VERSION ""

NS_ :

BS_:

BU_: GWM SCMB_PSM HVAC_RCCM GENERIC_GWMWakeup SOBDMD_AHCM_FOH TRM _delete SODL RTM PDM SCMH SCMG RSM SODR DDM RGTM DSM SCME TSTR

BO_ 947 BodyInfo_3_MS1: 8 GWM
 SG_ DrStatDrvErrCnt_B_Stat : 19|1@0+ (1,0) [0|1] "SED" Vector__XXX
 SG_ TurnLghtRightOn_B_Stat : 35|1@0+ (1,0) [0|1] "SED" Vector__XXX
 SG_ TurnLghtLeftOn_B_Stat : 54|1@0+ (1,0) [0|1] "SED" Vector__XXX
 SG_ Backlit_LED_Status : 23|4@0+ (1,0) [0|15] "SED"  HVAC_RCCM,DDM,PDM
 SG_ FogLghtRearOn_B_Stat : 1|1@0+ (1,0) [0|1] "SED"  TRM
 SG_ ValetMode_D_Mem : 16|1@0+ (1,0) [0|1] "SED"  RGTM
 SG_ IgnKeyType_D_Actl : 39|4@0+ (1,0) [0|15] "SED"  RSM,SODL,SODR
 SG_ TurnLghtRight_D_Rq : 63|2@0+ (1,0) [0|3] "SED"  RSM,DDM,PDM,TRM
 SG_ Parklamp_Status : 3|2@0+ (1,0) [0|3] "SED"  HVAC_RCCM,TRM,PDM,DDM,SODL,SODR
 SG_ Litval : 47|8@0+ (1,0) [0|253] "SED"  HVAC_RCCM,DDM,PDM,SODL,SODR
 SG_ Key_In_Ignition_Stat : 11|1@0+ (1,0) [0|1] "SED"  RSM,SCMG,SCMH,DSM,RTM
 SG_ Ignition_Status : 7|4@0+ (1,0) [0|15] "SED"  SCMB_PSM,SCME,HVAC_RCCM,RSM,DDM,DSM,PDM,RGTM,RTM,SCMG,SCMH,TRM,SOBDMD_AHCM_FOH,SODL,SODR
 SG_ Dimming_Lvl : 31|8@0+ (1,0) [0|253] "SED"  HVAC_RCCM,DDM,PDM
 SG_ Day_Night_Status : 15|2@0+ (1,0) [0|3] "SED"  HVAC_RCCM,DDM,PDM
 SG_ Remote_Start_Status : 13|2@0+ (1,0) [0|3] "SED"  HVAC_RCCM,RSM
 SG_ DrStatTgate_B_Actl : 0|1@0+ (1,0) [0|1] "SED"  RSM,TRM,HVAC_RCCM
 SG_ DrStatRr_B_Actl : 49|1@0+ (1,0) [0|1] "SED"  HVAC_RCCM,RGTM,DDM,PDM,RSM
 SG_ DrStatRl_B_Actl : 48|1@0+ (1,0) [0|1] "SED"  HVAC_RCCM,RGTM,DDM,PDM,RSM
 SG_ DrStatPsngr_B_Actl : 60|1@0+ (1,0) [0|1] "SED"  RGTM,DDM,PDM,RSM,HVAC_RCCM
 SG_ DrStatInnrTgate_B_Actl : 58|1@0+ (1,0) [0|1] "SED"  TRM,RSM,HVAC_RCCM
 SG_ DrStatHood_B_Actl : 59|1@0+ (1,0) [0|1] "SED"  RSM
 SG_ DrStatDrv_B_Actl : 61|1@0+ (1,0) [0|1] "SED"  RGTM,HVAC_RCCM,DDM,PDM,RSM,DSM
 SG_ PrkBrkActv_B_Actl : 55|1@0+ (1,0) [0|1] "SED"  SODL,SODR
 SG_ LifeCycMde_D_Actl : 53|4@0+ (1,0) [0|15] "SED"  HVAC_RCCM,RGTM,TRM,RTM,DDM,PDM,SOBDMD_AHCM_FOH
 SG_ Delay_Accy : 57|1@0+ (1,0) [0|1] "SED"  DDM,PDM
 SG_ FogLghtFrontOn_B_Stat : 56|1@0+ (1,0) [0|1] "SED" Vector__XXX
 SG_ TurnLghtLeft_D_Rq : 9|2@0+ (1,0) [0|3] "SED"  RSM,DDM,PDM,TRM
 SG_ CrashEvnt_D_Stat : 34|2@0+ (1,0) [0|3] "SED"  HVAC_RCCM
 SG_ FuelPmpInhbt_B_Stat : 32|1@0+ (1,0) [0|1] "SED"  HVAC_RCCM
 SG_ BodySrvcRqd_B_Rq : 10|1@0+ (1,0) [0|1] "SED" Vector__XXX

BO_ 293 ClmtCtrlSeatSet_Stat_v2: 8 SCME
 SG_ ClmtCtrlSeat_SetStat_Psgr : 15|8@0+ (1,0) [0|254] "SED"  GWM,HVAC_RCCM
 SG_ ClmtCtrlSeat_SetStat_Dvr : 7|8@0+ (1,0) [0|254] "SED"  GWM,HVAC_RCCM

BO_ 292 ClmtCtrlSeatSet_Cmd: 8 HVAC_RCCM
 SG_ ClmtCtrlSeat_SetCmd_Psgr : 15|8@0+ (1,0) [0|254] "SED"  GWM,SCME
 SG_ ClmtCtrlSeat_SetCmd_Dvr : 7|8@0+ (1,0) [0|254] "SED"  GWM,SCME

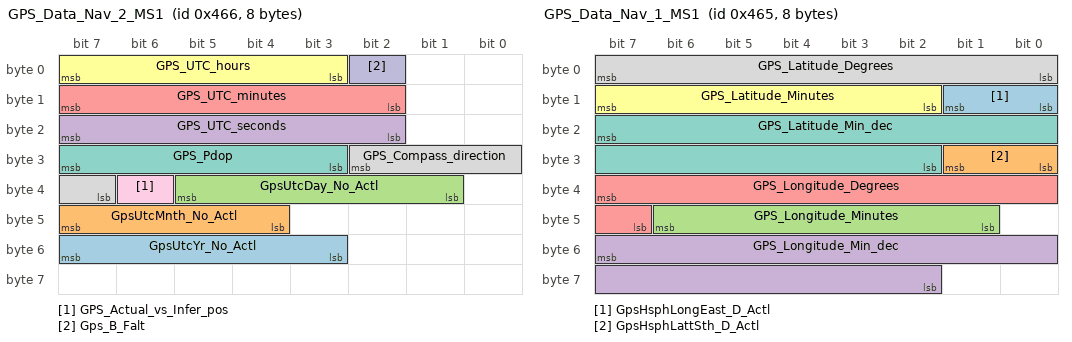
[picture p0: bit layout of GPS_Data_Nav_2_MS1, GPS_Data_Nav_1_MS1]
BO_ 1126 GPS_Data_Nav_2_MS1: 8 GWM
 SG_ GpsUtcYr_No_Actl : 55|5@0+ (1,2010) [2010|2040] "Year" Vector__XXX
 SG_ GpsUtcMnth_No_Actl : 47|4@0+ (1,1) [1|15] "Month" Vector__XXX
 SG_ GpsUtcDay_No_Actl : 37|5@0+ (1,1) [1|32] "Day" Vector__XXX
 SG_ GPS_UTC_seconds : 23|6@0+ (1,0) [0|59] "seconds" Vector__XXX
 SG_ GPS_UTC_minutes : 15|6@0+ (1,0) [0|59] "Minutes" Vector__XXX
 SG_ GPS_UTC_hours : 7|5@0+ (1,0) [0|23] "Hours" Vector__XXX
 SG_ GPS_Pdop : 31|5@0+ (0.2,0) [0|5.8] "unitless" Vector__XXX
 SG_ GPS_Compass_direction : 26|4@0+ (1,0) [0|15] "SED" Vector__XXX
 SG_ GPS_Actual_vs_Infer_pos : 38|1@0+ (1,0) [0|1] "SED" Vector__XXX
 SG_ Gps_B_Falt : 2|1@0+ (1,0) [0|1] "SED" Vector__XXX

BO_ 1125 GPS_Data_Nav_1_MS1: 8 GWM
 SG_ GpsHsphLongEast_D_Actl : 9|2@0+ (1,0) [0|3] "SED" Vector__XXX
 SG_ GpsHsphLattSth_D_Actl : 25|2@0+ (1,0) [0|3] "SED" Vector__XXX
 SG_ GPS_Longitude_Minutes : 46|6@0+ (1,0) [0|61] "Minutes" Vector__XXX
 SG_ GPS_Longitude_Min_dec : 55|14@0+ (0.0001,0) [0|1.6381] "Minutes" Vector__XXX
 SG_ GPS_Longitude_Degrees : 39|9@0+ (1,-179) [-179|330] "Degrees" Vector__XXX
 SG_ GPS_Latitude_Minutes : 15|6@0+ (1,0) [0|61] "Minutes" Vector__XXX
 SG_ GPS_Latitude_Min_dec : 23|14@0+ (0.0001,0) [0|1.6381] "Minutes" Vector__XXX
 SG_ GPS_Latitude_Degrees : 7|8@0+ (1,-89) [-89|164] "Degrees" Vector__XXX

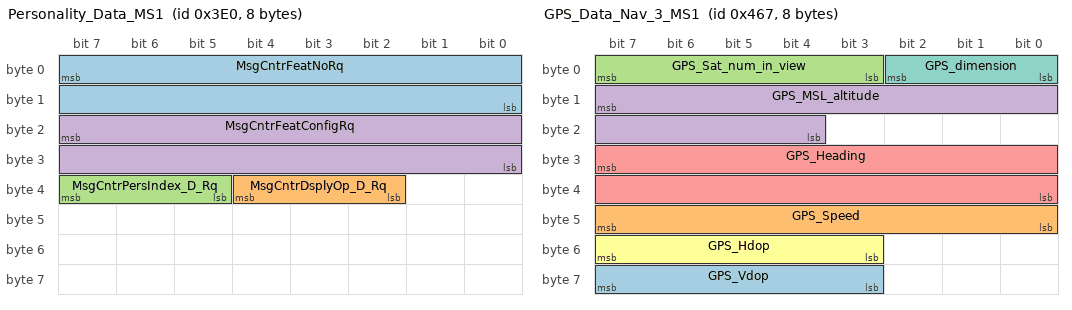
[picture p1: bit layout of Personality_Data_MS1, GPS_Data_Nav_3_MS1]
BO_ 992 Personality_Data_MS1: 8 GWM
 SG_ MsgCntrFeatNoRq : 7|16@0+ (1,0) [0|65535] "Number"  HVAC_RCCM,PDM,DDM,DSM
 SG_ MsgCntrDsplyOp_D_Rq : 36|3@0+ (1,0) [0|7] "SED"  HVAC_RCCM,PDM,DDM,DSM
 SG_ MsgCntrPersIndex_D_Rq : 39|3@0+ (1,0) [0|7] "SED"  HVAC_RCCM,PDM,DDM,DSM
 SG_ MsgCntrFeatConfigRq : 23|16@0+ (1,0) [0|65535] "unitless"  HVAC_RCCM,PDM,DDM,DSM

BO_ 1127 GPS_Data_Nav_3_MS1: 8 GWM
 SG_ GPS_Vdop : 63|5@0+ (0.2,0) [0|5.8] "unitless" Vector__XXX
 SG_ GPS_Speed : 47|8@0+ (1,0) [0|253] "MPH" Vector__XXX
 SG_ GPS_Sat_num_in_view : 7|5@0+ (1,0) [0|29] "unitless" Vector__XXX
 SG_ GPS_MSL_altitude : 15|12@0+ (10,-20460) [-20460|20470] "feet" Vector__XXX
 SG_ GPS_Heading : 31|16@0+ (0.01,0) [0|655.33] "Degrees" Vector__XXX
 SG_ GPS_Hdop : 55|5@0+ (0.2,0) [0|5.8] "unitless" Vector__XXX
 SG_ GPS_dimension : 2|3@0+ (1,0) [0|7] "SED" Vector__XXX

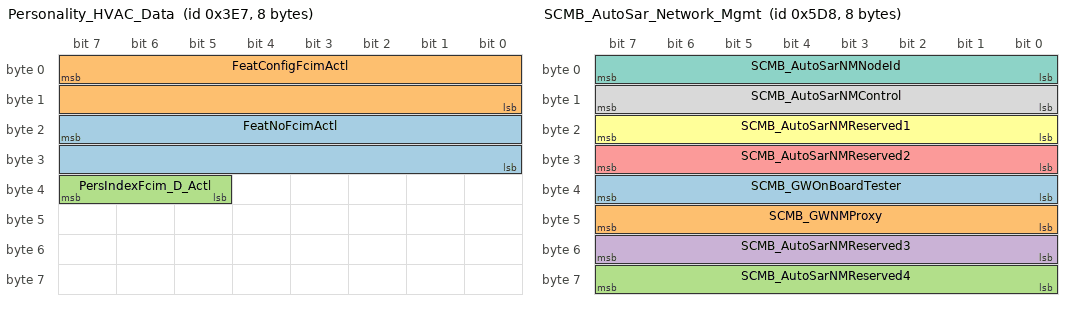
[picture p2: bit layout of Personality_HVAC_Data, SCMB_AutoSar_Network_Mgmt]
BO_ 999 Personality_HVAC_Data: 8 HVAC_RCCM
 SG_ FeatNoFcimActl : 23|16@0+ (1,0) [0|65535] "Number"  GWM
 SG_ FeatConfigFcimActl : 7|16@0+ (1,0) [0|65535] "Undefined"  GWM
 SG_ PersIndexFcim_D_Actl : 39|3@0+ (1,0) [0|7] "SED"  GWM

BO_ 1998 TesterPhysicalResSODR: 8 SODR
 SG_ TesterPhysicalResSODR : 7|64@0+ (1,0) [0|1.84467E+019] "unitless"  TSTR

BO_ 1990 TesterPhysicalReqSODR: 8 TSTR
 SG_ TesterPhysicalReqSODR : 7|64@0+ (1,0) [0|1.84467E+019] "unitless"  SODR

BO_ 1996 TesterPhysicalResSODL: 8 SODL
 SG_ TesterPhysicalResSODL : 7|64@0+ (1,0) [0|1.84467E+019] "unitless"  TSTR

BO_ 1988 TesterPhysicalReqSODL: 8 TSTR
 SG_ TesterPhysicalReqSODL : 7|64@0+ (1,0) [0|1.84467E+019] "unitless"  SODL

BO_ 2027 TesterPhysicalResAHCM: 8 SOBDMD_AHCM_FOH
 SG_ TesterPhysicalResAHCM : 7|64@0+ (1,0) [0|1.84467E+019] "unitless"  TSTR

BO_ 1496 SCMB_AutoSar_Network_Mgmt: 8 SCMB_PSM
 SG_ SCMB_GWOnBoardTester : 39|8@0+ (1,0) [0|255] "unitless"  GWM
 SG_ SCMB_GWNMProxy : 47|8@0+ (1,0) [0|255] "unitless"  GWM
 SG_ SCMB_AutoSarNMReserved4 : 63|8@0+ (1,0) [0|255] "unitless"  GWM
 SG_ SCMB_AutoSarNMReserved3 : 55|8@0+ (1,0) [0|255] "unitless"  GWM
 SG_ SCMB_AutoSarNMReserved2 : 31|8@0+ (1,0) [0|255] "unitless"  GWM
 SG_ SCMB_AutoSarNMReserved1 : 23|8@0+ (1,0) [0|255] "unitless"  GWM
 SG_ SCMB_AutoSarNMNodeId : 7|8@0+ (1,0) [0|255] "unitless"  GWM
 SG_ SCMB_AutoSarNMControl : 15|8@0+ (1,0) [0|255] "unitless"  GWM

BO_ 847 PwrFoldSeats: 8 GENERIC_GWMWakeup
 SG_ FldngSeatPwOffOk_B_Stat : 7|1@0+ (1,0) [0|0] "SED"  GWM

BO_ 2019 TesterPhysicalReqAHCM: 8 TSTR
 SG_ TesterPhysicalReqAHCM : 7|64@0+ (1,0) [0|1.84467E+019] "unitless"  SOBDMD_AHCM_FOH

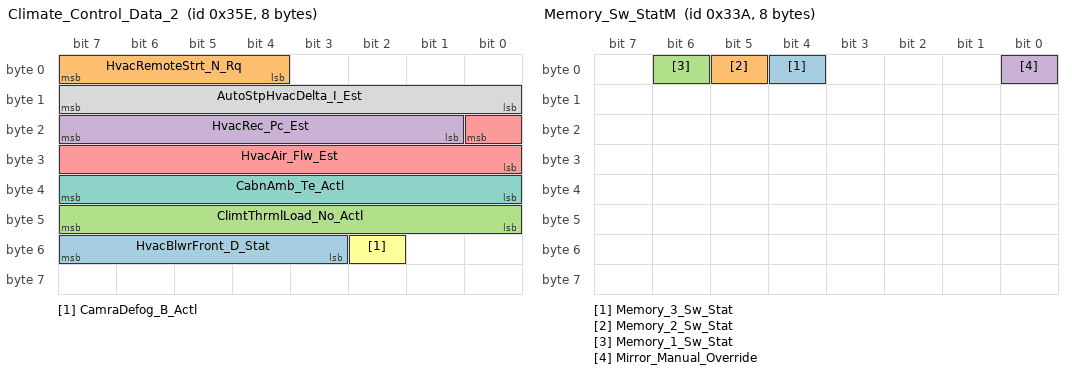
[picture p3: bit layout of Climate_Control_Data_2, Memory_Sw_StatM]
BO_ 862 Climate_Control_Data_2: 8 HVAC_RCCM
 SG_ HvacBlwrFront_D_Stat : 55|5@0+ (1,0) [0|31] "SED"  SCME,RGTM,GWM
 SG_ HvacRemoteStrt_N_Rq : 7|4@0+ (100,450) [450|1950] "RPM"  GWM
 SG_ ClimtThrmlLoad_No_Actl : 47|8@0+ (1,0) [0|254] "unitless"  GWM
 SG_ HvacRec_Pc_Est : 23|7@0+ (1,0) [0|127] "Percent"  GWM
 SG_ HvacAir_Flw_Est : 16|9@0+ (0.5,0) [0|255.5] "liter/second"  GWM
 SG_ CamraDefog_B_Actl : 50|1@0+ (1,0) [0|1] "SED"  GWM
 SG_ CabnAmb_Te_Actl : 39|8@0+ (0.5,-57) [-57|70] "degreesC"  SCME,RGTM,SOBDMD_AHCM_FOH,GWM
 SG_ AutoStpHvacDelta_I_Est : 15|8@0+ (1,-192) [-192|62] "ampere"  GWM

BO_ 828 Pass_Window_Stat: 8 PDM
 SG_ RearPassWindowPos : 4|3@0+ (1,0) [0|7] "SED"  RGTM,HVAC_RCCM,GWM
 SG_ PassWindowPosition : 7|3@0+ (1,0) [0|7] "SED"  RGTM,HVAC_RCCM,GWM

BO_ 1909 TesterPhysicalReqRGTM: 8 TSTR
 SG_ TesterPhysicalReqRGTM : 7|64@0+ (1,0) [0|1.84467E+019] "unitless"  RGTM

BO_ 1917 TesterPhysicalResRGTM: 8 RGTM
 SG_ TesterPhysicalResRGTM : 7|64@0+ (1,0) [0|1.84467E+019] "unitless"  TSTR

BO_ 1860 TesterPhysicalReqDSM: 8 TSTR
 SG_ TesterPhysicalReqDSM : 7|64@0+ (1,0) [0|1.84467E+019] "unitless"  DSM

BO_ 1868 TesterPhysicalResDSM: 8 DSM
 SG_ TesterPhysicalResDSM : 7|64@0+ (1,0) [0|1.84467E+019] "unitless"  TSTR

BO_ 1918 TesterPhysicalResSCME: 8 SCME
 SG_ TesterPhysicalResSCME : 7|64@0+ (1,0) [0|1.84467E+019] "unitless"  TSTR

BO_ 1910 TesterPhysicalReqSCME: 8 TSTR
 SG_ TesterPhysicalReqSCME : 7|64@0+ (1,0) [0|1.84467E+019] "unitless"  SCME

BO_ 1814 TesterPhysicalReqGWM_M1: 8 TSTR
 SG_ TesterPhysicalReqGWM_M1 : 7|64@0+ (1,0) [0|1.84467E+019] "unitless"  GWM

BO_ 1822 TesterPhysicalResGWM_MS1: 8 GWM
 SG_ TesterPhysicalResGWM_M1 : 7|64@0+ (1,0) [0|1.84467E+019] "unitless"  TSTR

BO_ 826 Memory_Sw_StatM: 8 DDM
 SG_ Memory_3_Sw_Stat : 4|1@0+ (1,0) [0|1] "SED"  GWM,DSM
 SG_ Memory_2_Sw_Stat : 5|1@0+ (1,0) [0|1] "SED"  GWM,DSM
 SG_ Memory_1_Sw_Stat : 6|1@0+ (1,0) [0|1] "SED"  GWM,DSM
 SG_ Mirror_Manual_Override : 0|1@0+ (1,0) [0|1] "SED"  GWM,DSM

BO_ 1289 AHCM_Network_MgmtM: 8 SOBDMD_AHCM_FOH
 SG_ AHCM_Network_Mgmt : 7|8@0+ (1,0) [0|254] "unitless" Vector__XXX

BO_ 853 Clmt_Button_Stat1: 8 HVAC_RCCM
 SG_ Front_AUTO_Blwr_Lvl : 60|2@0+ (1,0) [0|3] "SED"  GWM
 SG_ FrontMnu_Buttn_Stat : 49|1@0+ (1,0) [0|1] "SED"  GWM
 SG_ RHS_Cond_Seat_Status : 63|3@0+ (1,0) [0|7] "SED"  GWM
 SG_ LHS_Cond_Seat_Status : 10|3@0+ (1,0) [0|7] "SED"  GWM
 SG_ Htd_Strg_Whl_Status : 27|2@0+ (1,0) [0|3] "SED"  GWM
 SG_ Htd_Strg_Whl_Btn_Stt : 29|2@0+ (1,0) [0|3] "SED"  GWM
 SG_ Defrost_Btn_Stt : 3|2@0+ (1,0) [0|3] "SED"  GWM
 SG_ CC_Fr_Btn_User_Adj : 15|5@0+ (1,0) [0|31] "SED"  GWM
 SG_ RHS_Htd_Seat_Btn_Stt : 53|2@0+ (1,0) [0|3] "SED"  GWM
 SG_ RHS_Cld_Seat_Btn_Stt : 55|2@0+ (1,0) [0|3] "SED"  GWM
 SG_ Outside_Btn_Stt : 47|2@0+ (1,0) [0|3] "SED"  GWM
 SG_ LHS_Htd_Seat_Btn_Stt : 39|2@0+ (1,0) [0|3] "SED"  GWM
 SG_ LHS_Cld_Seat_Btn_Stt : 25|2@0+ (1,0) [0|3] "SED"  GWM
 SG_ Htd_Frt_Wsh_Btn_Stt : 31|2@0+ (1,0) [0|3] "SED"  GWM
 SG_ Auto_Recirc_Btn_Stt : 5|2@0+ (1,0) [0|3] "SED"  GWM
 SG_ Windscreen_Btn_Stt : 51|2@0+ (1,0) [0|3] "SED"  GWM
 SG_ Panel_Btn_Stt : 45|2@0+ (1,0) [0|3] "SED"  GWM
 SG_ Front_Power_Btn_Stt : 17|2@0+ (1,0) [0|3] "SED"  GWM
 SG_ Front_AUTO_Btn_Stt : 21|2@0+ (1,0) [0|3] "SED"  GWM
 SG_ Floor_Btn_Stt : 23|2@0+ (1,0) [0|3] "SED"  GWM
 SG_ Dual_Button_Stt : 1|2@0+ (1,0) [0|3] "SED"  GWM
 SG_ AC_Btn_Stt : 7|2@0+ (1,0) [0|3] "SED"  GWM
 SG_ Recirc_Btn_Stt : 41|2@0+ (1,0) [0|3] "SED"  RGTM,GWM
 SG_ Rear_Defrost_Btn_Stt : 43|2@0+ (1,0) [0|3] "SED"  GWM
 SG_ My_Temp_Btn_Stt : 33|2@0+ (1,0) [0|3] "SED"  GWM
 SG_ Max_Defrost_Btn_Stt : 35|2@0+ (1,0) [0|3] "SED"  GWM
 SG_ Max_AC_Btn_Stt : 37|2@0+ (1,0) [0|3] "SED"  GWM
 SG_ Front_AUTO_Label : 19|2@0+ (1,0) [0|3] "SED"  GWM

BO_ 1034 GGCC_Config_Mgmt_ID_1_MS1: 8 GWM
 SG_ VehicleGGCCData : 7|64@0+ (1,0) [0|1.84467E+019] "mixed"  HVAC_RCCM,TRM,PDM,SOBDMD_AHCM_FOH,RTM,DDM,RGTM,SODL,SODR

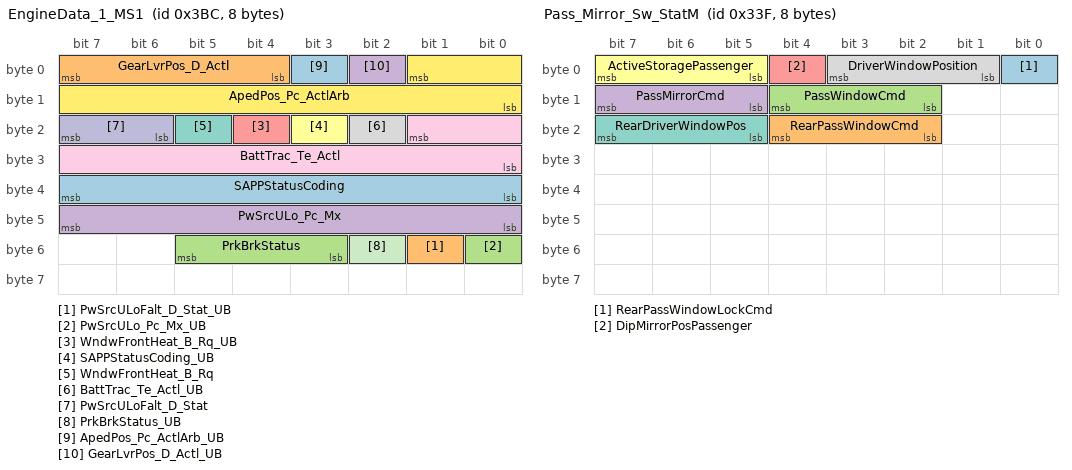
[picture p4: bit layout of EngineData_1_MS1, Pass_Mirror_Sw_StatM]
BO_ 956 EngineData_1_MS1: 8 GWM
 SG_ SAPPStatusCoding : 39|8@0+ (1,0) [0|255] "unitless" Vector__XXX
 SG_ PwSrcULoFalt_D_Stat_UB : 49|1@0+ (1,0) [0|1] "SED"  HVAC_RCCM
 SG_ PwSrcULo_Pc_Mx_UB : 48|1@0+ (1,0) [0|1] "SED"  HVAC_RCCM
 SG_ PwSrcULo_Pc_Mx : 47|8@0+ (0.4,0) [0|101.6] "%"  HVAC_RCCM
 SG_ WndwFrontHeat_B_Rq_UB : 20|1@0+ (1,0) [0|1] "SED"  HVAC_RCCM
 SG_ SAPPStatusCoding_UB : 19|1@0+ (1,0) [0|1] "SED" Vector__XXX
 SG_ WndwFrontHeat_B_Rq : 21|1@0+ (1,0) [0|1] "SED"  HVAC_RCCM
 SG_ BattTrac_Te_Actl_UB : 18|1@0+ (1,0) [0|1] "SED"  HVAC_RCCM
 SG_ BattTrac_Te_Actl : 17|10@0+ (0.5,-50) [-50|460.5] "degC"  HVAC_RCCM
 SG_ PwSrcULoFalt_D_Stat : 23|2@0+ (1,0) [0|3] "SED"  HVAC_RCCM
 SG_ PrkBrkStatus_UB : 50|1@0+ (1,0) [0|1] "SED"  HVAC_RCCM
 SG_ ApedPos_Pc_ActlArb : 1|10@0+ (0.1,0) [0|102.3] "%"  HVAC_RCCM
 SG_ ApedPos_Pc_ActlArb_UB : 3|1@0+ (1,0) [0|1] "SED"  HVAC_RCCM
 SG_ GearLvrPos_D_Actl : 7|4@0+ (1,0) [0|15] "SED"  HVAC_RCCM,RGTM,DSM,SCMG,SCMH,DDM,PDM,SODR,SODL
 SG_ PrkBrkStatus : 53|3@0+ (1,0) [0|7] "SED"  HVAC_RCCM
 SG_ GearLvrPos_D_Actl_UB : 2|1@0+ (1,0) [0|1] "SED"  HVAC_RCCM,RGTM,DSM,SCMG,SCMH,DDM,PDM,SODL,SODR

BO_ 831 Pass_Mirror_Sw_StatM: 8 DDM
 SG_ RearPassWindowLockCmd : 0|1@0+ (1,0) [0|1] "SED"  GWM,PDM
 SG_ RearPassWindowCmd : 20|3@0+ (1,0) [0|7] "SED"  GWM,PDM
 SG_ PassWindowCmd : 12|3@0+ (1,0) [0|7] "SED"  GWM,PDM
 SG_ PassMirrorCmd : 15|3@0+ (1,0) [0|7] "SED"  GWM,PDM
 SG_ DipMirrorPosPassenger : 4|1@0+ (1,0) [0|1] "SED"  GWM,PDM
 SG_ ActiveStoragePassenger : 7|3@0+ (1,0) [0|7] "SED"  GWM,PDM
 SG_ RearDriverWindowPos : 23|3@0+ (1,0) [0|7] "SED"  RGTM,HVAC_RCCM,GWM
 SG_ DriverWindowPosition : 3|3@0+ (1,0) [0|7] "SED"  RGTM,HVAC_RCCM,GWM

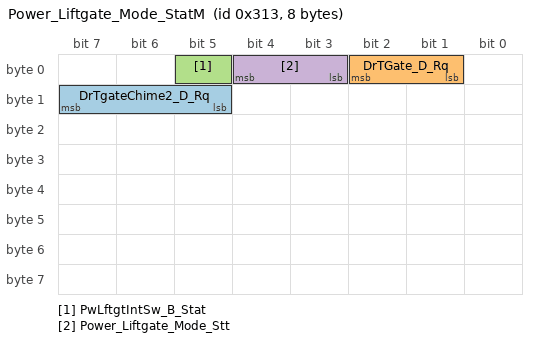
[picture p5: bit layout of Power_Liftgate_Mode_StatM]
BO_ 787 Power_Liftgate_Mode_StatM: 8 RGTM
 SG_ DrTgateChime2_D_Rq : 15|3@0+ (1,0) [0|7] "SED"  GWM
 SG_ DrTGate_D_Rq : 2|2@0+ (1,0) [0|3] "SED"  HVAC_RCCM,GWM
 SG_ PwLftgtIntSw_B_Stat : 5|1@0+ (1,0) [0|1] "SED"  GWM
 SG_ Power_Liftgate_Mode_Stt : 4|2@0+ (1,0) [0|3] "SED"  GWM

BO_ 1291 DSM_Network_MgmtM: 8 DSM
 SG_ DSM_Network_Mgmt : 7|8@0+ (1,0) [0|254] "unitless"  PDM,DDM

CM_ SG_ 947 Dimming_Lvl "Refer to Vehicle Interior Illum Dimming Ctrl Sys Eng Spec, Table 2

";
CM_ SG_ 947 PrkBrkActv_B_Actl "Signal not transmitted on vehicles with electric park brake. ";
CM_ BO_ 1126 "HS3 APIM Sync Gen3 Tx 0x463.  FrameGateway to 0x466 on HS1, HS2, HS3 and MS1.";
CM_ BO_ 1125 "HS3 APIM Sync Gen3 Tx 0x462.  FrameGateway to 0x465 on HS1, HS2, HS3 and MS1.";
CM_ BO_ 1127 "HS3 APIM Sync Gen3 Tx 0x464.  FrameGateway to 0x467 on HS1, HS2, HS3 and MS1.";
CM_ BO_ 828 "Set GenSigSendType = NoSigSendType (Cyclic) for the following signals, D.Card 3/31/08
Driver_Lock_Sw_Stat
";
CM_ SG_ 1034 VehicleGGCCData "RCMGenSigTimeout=6000";
CM_ SG_ 956 ApedPos_Pc_ActlArb "ABSGenSigTimeoutTime=1000";
BA_DEF_ BO_  "FrameGatewayNetwork" STRING ;
BA_DEF_ BO_  "FrameGatewayMS1" HEX 0 1407;
BA_DEF_ BO_  "NetworkInitialization" ENUM  "No","Yes";
BA_DEF_ BO_  "FrameGatewayId" HEX 0 1407;
BA_DEF_ BO_  "EventRateOfChange" INT 10 10000;
BA_DEF_ BO_  "GenMsgStartDelayTime" INT 0 10000;
BA_DEF_ BO_  "GenMsgNrOfRepetition" INT 0 100;
BA_DEF_ BO_  "GenMsgDelayTime" INT 0 1000;
BA_DEF_ BO_  "GenMsgCycleTime" INT 0 100000;
BA_DEF_ BO_  "GenMsgSendType" ENUM  "FixedPeriodic","Event","EnabledPeriodic","NotUsed","NotUsed","EventPeriodic","NotUsed","NotUsed","NoMsgSendType";
BA_DEF_ SG_  "U_P702_MY2021_Tx" ENUM  "No","Yes";
BA_DEF_ SG_  "U_CX727_MY2021_Tx" ENUM  "No","Yes";
BA_DEF_ SG_  "U_VN127_MY20_Tx" ENUM  "No","Yes";
BA_DEF_ SG_  "U_H567_MY20_Tx" ENUM  "No","Yes";
BA_DEF_ SG_  "U_CX430_MY2021_Tx" ENUM  "No","Yes";
BA_DEF_ SG_  "U_U611_U625_MY20_Phev_Tx" ENUM  "No","Yes";
BA_DEF_ SG_  "U_B562_MY18_Diesel_Tx" ENUM  "No","Yes";
BA_DEF_ SG_  "U_CX482_CX483_MY20_Tx" ENUM  "No","Yes";
BA_DEF_ SG_  "U_U611_U625_MY20_Hev_Tx" ENUM  "No","Yes";
BA_DEF_ SG_  "U_U611_U625_MY20_Gas_Tx" ENUM  "No","Yes";
BA_DEF_ SG_  "U_B500_MY18_Diesel_Tx" ENUM  "No","Yes";
BA_DEF_ SG_  "U_B500_MY18_Gas_Tx" ENUM  "No","Yes";
BA_DEF_ SG_  "U_C490_MY18_Tx" ENUM  "No","Yes";
BA_DEF_ SG_  "U_B562_MY18_Gas_Tx" ENUM  "No","Yes";
BA_DEF_ SG_  "U_C519_MY18_5_Gas_Tx" ENUM  "No","Yes";
BA_DEF_ SG_  "U_C519_MY18_5_Diesel_Tx" ENUM  "No","Yes";
BA_DEF_ SG_  "U_B515_MCA_MY17_Gas_Tx" ENUM  "No","Yes";
BA_DEF_ SG_  "U_B515_MCA_MY17_Diesel_Tx" ENUM  "No","Yes";
BA_DEF_ SG_  "U_B479_MY17_Diesel_Tx" ENUM  "No","Yes";
BA_DEF_ SG_  "U_B479_MY17_Gas_Tx" ENUM  "No","Yes";
BA_DEF_ SG_  "U_P702_MY2021_Rx" ENUM  "No","Yes";
BA_DEF_ SG_  "U_CX727_MY2021_Rx" ENUM  "No","Yes";
BA_DEF_ SG_  "U_VN127_MY20_Rx" ENUM  "No","Yes";
BA_DEF_ SG_  "U_H567_MY20_Rx" ENUM  "No","Yes";
BA_DEF_ SG_  "U_CX430_MY2021_Rx" ENUM  "No","Yes";
BA_DEF_ SG_  "U_U611_U625_MY20_Phev_Rx" ENUM  "No","Yes";
BA_DEF_ SG_  "U_B562_MY18_Diesel_Rx" ENUM  "No","Yes";
BA_DEF_ SG_  "U_CX482_CX483_MY20_Rx" ENUM  "No","Yes";
BA_DEF_ SG_  "U_U611_U625_MY20_Hev_Rx" ENUM  "No","Yes";
BA_DEF_ SG_  "U_U611_U625_MY20_Gas_Rx" ENUM  "No","Yes";
BA_DEF_ SG_  "U_B500_MY18_Diesel_Rx" ENUM  "No","Yes";
BA_DEF_ SG_  "U_B500_MY18_Gas_Rx" ENUM  "No","Yes";
BA_DEF_ SG_  "U_C490_MY18_Rx" ENUM  "No","Yes";
BA_DEF_ SG_  "U_B562_MY18_Gas_Rx" ENUM  "No","Yes";
BA_DEF_ SG_  "U_LC1_B515_MY17_Gas_Rx" ENUM  "No","Yes";
BA_DEF_ SG_  "U_LC1_B515_MY17_Diesel_Rx" ENUM  "No","Yes";
BA_DEF_ SG_  "U_C519_MY18_5_Gas_Rx" ENUM  "No","Yes";
BA_DEF_ SG_  "U_C519_MY18_5_Diesel_Rx" ENUM  "No","Yes";
BA_DEF_ SG_  "U_B515_MCA_MY17_Gas_Rx" ENUM  "No","Yes";
BA_DEF_ SG_  "U_B515_MCA_MY17_Diesel_Rx" ENUM  "No","Yes";
BA_DEF_ SG_  "U_B479_MY17_Diesel_Rx" ENUM  "No","Yes";
BA_DEF_ SG_  "U_B479_MY17_Gas_Rx" ENUM  "No","Yes";
BA_DEF_ SG_  "U_B562LC_MY15_Gas_Rx" ENUM  "No","Yes";
BA_DEF_ SG_  "U_B562LC_MY15_Diesel_Rx" ENUM  "No","Yes";
BA_DEF_ SG_  "GenSigStartValue" HEX 0 268435455;
BA_DEF_ SG_  "MetaData" ENUM  "No","Yes";
BA_DEF_ SG_  "ContentDependant" ENUM  "No","Yes";
BA_DEF_ SG_  "GenSigStartValueInteger" INT 0 1000000000;
BA_DEF_ SG_  "UsedOnPgmDBC" ENUM  "No","Yes";
BA_DEF_ SG_  "CrossOver_InfoCAN" ENUM  "No","Yes";
BA_DEF_ SG_  "WakeupSignal" ENUM  "No","Yes";
BA_DEF_ SG_  "GenSigInactiveValue" INT 0 100000;
BA_DEF_ SG_  "GenSigSendType" ENUM  "Cyclic","OnWrite","vector_leerstring","OnChange","vector_leerstring","IfActive","vector_leerstring","NoSigSendType";
BA_DEF_ BO_  "AuthFreshnessCounterSyncAttempt" INT 0 2;
BA_DEF_ BO_  "GenMsgRoutingTimeoutTime" INT 0 5000;
BA_DEF_ BO_  "MessageGateway" ENUM  "No","Yes";
BA_DEF_ BO_  "NmAsrMessage" ENUM  "No","Yes";
BA_DEF_ BO_  "DiagState" ENUM  "No","Yes";
BA_DEF_ BO_  "DiagRequest" ENUM  "No","Yes";
BA_DEF_ BO_  "DiagResponse" ENUM  "No","Yes";
BA_DEF_ BO_  "NmMessage" ENUM  "No","Yes";
BA_DEF_ BO_  "GenMsgILSupport" ENUM  "No","Yes";
BA_DEF_DEF_  "FrameGatewayNetwork" "NONE";
BA_DEF_DEF_  "FrameGatewayMS1" 0;
BA_DEF_DEF_  "NetworkInitialization" "Yes";
BA_DEF_DEF_  "FrameGatewayId" 0;
BA_DEF_DEF_  "EventRateOfChange" 10000;
BA_DEF_DEF_  "GenMsgStartDelayTime" 0;
BA_DEF_DEF_  "GenMsgNrOfRepetition" 1;
BA_DEF_DEF_  "GenMsgDelayTime" 20;
BA_DEF_DEF_  "GenMsgCycleTime" 0;
BA_DEF_DEF_  "GenMsgSendType" "NoMsgSendType";
BA_DEF_DEF_  "U_P702_MY2021_Tx" "No";
BA_DEF_DEF_  "U_CX727_MY2021_Tx" "No";
BA_DEF_DEF_  "U_VN127_MY20_Tx" "No";
BA_DEF_DEF_  "U_H567_MY20_Tx" "No";
BA_DEF_DEF_  "U_CX430_MY2021_Tx" "No";
BA_DEF_DEF_  "U_U611_U625_MY20_Phev_Tx" "No";
BA_DEF_DEF_  "U_B562_MY18_Diesel_Tx" "No";
BA_DEF_DEF_  "U_CX482_CX483_MY20_Tx" "No";
BA_DEF_DEF_  "U_U611_U625_MY20_Hev_Tx" "No";
BA_DEF_DEF_  "U_U611_U625_MY20_Gas_Tx" "No";
BA_DEF_DEF_  "U_B500_MY18_Diesel_Tx" "No";
BA_DEF_DEF_  "U_B500_MY18_Gas_Tx" "No";
BA_DEF_DEF_  "U_C490_MY18_Tx" "No";
BA_DEF_DEF_  "U_B562_MY18_Gas_Tx" "No";
BA_DEF_DEF_  "U_C519_MY18_5_Gas_Tx" "No";
BA_DEF_DEF_  "U_C519_MY18_5_Diesel_Tx" "No";
BA_DEF_DEF_  "U_B515_MCA_MY17_Gas_Tx" "No";
BA_DEF_DEF_  "U_B515_MCA_MY17_Diesel_Tx" "No";
BA_DEF_DEF_  "U_B479_MY17_Diesel_Tx" "No";
BA_DEF_DEF_  "U_B479_MY17_Gas_Tx" "No";
BA_DEF_DEF_  "U_P702_MY2021_Rx" "No";
BA_DEF_DEF_  "U_CX727_MY2021_Rx" "No";
BA_DEF_DEF_  "U_VN127_MY20_Rx" "No";
BA_DEF_DEF_  "U_H567_MY20_Rx" "No";
BA_DEF_DEF_  "U_CX430_MY2021_Rx" "No";
BA_DEF_DEF_  "U_U611_U625_MY20_Phev_Rx" "No";
BA_DEF_DEF_  "U_B562_MY18_Diesel_Rx" "No";
BA_DEF_DEF_  "U_CX482_CX483_MY20_Rx" "No";
BA_DEF_DEF_  "U_U611_U625_MY20_Hev_Rx" "No";
BA_DEF_DEF_  "U_U611_U625_MY20_Gas_Rx" "No";
BA_DEF_DEF_  "U_B500_MY18_Diesel_Rx" "No";
BA_DEF_DEF_  "U_B500_MY18_Gas_Rx" "No";
BA_DEF_DEF_  "U_C490_MY18_Rx" "No";
BA_DEF_DEF_  "U_B562_MY18_Gas_Rx" "No";
BA_DEF_DEF_  "U_LC1_B515_MY17_Gas_Rx" "No";
BA_DEF_DEF_  "U_LC1_B515_MY17_Diesel_Rx" "No";
BA_DEF_DEF_  "U_C519_MY18_5_Gas_Rx" "No";
BA_DEF_DEF_  "U_C519_MY18_5_Diesel_Rx" "No";
BA_DEF_DEF_  "U_B515_MCA_MY17_Gas_Rx" "No";
BA_DEF_DEF_  "U_B515_MCA_MY17_Diesel_Rx" "No";
BA_DEF_DEF_  "U_B479_MY17_Diesel_Rx" "No";
BA_DEF_DEF_  "U_B479_MY17_Gas_Rx" "No";
BA_DEF_DEF_  "U_B562LC_MY15_Gas_Rx" "No";
BA_DEF_DEF_  "U_B562LC_MY15_Diesel_Rx" "No";
BA_DEF_DEF_  "GenSigStartValue" 0;
BA_DEF_DEF_  "MetaData" "No";
BA_DEF_DEF_  "ContentDependant" "No";
BA_DEF_DEF_  "GenSigStartValueInteger" 0;
BA_DEF_DEF_  "UsedOnPgmDBC" "Yes";
BA_DEF_DEF_  "CrossOver_InfoCAN" "No";
BA_DEF_DEF_  "WakeupSignal" "No";
BA_DEF_DEF_  "GenSigInactiveValue" 0;
BA_DEF_DEF_  "GenSigSendType" "NoSigSendType";
BA_DEF_DEF_  "AuthFreshnessCounterSyncAttempt" 2;
BA_DEF_DEF_  "GenMsgRoutingTimeoutTime" 0;
BA_DEF_DEF_  "MessageGateway" "No";
BA_DEF_DEF_  "NmAsrMessage" "No";
BA_DEF_DEF_  "DiagState" "No";
BA_DEF_DEF_  "DiagRequest" "No";
BA_DEF_DEF_  "DiagResponse" "No";
BA_DEF_DEF_  "NmMessage" "No";
BA_DEF_DEF_  "GenMsgILSupport" "Yes";
BA_ "GenMsgSendType" BO_ 947 5;
BA_ "GenMsgCycleTime" BO_ 947 1000;
BA_ "FrameGatewayNetwork" BO_ 947 "HS1_CAN";
BA_ "FrameGatewayId" BO_ 947 947;
BA_ "GenMsgCycleTime" BO_ 293 1000;
BA_ "GenMsgSendType" BO_ 293 5;
BA_ "GenMsgCycleTime" BO_ 292 1000;
BA_ "GenMsgSendType" BO_ 292 5;
BA_ "FrameGatewayNetwork" BO_ 1126 "HS3_CAN";
BA_ "FrameGatewayId" BO_ 1126 1123;
BA_ "FrameGatewayNetwork" BO_ 1125 "HS3_CAN";
BA_ "FrameGatewayId" BO_ 1125 1122;
BA_ "GenMsgSendType" BO_ 992 5;
BA_ "GenMsgCycleTime" BO_ 992 1000;
BA_ "FrameGatewayNetwork" BO_ 992 "HS3_CAN";
BA_ "FrameGatewayId" BO_ 992 992;
BA_ "FrameGatewayNetwork" BO_ 1127 "HS3_CAN";
BA_ "FrameGatewayId" BO_ 1127 1124;
BA_ "GenMsgCycleTime" BO_ 999 1000;
BA_ "GenMsgSendType" BO_ 999 5;
BA_ "NetworkInitialization" BO_ 1998 0;
BA_ "GenMsgDelayTime" BO_ 1998 0;
BA_ "GenMsgSendType" BO_ 1998 1;
BA_ "DiagResponse" BO_ 1998 1;
BA_ "GenMsgILSupport" BO_ 1998 0;
BA_ "NetworkInitialization" BO_ 1990 0;
BA_ "GenMsgDelayTime" BO_ 1990 0;
BA_ "GenMsgSendType" BO_ 1990 1;
BA_ "DiagRequest" BO_ 1990 1;
BA_ "GenMsgILSupport" BO_ 1990 0;
BA_ "NetworkInitialization" BO_ 1996 0;
BA_ "GenMsgDelayTime" BO_ 1996 0;
BA_ "GenMsgSendType" BO_ 1996 1;
BA_ "DiagResponse" BO_ 1996 1;
BA_ "GenMsgILSupport" BO_ 1996 0;
BA_ "NetworkInitialization" BO_ 1988 0;
BA_ "GenMsgDelayTime" BO_ 1988 0;
BA_ "GenMsgSendType" BO_ 1988 1;
BA_ "DiagRequest" BO_ 1988 1;
BA_ "GenMsgILSupport" BO_ 1988 0;
BA_ "NetworkInitialization" BO_ 2027 0;
BA_ "GenMsgDelayTime" BO_ 2027 0;
BA_ "GenMsgSendType" BO_ 2027 1;
BA_ "DiagResponse" BO_ 2027 1;
BA_ "GenMsgILSupport" BO_ 2027 0;
BA_ "NetworkInitialization" BO_ 1496 0;
BA_ "GenMsgCycleTime" BO_ 1496 1000;
BA_ "GenMsgSendType" BO_ 1496 0;
BA_ "NmAsrMessage" BO_ 1496 1;
BA_ "GenMsgILSupport" BO_ 1496 0;
BA_ "NetworkInitialization" BO_ 2019 0;
BA_ "GenMsgDelayTime" BO_ 2019 0;
BA_ "GenMsgSendType" BO_ 2019 1;
BA_ "DiagRequest" BO_ 2019 1;
BA_ "GenMsgILSupport" BO_ 2019 0;
BA_ "GenMsgCycleTime" BO_ 862 1000;
BA_ "GenMsgSendType" BO_ 862 5;
BA_ "GenMsgCycleTime" BO_ 828 1000;
BA_ "GenMsgSendType" BO_ 828 5;
BA_ "NetworkInitialization" BO_ 1909 0;
BA_ "GenMsgDelayTime" BO_ 1909 0;
BA_ "GenMsgSendType" BO_ 1909 1;
BA_ "DiagRequest" BO_ 1909 1;
BA_ "GenMsgILSupport" BO_ 1909 0;
BA_ "NetworkInitialization" BO_ 1917 0;
BA_ "GenMsgDelayTime" BO_ 1917 0;
BA_ "GenMsgSendType" BO_ 1917 1;
BA_ "DiagResponse" BO_ 1917 1;
BA_ "GenMsgILSupport" BO_ 1917 0;
BA_ "NetworkInitialization" BO_ 1860 0;
BA_ "GenMsgDelayTime" BO_ 1860 0;
BA_ "GenMsgSendType" BO_ 1860 1;
BA_ "DiagRequest" BO_ 1860 1;
BA_ "GenMsgILSupport" BO_ 1860 0;
BA_ "NetworkInitialization" BO_ 1868 0;
BA_ "GenMsgDelayTime" BO_ 1868 0;
BA_ "GenMsgSendType" BO_ 1868 1;
BA_ "DiagResponse" BO_ 1868 1;
BA_ "GenMsgILSupport" BO_ 1868 0;
BA_ "NetworkInitialization" BO_ 1918 0;
BA_ "GenMsgDelayTime" BO_ 1918 0;
BA_ "GenMsgSendType" BO_ 1918 1;
BA_ "DiagResponse" BO_ 1918 1;
BA_ "GenMsgILSupport" BO_ 1918 0;
BA_ "NetworkInitialization" BO_ 1910 0;
BA_ "GenMsgDelayTime" BO_ 1910 0;
BA_ "GenMsgSendType" BO_ 1910 1;
BA_ "DiagRequest" BO_ 1910 1;
BA_ "GenMsgILSupport" BO_ 1910 0;
BA_ "NetworkInitialization" BO_ 1814 0;
BA_ "GenMsgDelayTime" BO_ 1814 0;
BA_ "GenMsgSendType" BO_ 1814 1;
BA_ "DiagRequest" BO_ 1814 1;
BA_ "GenMsgILSupport" BO_ 1814 0;
BA_ "NetworkInitialization" BO_ 1822 0;
BA_ "GenMsgDelayTime" BO_ 1822 0;
BA_ "GenMsgSendType" BO_ 1822 1;
BA_ "DiagResponse" BO_ 1822 1;
BA_ "GenMsgILSupport" BO_ 1822 0;
BA_ "GenMsgStartDelayTime" BO_ 826 100;
BA_ "GenMsgCycleTime" BO_ 826 100;
BA_ "GenMsgSendType" BO_ 826 5;
BA_ "GenMsgSendType" BO_ 1289 1;
BA_ "NmMessage" BO_ 1289 1;
BA_ "GenMsgILSupport" BO_ 1289 0;
BA_ "GenMsgCycleTime" BO_ 853 1000;
BA_ "GenMsgSendType" BO_ 853 5;
BA_ "GenMsgSendType" BO_ 1034 5;
BA_ "GenMsgCycleTime" BO_ 1034 1000;
BA_ "FrameGatewayNetwork" BO_ 1034 "HS1_CAN";
BA_ "FrameGatewayId" BO_ 1034 1034;
BA_ "GenMsgCycleTime" BO_ 956 50;
BA_ "GenMsgSendType" BO_ 956 5;
BA_ "GenMsgStartDelayTime" BO_ 831 200;
BA_ "GenMsgCycleTime" BO_ 831 1000;
BA_ "GenMsgSendType" BO_ 831 5;
BA_ "GenMsgCycleTime" BO_ 787 1000;
BA_ "GenMsgSendType" BO_ 787 5;
BA_ "GenMsgSendType" BO_ 1291 1;
BA_ "NmMessage" BO_ 1291 1;
BA_ "GenMsgILSupport" BO_ 1291 0;
BA_ "CrossOver_InfoCAN" SG_ 947 TurnLghtRightOn_B_Stat 1;
BA_ "CrossOver_InfoCAN" SG_ 947 TurnLghtLeftOn_B_Stat 1;
BA_ "GenSigSendType" SG_ 947 Backlit_LED_Status 3;
BA_ "U_H567_MY20_Rx" SG_ 947 Backlit_LED_Status 1;
BA_ "U_B562_MY18_Diesel_Rx" SG_ 947 Backlit_LED_Status 1;
BA_ "U_B500_MY18_Diesel_Rx" SG_ 947 Backlit_LED_Status 1;
BA_ "U_B500_MY18_Gas_Rx" SG_ 947 Backlit_LED_Status 1;
BA_ "U_B562_MY18_Gas_Rx" SG_ 947 Backlit_LED_Status 1;
BA_ "U_CX727_MY2021_Rx" SG_ 947 Backlit_LED_Status 1;
BA_ "U_P702_MY2021_Rx" SG_ 947 Backlit_LED_Status 1;
BA_ "U_CX430_MY2021_Rx" SG_ 947 Backlit_LED_Status 1;
BA_ "U_U611_U625_MY20_Phev_Rx" SG_ 947 Backlit_LED_Status 1;
BA_ "U_CX482_CX483_MY20_Rx" SG_ 947 Backlit_LED_Status 1;
BA_ "U_U611_U625_MY20_Hev_Rx" SG_ 947 Backlit_LED_Status 1;
BA_ "U_U611_U625_MY20_Gas_Rx" SG_ 947 Backlit_LED_Status 1;
BA_ "U_C490_MY18_Rx" SG_ 947 Backlit_LED_Status 1;
BA_ "U_C519_MY18_5_Gas_Rx" SG_ 947 Backlit_LED_Status 1;
BA_ "U_C519_MY18_5_Diesel_Rx" SG_ 947 Backlit_LED_Status 1;
BA_ "U_B515_MCA_MY17_Gas_Rx" SG_ 947 Backlit_LED_Status 1;
BA_ "U_B515_MCA_MY17_Diesel_Rx" SG_ 947 Backlit_LED_Status 1;
BA_ "U_B479_MY17_Diesel_Rx" SG_ 947 Backlit_LED_Status 1;
BA_ "U_B479_MY17_Gas_Rx" SG_ 947 Backlit_LED_Status 1;
BA_ "CrossOver_InfoCAN" SG_ 947 Backlit_LED_Status 1;
BA_ "WakeupSignal" SG_ 947 Backlit_LED_Status 1;
BA_ "U_P702_MY2021_Rx" SG_ 947 FogLghtRearOn_B_Stat 1;
BA_ "U_CX430_MY2021_Rx" SG_ 947 FogLghtRearOn_B_Stat 1;
BA_ "U_CX482_CX483_MY20_Rx" SG_ 947 FogLghtRearOn_B_Stat 1;
BA_ "U_C519_MY18_5_Gas_Rx" SG_ 947 FogLghtRearOn_B_Stat 1;
BA_ "U_C519_MY18_5_Diesel_Rx" SG_ 947 FogLghtRearOn_B_Stat 1;
BA_ "U_B515_MCA_MY17_Gas_Rx" SG_ 947 FogLghtRearOn_B_Stat 1;
BA_ "U_B515_MCA_MY17_Diesel_Rx" SG_ 947 FogLghtRearOn_B_Stat 1;
BA_ "U_B479_MY17_Diesel_Rx" SG_ 947 FogLghtRearOn_B_Stat 1;
BA_ "U_B479_MY17_Gas_Rx" SG_ 947 FogLghtRearOn_B_Stat 1;
BA_ "CrossOver_InfoCAN" SG_ 947 FogLghtRearOn_B_Stat 1;
BA_ "U_CX727_MY2021_Rx" SG_ 947 ValetMode_D_Mem 1;
BA_ "U_U611_U625_MY20_Phev_Rx" SG_ 947 ValetMode_D_Mem 1;
BA_ "U_CX482_CX483_MY20_Rx" SG_ 947 ValetMode_D_Mem 1;
BA_ "U_U611_U625_MY20_Hev_Rx" SG_ 947 ValetMode_D_Mem 1;
BA_ "U_U611_U625_MY20_Gas_Rx" SG_ 947 ValetMode_D_Mem 1;
BA_ "U_C519_MY18_5_Gas_Rx" SG_ 947 ValetMode_D_Mem 1;
BA_ "U_C519_MY18_5_Diesel_Rx" SG_ 947 ValetMode_D_Mem 1;
BA_ "U_CX727_MY2021_Rx" SG_ 947 IgnKeyType_D_Actl 1;
BA_ "U_CX430_MY2021_Rx" SG_ 947 IgnKeyType_D_Actl 1;
BA_ "U_U611_U625_MY20_Phev_Rx" SG_ 947 IgnKeyType_D_Actl 1;
BA_ "U_CX482_CX483_MY20_Rx" SG_ 947 IgnKeyType_D_Actl 1;
BA_ "U_U611_U625_MY20_Hev_Rx" SG_ 947 IgnKeyType_D_Actl 1;
BA_ "U_U611_U625_MY20_Gas_Rx" SG_ 947 IgnKeyType_D_Actl 1;
BA_ "U_C519_MY18_5_Gas_Rx" SG_ 947 IgnKeyType_D_Actl 1;
BA_ "U_C519_MY18_5_Diesel_Rx" SG_ 947 IgnKeyType_D_Actl 1;
BA_ "U_B515_MCA_MY17_Gas_Rx" SG_ 947 IgnKeyType_D_Actl 1;
BA_ "U_B515_MCA_MY17_Diesel_Rx" SG_ 947 IgnKeyType_D_Actl 1;
BA_ "U_B479_MY17_Diesel_Rx" SG_ 947 IgnKeyType_D_Actl 1;
BA_ "U_B479_MY17_Gas_Rx" SG_ 947 IgnKeyType_D_Actl 1;
BA_ "U_B562LC_MY15_Gas_Rx" SG_ 947 IgnKeyType_D_Actl 1;
BA_ "GenSigStartValue" SG_ 947 IgnKeyType_D_Actl 14;
BA_ "GenSigStartValueInteger" SG_ 947 IgnKeyType_D_Actl 14;
BA_ "CrossOver_InfoCAN" SG_ 947 IgnKeyType_D_Actl 1;
BA_ "U_CX727_MY2021_Rx" SG_ 947 TurnLghtRight_D_Rq 1;
BA_ "U_U611_U625_MY20_Hev_Rx" SG_ 947 TurnLghtRight_D_Rq 1;
BA_ "U_C490_MY18_Rx" SG_ 947 TurnLghtRight_D_Rq 1;
BA_ "U_P702_MY2021_Rx" SG_ 947 TurnLghtRight_D_Rq 1;
BA_ "U_CX430_MY2021_Rx" SG_ 947 TurnLghtRight_D_Rq 1;
BA_ "U_U611_U625_MY20_Phev_Rx" SG_ 947 TurnLghtRight_D_Rq 1;
BA_ "U_CX482_CX483_MY20_Rx" SG_ 947 TurnLghtRight_D_Rq 1;
BA_ "U_U611_U625_MY20_Gas_Rx" SG_ 947 TurnLghtRight_D_Rq 1;
BA_ "U_C519_MY18_5_Gas_Rx" SG_ 947 TurnLghtRight_D_Rq 1;
BA_ "U_C519_MY18_5_Diesel_Rx" SG_ 947 TurnLghtRight_D_Rq 1;
BA_ "U_B515_MCA_MY17_Gas_Rx" SG_ 947 TurnLghtRight_D_Rq 1;
BA_ "U_B515_MCA_MY17_Diesel_Rx" SG_ 947 TurnLghtRight_D_Rq 1;
BA_ "U_B479_MY17_Diesel_Rx" SG_ 947 TurnLghtRight_D_Rq 1;
BA_ "U_B479_MY17_Gas_Rx" SG_ 947 TurnLghtRight_D_Rq 1;
BA_ "CrossOver_InfoCAN" SG_ 947 TurnLghtRight_D_Rq 1;
BA_ "WakeupSignal" SG_ 947 TurnLghtRight_D_Rq 1;
BA_ "U_H567_MY20_Rx" SG_ 947 Parklamp_Status 1;
BA_ "U_B562_MY18_Diesel_Rx" SG_ 947 Parklamp_Status 1;
BA_ "U_B500_MY18_Diesel_Rx" SG_ 947 Parklamp_Status 1;
BA_ "U_B500_MY18_Gas_Rx" SG_ 947 Parklamp_Status 1;
BA_ "U_B562_MY18_Gas_Rx" SG_ 947 Parklamp_Status 1;
BA_ "U_P702_MY2021_Rx" SG_ 947 Parklamp_Status 1;
BA_ "U_C490_MY18_Rx" SG_ 947 Parklamp_Status 1;
BA_ "U_CX727_MY2021_Rx" SG_ 947 Parklamp_Status 1;
BA_ "U_CX430_MY2021_Rx" SG_ 947 Parklamp_Status 1;
BA_ "U_U611_U625_MY20_Phev_Rx" SG_ 947 Parklamp_Status 1;
BA_ "U_CX482_CX483_MY20_Rx" SG_ 947 Parklamp_Status 1;
BA_ "U_U611_U625_MY20_Hev_Rx" SG_ 947 Parklamp_Status 1;
BA_ "U_U611_U625_MY20_Gas_Rx" SG_ 947 Parklamp_Status 1;
BA_ "U_C519_MY18_5_Gas_Rx" SG_ 947 Parklamp_Status 1;
BA_ "U_C519_MY18_5_Diesel_Rx" SG_ 947 Parklamp_Status 1;
BA_ "U_B515_MCA_MY17_Gas_Rx" SG_ 947 Parklamp_Status 1;
BA_ "U_B515_MCA_MY17_Diesel_Rx" SG_ 947 Parklamp_Status 1;
BA_ "U_B479_MY17_Diesel_Rx" SG_ 947 Parklamp_Status 1;
BA_ "U_B479_MY17_Gas_Rx" SG_ 947 Parklamp_Status 1;
BA_ "U_B562LC_MY15_Gas_Rx" SG_ 947 Parklamp_Status 1;
BA_ "GenSigSendType" SG_ 947 Parklamp_Status 3;
BA_ "GenSigStartValue" SG_ 947 Parklamp_Status 1;
BA_ "GenSigStartValueInteger" SG_ 947 Parklamp_Status 1;
BA_ "CrossOver_InfoCAN" SG_ 947 Parklamp_Status 1;
BA_ "WakeupSignal" SG_ 947 Parklamp_Status 1;
BA_ "U_H567_MY20_Rx" SG_ 947 Litval 1;
BA_ "U_B562_MY18_Diesel_Rx" SG_ 947 Litval 1;
BA_ "U_B500_MY18_Diesel_Rx" SG_ 947 Litval 1;
BA_ "U_B500_MY18_Gas_Rx" SG_ 947 Litval 1;
BA_ "U_B562_MY18_Gas_Rx" SG_ 947 Litval 1;
BA_ "U_P702_MY2021_Rx" SG_ 947 Litval 1;
BA_ "U_C490_MY18_Rx" SG_ 947 Litval 1;
BA_ "U_CX727_MY2021_Rx" SG_ 947 Litval 1;
BA_ "U_CX430_MY2021_Rx" SG_ 947 Litval 1;
BA_ "U_U611_U625_MY20_Phev_Rx" SG_ 947 Litval 1;
BA_ "U_CX482_CX483_MY20_Rx" SG_ 947 Litval 1;
BA_ "U_U611_U625_MY20_Hev_Rx" SG_ 947 Litval 1;
BA_ "U_U611_U625_MY20_Gas_Rx" SG_ 947 Litval 1;
BA_ "U_C519_MY18_5_Gas_Rx" SG_ 947 Litval 1;
BA_ "U_C519_MY18_5_Diesel_Rx" SG_ 947 Litval 1;
BA_ "U_B515_MCA_MY17_Gas_Rx" SG_ 947 Litval 1;
BA_ "U_B515_MCA_MY17_Diesel_Rx" SG_ 947 Litval 1;
BA_ "U_B479_MY17_Diesel_Rx" SG_ 947 Litval 1;
BA_ "U_B479_MY17_Gas_Rx" SG_ 947 Litval 1;
BA_ "U_B562LC_MY15_Gas_Rx" SG_ 947 Litval 1;
BA_ "GenSigSendType" SG_ 947 Litval 3;
BA_ "CrossOver_InfoCAN" SG_ 947 Litval 1;
BA_ "WakeupSignal" SG_ 947 Litval 1;
BA_ "U_C490_MY18_Rx" SG_ 947 Key_In_Ignition_Stat 1;
BA_ "U_P702_MY2021_Rx" SG_ 947 Key_In_Ignition_Stat 1;
BA_ "U_CX727_MY2021_Rx" SG_ 947 Key_In_Ignition_Stat 1;
BA_ "U_VN127_MY20_Rx" SG_ 947 Key_In_Ignition_Stat 1;
BA_ "U_H567_MY20_Rx" SG_ 947 Key_In_Ignition_Stat 1;
BA_ "U_CX430_MY2021_Rx" SG_ 947 Key_In_Ignition_Stat 1;
BA_ "U_U611_U625_MY20_Phev_Rx" SG_ 947 Key_In_Ignition_Stat 1;
BA_ "U_CX482_CX483_MY20_Rx" SG_ 947 Key_In_Ignition_Stat 1;
BA_ "U_U611_U625_MY20_Hev_Rx" SG_ 947 Key_In_Ignition_Stat 1;
BA_ "U_U611_U625_MY20_Gas_Rx" SG_ 947 Key_In_Ignition_Stat 1;
BA_ "U_C519_MY18_5_Gas_Rx" SG_ 947 Key_In_Ignition_Stat 1;
BA_ "U_C519_MY18_5_Diesel_Rx" SG_ 947 Key_In_Ignition_Stat 1;
BA_ "U_B515_MCA_MY17_Gas_Rx" SG_ 947 Key_In_Ignition_Stat 1;
BA_ "U_B515_MCA_MY17_Diesel_Rx" SG_ 947 Key_In_Ignition_Stat 1;
BA_ "U_B479_MY17_Diesel_Rx" SG_ 947 Key_In_Ignition_Stat 1;
BA_ "U_B479_MY17_Gas_Rx" SG_ 947 Key_In_Ignition_Stat 1;
BA_ "CrossOver_InfoCAN" SG_ 947 Key_In_Ignition_Stat 1;
BA_ "WakeupSignal" SG_ 947 Key_In_Ignition_Stat 1;
BA_ "U_B562_MY18_Diesel_Rx" SG_ 947 Ignition_Status 1;
BA_ "U_B500_MY18_Diesel_Rx" SG_ 947 Ignition_Status 1;
BA_ "U_B500_MY18_Gas_Rx" SG_ 947 Ignition_Status 1;
BA_ "U_B562_MY18_Gas_Rx" SG_ 947 Ignition_Status 1;
BA_ "U_C490_MY18_Rx" SG_ 947 Ignition_Status 1;
BA_ "U_B562LC_MY15_Diesel_Rx" SG_ 947 Ignition_Status 1;
BA_ "U_VN127_MY20_Rx" SG_ 947 Ignition_Status 1;
BA_ "U_H567_MY20_Rx" SG_ 947 Ignition_Status 1;
BA_ "U_P702_MY2021_Rx" SG_ 947 Ignition_Status 1;
BA_ "U_CX727_MY2021_Rx" SG_ 947 Ignition_Status 1;
BA_ "U_CX430_MY2021_Rx" SG_ 947 Ignition_Status 1;
BA_ "U_U611_U625_MY20_Phev_Rx" SG_ 947 Ignition_Status 1;
BA_ "U_CX482_CX483_MY20_Rx" SG_ 947 Ignition_Status 1;
BA_ "U_U611_U625_MY20_Hev_Rx" SG_ 947 Ignition_Status 1;
BA_ "U_U611_U625_MY20_Gas_Rx" SG_ 947 Ignition_Status 1;
BA_ "U_C519_MY18_5_Gas_Rx" SG_ 947 Ignition_Status 1;
BA_ "U_C519_MY18_5_Diesel_Rx" SG_ 947 Ignition_Status 1;
BA_ "U_B515_MCA_MY17_Gas_Rx" SG_ 947 Ignition_Status 1;
BA_ "U_B515_MCA_MY17_Diesel_Rx" SG_ 947 Ignition_Status 1;
BA_ "U_B479_MY17_Diesel_Rx" SG_ 947 Ignition_Status 1;
BA_ "U_B479_MY17_Gas_Rx" SG_ 947 Ignition_Status 1;
BA_ "U_B562LC_MY15_Gas_Rx" SG_ 947 Ignition_Status 1;
BA_ "GenSigSendType" SG_ 947 Ignition_Status 3;
BA_ "CrossOver_InfoCAN" SG_ 947 Ignition_Status 1;
BA_ "WakeupSignal" SG_ 947 Ignition_Status 1;
BA_ "U_H567_MY20_Rx" SG_ 947 Dimming_Lvl 1;
BA_ "U_B562_MY18_Diesel_Rx" SG_ 947 Dimming_Lvl 1;
BA_ "U_B500_MY18_Diesel_Rx" SG_ 947 Dimming_Lvl 1;
BA_ "U_B500_MY18_Gas_Rx" SG_ 947 Dimming_Lvl 1;
BA_ "U_B562_MY18_Gas_Rx" SG_ 947 Dimming_Lvl 1;
BA_ "U_CX727_MY2021_Rx" SG_ 947 Dimming_Lvl 1;
BA_ "U_P702_MY2021_Rx" SG_ 947 Dimming_Lvl 1;
BA_ "U_CX430_MY2021_Rx" SG_ 947 Dimming_Lvl 1;
BA_ "U_U611_U625_MY20_Phev_Rx" SG_ 947 Dimming_Lvl 1;
BA_ "U_CX482_CX483_MY20_Rx" SG_ 947 Dimming_Lvl 1;
BA_ "U_U611_U625_MY20_Hev_Rx" SG_ 947 Dimming_Lvl 1;
BA_ "U_U611_U625_MY20_Gas_Rx" SG_ 947 Dimming_Lvl 1;
BA_ "U_C490_MY18_Rx" SG_ 947 Dimming_Lvl 1;
BA_ "U_C519_MY18_5_Gas_Rx" SG_ 947 Dimming_Lvl 1;
BA_ "U_C519_MY18_5_Diesel_Rx" SG_ 947 Dimming_Lvl 1;
BA_ "U_B515_MCA_MY17_Gas_Rx" SG_ 947 Dimming_Lvl 1;
BA_ "U_B515_MCA_MY17_Diesel_Rx" SG_ 947 Dimming_Lvl 1;
BA_ "U_B479_MY17_Diesel_Rx" SG_ 947 Dimming_Lvl 1;
BA_ "U_B479_MY17_Gas_Rx" SG_ 947 Dimming_Lvl 1;
BA_ "GenSigSendType" SG_ 947 Dimming_Lvl 3;
BA_ "GenSigStartValue" SG_ 947 Dimming_Lvl 12;
BA_ "GenSigStartValueInteger" SG_ 947 Dimming_Lvl 12;
BA_ "CrossOver_InfoCAN" SG_ 947 Dimming_Lvl 1;
BA_ "WakeupSignal" SG_ 947 Dimming_Lvl 1;
BA_ "U_H567_MY20_Rx" SG_ 947 Day_Night_Status 1;
BA_ "U_B562_MY18_Diesel_Rx" SG_ 947 Day_Night_Status 1;
BA_ "U_B500_MY18_Diesel_Rx" SG_ 947 Day_Night_Status 1;
BA_ "U_B500_MY18_Gas_Rx" SG_ 947 Day_Night_Status 1;
BA_ "U_B562_MY18_Gas_Rx" SG_ 947 Day_Night_Status 1;
BA_ "U_CX727_MY2021_Rx" SG_ 947 Day_Night_Status 1;
BA_ "U_P702_MY2021_Rx" SG_ 947 Day_Night_Status 1;
BA_ "U_CX430_MY2021_Rx" SG_ 947 Day_Night_Status 1;
BA_ "U_U611_U625_MY20_Phev_Rx" SG_ 947 Day_Night_Status 1;
BA_ "U_CX482_CX483_MY20_Rx" SG_ 947 Day_Night_Status 1;
BA_ "U_U611_U625_MY20_Hev_Rx" SG_ 947 Day_Night_Status 1;
BA_ "U_U611_U625_MY20_Gas_Rx" SG_ 947 Day_Night_Status 1;
BA_ "U_C490_MY18_Rx" SG_ 947 Day_Night_Status 1;
BA_ "U_C519_MY18_5_Gas_Rx" SG_ 947 Day_Night_Status 1;
BA_ "U_C519_MY18_5_Diesel_Rx" SG_ 947 Day_Night_Status 1;
BA_ "U_B515_MCA_MY17_Gas_Rx" SG_ 947 Day_Night_Status 1;
BA_ "U_B515_MCA_MY17_Diesel_Rx" SG_ 947 Day_Night_Status 1;
BA_ "U_B479_MY17_Diesel_Rx" SG_ 947 Day_Night_Status 1;
BA_ "U_B479_MY17_Gas_Rx" SG_ 947 Day_Night_Status 1;
BA_ "GenSigSendType" SG_ 947 Day_Night_Status 3;
BA_ "CrossOver_InfoCAN" SG_ 947 Day_Night_Status 1;
BA_ "WakeupSignal" SG_ 947 Day_Night_Status 1;
BA_ "U_P702_MY2021_Rx" SG_ 947 Remote_Start_Status 1;
BA_ "U_H567_MY20_Rx" SG_ 947 Remote_Start_Status 1;
BA_ "U_U611_U625_MY20_Phev_Rx" SG_ 947 Remote_Start_Status 1;
BA_ "U_U611_U625_MY20_Hev_Rx" SG_ 947 Remote_Start_Status 1;
BA_ "U_U611_U625_MY20_Gas_Rx" SG_ 947 Remote_Start_Status 1;
BA_ "U_B500_MY18_Diesel_Rx" SG_ 947 Remote_Start_Status 1;
BA_ "U_B500_MY18_Gas_Rx" SG_ 947 Remote_Start_Status 1;
BA_ "U_B479_MY17_Diesel_Rx" SG_ 947 Remote_Start_Status 1;
BA_ "U_B479_MY17_Gas_Rx" SG_ 947 Remote_Start_Status 1;
BA_ "U_CX727_MY2021_Rx" SG_ 947 Remote_Start_Status 1;
BA_ "U_CX430_MY2021_Rx" SG_ 947 Remote_Start_Status 1;
BA_ "U_CX482_CX483_MY20_Rx" SG_ 947 Remote_Start_Status 1;
BA_ "U_C519_MY18_5_Gas_Rx" SG_ 947 Remote_Start_Status 1;
BA_ "U_C519_MY18_5_Diesel_Rx" SG_ 947 Remote_Start_Status 1;
BA_ "U_B515_MCA_MY17_Gas_Rx" SG_ 947 Remote_Start_Status 1;
BA_ "U_B515_MCA_MY17_Diesel_Rx" SG_ 947 Remote_Start_Status 1;
BA_ "GenSigSendType" SG_ 947 Remote_Start_Status 3;
BA_ "CrossOver_InfoCAN" SG_ 947 Remote_Start_Status 1;
BA_ "WakeupSignal" SG_ 947 Remote_Start_Status 1;
BA_ "U_U611_U625_MY20_Phev_Rx" SG_ 947 DrStatTgate_B_Actl 1;
BA_ "U_U611_U625_MY20_Hev_Rx" SG_ 947 DrStatTgate_B_Actl 1;
BA_ "U_U611_U625_MY20_Gas_Rx" SG_ 947 DrStatTgate_B_Actl 1;
BA_ "U_CX727_MY2021_Rx" SG_ 947 DrStatTgate_B_Actl 1;
BA_ "U_CX430_MY2021_Rx" SG_ 947 DrStatTgate_B_Actl 1;
BA_ "U_CX482_CX483_MY20_Rx" SG_ 947 DrStatTgate_B_Actl 1;
BA_ "U_C519_MY18_5_Gas_Rx" SG_ 947 DrStatTgate_B_Actl 1;
BA_ "U_C519_MY18_5_Diesel_Rx" SG_ 947 DrStatTgate_B_Actl 1;
BA_ "U_B515_MCA_MY17_Gas_Rx" SG_ 947 DrStatTgate_B_Actl 1;
BA_ "U_B515_MCA_MY17_Diesel_Rx" SG_ 947 DrStatTgate_B_Actl 1;
BA_ "GenSigSendType" SG_ 947 DrStatTgate_B_Actl 3;
BA_ "CrossOver_InfoCAN" SG_ 947 DrStatTgate_B_Actl 1;
BA_ "WakeupSignal" SG_ 947 DrStatTgate_B_Actl 1;
BA_ "U_C490_MY18_Rx" SG_ 947 DrStatRr_B_Actl 1;
BA_ "U_P702_MY2021_Rx" SG_ 947 DrStatRr_B_Actl 1;
BA_ "U_U611_U625_MY20_Phev_Rx" SG_ 947 DrStatRr_B_Actl 1;
BA_ "U_U611_U625_MY20_Hev_Rx" SG_ 947 DrStatRr_B_Actl 1;
BA_ "U_U611_U625_MY20_Gas_Rx" SG_ 947 DrStatRr_B_Actl 1;
BA_ "U_B479_MY17_Diesel_Rx" SG_ 947 DrStatRr_B_Actl 1;
BA_ "U_B479_MY17_Gas_Rx" SG_ 947 DrStatRr_B_Actl 1;
BA_ "U_CX727_MY2021_Rx" SG_ 947 DrStatRr_B_Actl 1;
BA_ "U_CX430_MY2021_Rx" SG_ 947 DrStatRr_B_Actl 1;
BA_ "U_CX482_CX483_MY20_Rx" SG_ 947 DrStatRr_B_Actl 1;
BA_ "U_C519_MY18_5_Gas_Rx" SG_ 947 DrStatRr_B_Actl 1;
BA_ "U_C519_MY18_5_Diesel_Rx" SG_ 947 DrStatRr_B_Actl 1;
BA_ "U_B515_MCA_MY17_Gas_Rx" SG_ 947 DrStatRr_B_Actl 1;
BA_ "U_B515_MCA_MY17_Diesel_Rx" SG_ 947 DrStatRr_B_Actl 1;
BA_ "GenSigSendType" SG_ 947 DrStatRr_B_Actl 3;
BA_ "CrossOver_InfoCAN" SG_ 947 DrStatRr_B_Actl 1;
BA_ "WakeupSignal" SG_ 947 DrStatRr_B_Actl 1;
BA_ "U_C490_MY18_Rx" SG_ 947 DrStatRl_B_Actl 1;
BA_ "U_P702_MY2021_Rx" SG_ 947 DrStatRl_B_Actl 1;
BA_ "U_U611_U625_MY20_Phev_Rx" SG_ 947 DrStatRl_B_Actl 1;
BA_ "U_U611_U625_MY20_Hev_Rx" SG_ 947 DrStatRl_B_Actl 1;
BA_ "U_U611_U625_MY20_Gas_Rx" SG_ 947 DrStatRl_B_Actl 1;
BA_ "U_B479_MY17_Diesel_Rx" SG_ 947 DrStatRl_B_Actl 1;
BA_ "U_B479_MY17_Gas_Rx" SG_ 947 DrStatRl_B_Actl 1;
BA_ "U_CX727_MY2021_Rx" SG_ 947 DrStatRl_B_Actl 1;
BA_ "U_CX430_MY2021_Rx" SG_ 947 DrStatRl_B_Actl 1;
BA_ "U_CX482_CX483_MY20_Rx" SG_ 947 DrStatRl_B_Actl 1;
BA_ "U_C519_MY18_5_Gas_Rx" SG_ 947 DrStatRl_B_Actl 1;
BA_ "U_C519_MY18_5_Diesel_Rx" SG_ 947 DrStatRl_B_Actl 1;
BA_ "U_B515_MCA_MY17_Gas_Rx" SG_ 947 DrStatRl_B_Actl 1;
BA_ "U_B515_MCA_MY17_Diesel_Rx" SG_ 947 DrStatRl_B_Actl 1;
BA_ "GenSigSendType" SG_ 947 DrStatRl_B_Actl 3;
BA_ "CrossOver_InfoCAN" SG_ 947 DrStatRl_B_Actl 1;
BA_ "WakeupSignal" SG_ 947 DrStatRl_B_Actl 1;
BA_ "U_P702_MY2021_Rx" SG_ 947 DrStatPsngr_B_Actl 1;
BA_ "U_CX727_MY2021_Rx" SG_ 947 DrStatPsngr_B_Actl 1;
BA_ "U_CX430_MY2021_Rx" SG_ 947 DrStatPsngr_B_Actl 1;
BA_ "U_U611_U625_MY20_Phev_Rx" SG_ 947 DrStatPsngr_B_Actl 1;
BA_ "U_CX482_CX483_MY20_Rx" SG_ 947 DrStatPsngr_B_Actl 1;
BA_ "U_U611_U625_MY20_Hev_Rx" SG_ 947 DrStatPsngr_B_Actl 1;
BA_ "U_U611_U625_MY20_Gas_Rx" SG_ 947 DrStatPsngr_B_Actl 1;
BA_ "U_B500_MY18_Diesel_Rx" SG_ 947 DrStatPsngr_B_Actl 1;
BA_ "U_B500_MY18_Gas_Rx" SG_ 947 DrStatPsngr_B_Actl 1;
BA_ "U_C490_MY18_Rx" SG_ 947 DrStatPsngr_B_Actl 1;
BA_ "U_C519_MY18_5_Gas_Rx" SG_ 947 DrStatPsngr_B_Actl 1;
BA_ "U_C519_MY18_5_Diesel_Rx" SG_ 947 DrStatPsngr_B_Actl 1;
BA_ "U_B515_MCA_MY17_Gas_Rx" SG_ 947 DrStatPsngr_B_Actl 1;
BA_ "U_B515_MCA_MY17_Diesel_Rx" SG_ 947 DrStatPsngr_B_Actl 1;
BA_ "U_B479_MY17_Diesel_Rx" SG_ 947 DrStatPsngr_B_Actl 1;
BA_ "U_B479_MY17_Gas_Rx" SG_ 947 DrStatPsngr_B_Actl 1;
BA_ "GenSigSendType" SG_ 947 DrStatPsngr_B_Actl 3;
BA_ "CrossOver_InfoCAN" SG_ 947 DrStatPsngr_B_Actl 1;
BA_ "WakeupSignal" SG_ 947 DrStatPsngr_B_Actl 1;
BA_ "U_U611_U625_MY20_Phev_Rx" SG_ 947 DrStatInnrTgate_B_Actl 1;
BA_ "U_U611_U625_MY20_Hev_Rx" SG_ 947 DrStatInnrTgate_B_Actl 1;
BA_ "U_U611_U625_MY20_Gas_Rx" SG_ 947 DrStatInnrTgate_B_Actl 1;
BA_ "U_CX727_MY2021_Rx" SG_ 947 DrStatInnrTgate_B_Actl 1;
BA_ "U_CX430_MY2021_Rx" SG_ 947 DrStatInnrTgate_B_Actl 1;
BA_ "U_CX482_CX483_MY20_Rx" SG_ 947 DrStatInnrTgate_B_Actl 1;
BA_ "U_C519_MY18_5_Gas_Rx" SG_ 947 DrStatInnrTgate_B_Actl 1;
BA_ "U_C519_MY18_5_Diesel_Rx" SG_ 947 DrStatInnrTgate_B_Actl 1;
BA_ "U_B515_MCA_MY17_Gas_Rx" SG_ 947 DrStatInnrTgate_B_Actl 1;
BA_ "U_B515_MCA_MY17_Diesel_Rx" SG_ 947 DrStatInnrTgate_B_Actl 1;
BA_ "GenSigSendType" SG_ 947 DrStatInnrTgate_B_Actl 3;
BA_ "CrossOver_InfoCAN" SG_ 947 DrStatInnrTgate_B_Actl 1;
BA_ "WakeupSignal" SG_ 947 DrStatInnrTgate_B_Actl 1;
BA_ "U_CX727_MY2021_Rx" SG_ 947 DrStatHood_B_Actl 1;
BA_ "U_CX430_MY2021_Rx" SG_ 947 DrStatHood_B_Actl 1;
BA_ "U_CX482_CX483_MY20_Rx" SG_ 947 DrStatHood_B_Actl 1;
BA_ "U_C519_MY18_5_Gas_Rx" SG_ 947 DrStatHood_B_Actl 1;
BA_ "U_C519_MY18_5_Diesel_Rx" SG_ 947 DrStatHood_B_Actl 1;
BA_ "U_B515_MCA_MY17_Gas_Rx" SG_ 947 DrStatHood_B_Actl 1;
BA_ "U_B515_MCA_MY17_Diesel_Rx" SG_ 947 DrStatHood_B_Actl 1;
BA_ "CrossOver_InfoCAN" SG_ 947 DrStatHood_B_Actl 1;
BA_ "WakeupSignal" SG_ 947 DrStatHood_B_Actl 1;
BA_ "U_B479_MY17_Diesel_Rx" SG_ 947 DrStatDrv_B_Actl 1;
BA_ "U_B479_MY17_Gas_Rx" SG_ 947 DrStatDrv_B_Actl 1;
BA_ "U_C519_MY18_5_Gas_Rx" SG_ 947 DrStatDrv_B_Actl 1;
BA_ "U_C519_MY18_5_Diesel_Rx" SG_ 947 DrStatDrv_B_Actl 1;
BA_ "U_B515_MCA_MY17_Gas_Rx" SG_ 947 DrStatDrv_B_Actl 1;
BA_ "U_B515_MCA_MY17_Diesel_Rx" SG_ 947 DrStatDrv_B_Actl 1;
BA_ "U_P702_MY2021_Rx" SG_ 947 DrStatDrv_B_Actl 1;
BA_ "U_CX727_MY2021_Rx" SG_ 947 DrStatDrv_B_Actl 1;
BA_ "U_CX430_MY2021_Rx" SG_ 947 DrStatDrv_B_Actl 1;
BA_ "U_U611_U625_MY20_Phev_Rx" SG_ 947 DrStatDrv_B_Actl 1;
BA_ "U_CX482_CX483_MY20_Rx" SG_ 947 DrStatDrv_B_Actl 1;
BA_ "U_U611_U625_MY20_Hev_Rx" SG_ 947 DrStatDrv_B_Actl 1;
BA_ "U_U611_U625_MY20_Gas_Rx" SG_ 947 DrStatDrv_B_Actl 1;
BA_ "U_C490_MY18_Rx" SG_ 947 DrStatDrv_B_Actl 1;
BA_ "GenSigSendType" SG_ 947 DrStatDrv_B_Actl 3;
BA_ "CrossOver_InfoCAN" SG_ 947 DrStatDrv_B_Actl 1;
BA_ "WakeupSignal" SG_ 947 DrStatDrv_B_Actl 1;
BA_ "U_CX727_MY2021_Rx" SG_ 947 PrkBrkActv_B_Actl 1;
BA_ "U_CX430_MY2021_Rx" SG_ 947 PrkBrkActv_B_Actl 1;
BA_ "U_U611_U625_MY20_Phev_Rx" SG_ 947 PrkBrkActv_B_Actl 1;
BA_ "U_CX482_CX483_MY20_Rx" SG_ 947 PrkBrkActv_B_Actl 1;
BA_ "U_U611_U625_MY20_Hev_Rx" SG_ 947 PrkBrkActv_B_Actl 1;
BA_ "U_U611_U625_MY20_Gas_Rx" SG_ 947 PrkBrkActv_B_Actl 1;
BA_ "ContentDependant" SG_ 947 PrkBrkActv_B_Actl 1;
BA_ "CrossOver_InfoCAN" SG_ 947 PrkBrkActv_B_Actl 1;
BA_ "WakeupSignal" SG_ 947 PrkBrkActv_B_Actl 1;
BA_ "U_B562_MY18_Diesel_Rx" SG_ 947 LifeCycMde_D_Actl 1;
BA_ "U_B500_MY18_Diesel_Rx" SG_ 947 LifeCycMde_D_Actl 1;
BA_ "U_B500_MY18_Gas_Rx" SG_ 947 LifeCycMde_D_Actl 1;
BA_ "U_B562_MY18_Gas_Rx" SG_ 947 LifeCycMde_D_Actl 1;
BA_ "U_VN127_MY20_Rx" SG_ 947 LifeCycMde_D_Actl 1;
BA_ "U_H567_MY20_Rx" SG_ 947 LifeCycMde_D_Actl 1;
BA_ "U_CX727_MY2021_Rx" SG_ 947 LifeCycMde_D_Actl 1;
BA_ "U_P702_MY2021_Rx" SG_ 947 LifeCycMde_D_Actl 1;
BA_ "U_CX430_MY2021_Rx" SG_ 947 LifeCycMde_D_Actl 1;
BA_ "U_U611_U625_MY20_Phev_Rx" SG_ 947 LifeCycMde_D_Actl 1;
BA_ "U_U611_U625_MY20_Hev_Rx" SG_ 947 LifeCycMde_D_Actl 1;
BA_ "U_U611_U625_MY20_Gas_Rx" SG_ 947 LifeCycMde_D_Actl 1;
BA_ "U_C490_MY18_Rx" SG_ 947 LifeCycMde_D_Actl 1;
BA_ "U_B515_MCA_MY17_Gas_Rx" SG_ 947 LifeCycMde_D_Actl 1;
BA_ "U_B515_MCA_MY17_Diesel_Rx" SG_ 947 LifeCycMde_D_Actl 1;
BA_ "U_B479_MY17_Diesel_Rx" SG_ 947 LifeCycMde_D_Actl 1;
BA_ "U_B479_MY17_Gas_Rx" SG_ 947 LifeCycMde_D_Actl 1;
BA_ "U_CX482_CX483_MY20_Rx" SG_ 947 LifeCycMde_D_Actl 1;
BA_ "U_C519_MY18_5_Gas_Rx" SG_ 947 LifeCycMde_D_Actl 1;
BA_ "U_C519_MY18_5_Diesel_Rx" SG_ 947 LifeCycMde_D_Actl 1;
BA_ "GenSigSendType" SG_ 947 LifeCycMde_D_Actl 3;
BA_ "CrossOver_InfoCAN" SG_ 947 LifeCycMde_D_Actl 1;
BA_ "U_CX727_MY2021_Rx" SG_ 947 Delay_Accy 1;
BA_ "U_P702_MY2021_Rx" SG_ 947 Delay_Accy 1;
BA_ "U_CX430_MY2021_Rx" SG_ 947 Delay_Accy 1;
BA_ "U_U611_U625_MY20_Phev_Rx" SG_ 947 Delay_Accy 1;
BA_ "U_CX482_CX483_MY20_Rx" SG_ 947 Delay_Accy 1;
BA_ "U_U611_U625_MY20_Hev_Rx" SG_ 947 Delay_Accy 1;
BA_ "U_U611_U625_MY20_Gas_Rx" SG_ 947 Delay_Accy 1;
BA_ "U_C490_MY18_Rx" SG_ 947 Delay_Accy 1;
BA_ "U_C519_MY18_5_Gas_Rx" SG_ 947 Delay_Accy 1;
BA_ "U_C519_MY18_5_Diesel_Rx" SG_ 947 Delay_Accy 1;
BA_ "U_B515_MCA_MY17_Gas_Rx" SG_ 947 Delay_Accy 1;
BA_ "U_B515_MCA_MY17_Diesel_Rx" SG_ 947 Delay_Accy 1;
BA_ "U_B479_MY17_Diesel_Rx" SG_ 947 Delay_Accy 1;
BA_ "U_B479_MY17_Gas_Rx" SG_ 947 Delay_Accy 1;
BA_ "CrossOver_InfoCAN" SG_ 947 Delay_Accy 1;
BA_ "WakeupSignal" SG_ 947 Delay_Accy 1;
BA_ "CrossOver_InfoCAN" SG_ 947 FogLghtFrontOn_B_Stat 1;
BA_ "U_CX727_MY2021_Rx" SG_ 947 TurnLghtLeft_D_Rq 1;
BA_ "U_U611_U625_MY20_Hev_Rx" SG_ 947 TurnLghtLeft_D_Rq 1;
BA_ "U_C490_MY18_Rx" SG_ 947 TurnLghtLeft_D_Rq 1;
BA_ "U_P702_MY2021_Rx" SG_ 947 TurnLghtLeft_D_Rq 1;
BA_ "U_CX430_MY2021_Rx" SG_ 947 TurnLghtLeft_D_Rq 1;
BA_ "U_U611_U625_MY20_Phev_Rx" SG_ 947 TurnLghtLeft_D_Rq 1;
BA_ "U_CX482_CX483_MY20_Rx" SG_ 947 TurnLghtLeft_D_Rq 1;
BA_ "U_U611_U625_MY20_Gas_Rx" SG_ 947 TurnLghtLeft_D_Rq 1;
BA_ "U_C519_MY18_5_Gas_Rx" SG_ 947 TurnLghtLeft_D_Rq 1;
BA_ "U_C519_MY18_5_Diesel_Rx" SG_ 947 TurnLghtLeft_D_Rq 1;
BA_ "U_B515_MCA_MY17_Gas_Rx" SG_ 947 TurnLghtLeft_D_Rq 1;
BA_ "U_B515_MCA_MY17_Diesel_Rx" SG_ 947 TurnLghtLeft_D_Rq 1;
BA_ "U_B479_MY17_Diesel_Rx" SG_ 947 TurnLghtLeft_D_Rq 1;
BA_ "U_B479_MY17_Gas_Rx" SG_ 947 TurnLghtLeft_D_Rq 1;
BA_ "CrossOver_InfoCAN" SG_ 947 TurnLghtLeft_D_Rq 1;
BA_ "WakeupSignal" SG_ 947 TurnLghtLeft_D_Rq 1;
BA_ "GenSigSendType" SG_ 947 CrashEvnt_D_Stat 3;
BA_ "U_P702_MY2021_Rx" SG_ 947 CrashEvnt_D_Stat 1;
BA_ "U_CX727_MY2021_Rx" SG_ 947 CrashEvnt_D_Stat 1;
BA_ "U_CX430_MY2021_Rx" SG_ 947 CrashEvnt_D_Stat 1;
BA_ "U_U611_U625_MY20_Phev_Rx" SG_ 947 CrashEvnt_D_Stat 1;
BA_ "U_B562_MY18_Diesel_Rx" SG_ 947 CrashEvnt_D_Stat 1;
BA_ "U_CX482_CX483_MY20_Rx" SG_ 947 CrashEvnt_D_Stat 1;
BA_ "U_U611_U625_MY20_Hev_Rx" SG_ 947 CrashEvnt_D_Stat 1;
BA_ "U_U611_U625_MY20_Gas_Rx" SG_ 947 CrashEvnt_D_Stat 1;
BA_ "U_B500_MY18_Diesel_Rx" SG_ 947 CrashEvnt_D_Stat 1;
BA_ "U_B500_MY18_Gas_Rx" SG_ 947 CrashEvnt_D_Stat 1;
BA_ "U_C490_MY18_Rx" SG_ 947 CrashEvnt_D_Stat 1;
BA_ "U_B562_MY18_Gas_Rx" SG_ 947 CrashEvnt_D_Stat 1;
BA_ "U_C519_MY18_5_Gas_Rx" SG_ 947 CrashEvnt_D_Stat 1;
BA_ "U_C519_MY18_5_Diesel_Rx" SG_ 947 CrashEvnt_D_Stat 1;
BA_ "U_B515_MCA_MY17_Gas_Rx" SG_ 947 CrashEvnt_D_Stat 1;
BA_ "U_B515_MCA_MY17_Diesel_Rx" SG_ 947 CrashEvnt_D_Stat 1;
BA_ "U_B479_MY17_Diesel_Rx" SG_ 947 CrashEvnt_D_Stat 1;
BA_ "U_B479_MY17_Gas_Rx" SG_ 947 CrashEvnt_D_Stat 1;
BA_ "GenSigStartValue" SG_ 947 CrashEvnt_D_Stat 3;
BA_ "GenSigStartValueInteger" SG_ 947 CrashEvnt_D_Stat 3;
BA_ "CrossOver_InfoCAN" SG_ 947 CrashEvnt_D_Stat 1;
BA_ "WakeupSignal" SG_ 947 CrashEvnt_D_Stat 1;
BA_ "GenSigSendType" SG_ 947 FuelPmpInhbt_B_Stat 3;
BA_ "U_P702_MY2021_Rx" SG_ 947 FuelPmpInhbt_B_Stat 1;
BA_ "U_CX727_MY2021_Rx" SG_ 947 FuelPmpInhbt_B_Stat 1;
BA_ "U_CX430_MY2021_Rx" SG_ 947 FuelPmpInhbt_B_Stat 1;
BA_ "U_U611_U625_MY20_Phev_Rx" SG_ 947 FuelPmpInhbt_B_Stat 1;
BA_ "U_CX482_CX483_MY20_Rx" SG_ 947 FuelPmpInhbt_B_Stat 1;
BA_ "U_U611_U625_MY20_Hev_Rx" SG_ 947 FuelPmpInhbt_B_Stat 1;
BA_ "U_U611_U625_MY20_Gas_Rx" SG_ 947 FuelPmpInhbt_B_Stat 1;
BA_ "U_B500_MY18_Diesel_Rx" SG_ 947 FuelPmpInhbt_B_Stat 1;
BA_ "U_B500_MY18_Gas_Rx" SG_ 947 FuelPmpInhbt_B_Stat 1;
BA_ "U_C519_MY18_5_Gas_Rx" SG_ 947 FuelPmpInhbt_B_Stat 1;
BA_ "U_C519_MY18_5_Diesel_Rx" SG_ 947 FuelPmpInhbt_B_Stat 1;
BA_ "U_B515_MCA_MY17_Gas_Rx" SG_ 947 FuelPmpInhbt_B_Stat 1;
BA_ "U_B515_MCA_MY17_Diesel_Rx" SG_ 947 FuelPmpInhbt_B_Stat 1;
BA_ "U_B479_MY17_Diesel_Rx" SG_ 947 FuelPmpInhbt_B_Stat 1;
BA_ "U_B479_MY17_Gas_Rx" SG_ 947 FuelPmpInhbt_B_Stat 1;
BA_ "CrossOver_InfoCAN" SG_ 947 FuelPmpInhbt_B_Stat 1;
BA_ "CrossOver_InfoCAN" SG_ 947 BodySrvcRqd_B_Rq 1;
BA_ "U_P702_MY2021_Tx" SG_ 293 ClmtCtrlSeat_SetStat_Psgr 1;
BA_ "U_U611_U625_MY20_Phev_Tx" SG_ 293 ClmtCtrlSeat_SetStat_Psgr 1;
BA_ "U_CX482_CX483_MY20_Tx" SG_ 293 ClmtCtrlSeat_SetStat_Psgr 1;
BA_ "U_U611_U625_MY20_Hev_Tx" SG_ 293 ClmtCtrlSeat_SetStat_Psgr 1;
BA_ "U_U611_U625_MY20_Gas_Tx" SG_ 293 ClmtCtrlSeat_SetStat_Psgr 1;
BA_ "U_P702_MY2021_Rx" SG_ 293 ClmtCtrlSeat_SetStat_Psgr 1;
BA_ "U_CX727_MY2021_Rx" SG_ 293 ClmtCtrlSeat_SetStat_Psgr 1;
BA_ "U_U611_U625_MY20_Phev_Rx" SG_ 293 ClmtCtrlSeat_SetStat_Psgr 1;
BA_ "U_CX482_CX483_MY20_Rx" SG_ 293 ClmtCtrlSeat_SetStat_Psgr 1;
BA_ "U_U611_U625_MY20_Hev_Rx" SG_ 293 ClmtCtrlSeat_SetStat_Psgr 1;
BA_ "U_U611_U625_MY20_Gas_Rx" SG_ 293 ClmtCtrlSeat_SetStat_Psgr 1;
BA_ "U_B515_MCA_MY17_Gas_Rx" SG_ 293 ClmtCtrlSeat_SetStat_Psgr 1;
BA_ "U_B515_MCA_MY17_Diesel_Rx" SG_ 293 ClmtCtrlSeat_SetStat_Psgr 1;
BA_ "GenSigSendType" SG_ 293 ClmtCtrlSeat_SetStat_Psgr 3;
BA_ "U_P702_MY2021_Tx" SG_ 293 ClmtCtrlSeat_SetStat_Dvr 1;
BA_ "U_U611_U625_MY20_Phev_Tx" SG_ 293 ClmtCtrlSeat_SetStat_Dvr 1;
BA_ "U_CX482_CX483_MY20_Tx" SG_ 293 ClmtCtrlSeat_SetStat_Dvr 1;
BA_ "U_U611_U625_MY20_Hev_Tx" SG_ 293 ClmtCtrlSeat_SetStat_Dvr 1;
BA_ "U_U611_U625_MY20_Gas_Tx" SG_ 293 ClmtCtrlSeat_SetStat_Dvr 1;
BA_ "U_P702_MY2021_Rx" SG_ 293 ClmtCtrlSeat_SetStat_Dvr 1;
BA_ "U_CX727_MY2021_Rx" SG_ 293 ClmtCtrlSeat_SetStat_Dvr 1;
BA_ "U_U611_U625_MY20_Phev_Rx" SG_ 293 ClmtCtrlSeat_SetStat_Dvr 1;
BA_ "U_CX482_CX483_MY20_Rx" SG_ 293 ClmtCtrlSeat_SetStat_Dvr 1;
BA_ "U_U611_U625_MY20_Hev_Rx" SG_ 293 ClmtCtrlSeat_SetStat_Dvr 1;
BA_ "U_U611_U625_MY20_Gas_Rx" SG_ 293 ClmtCtrlSeat_SetStat_Dvr 1;
BA_ "U_B515_MCA_MY17_Gas_Rx" SG_ 293 ClmtCtrlSeat_SetStat_Dvr 1;
BA_ "U_B515_MCA_MY17_Diesel_Rx" SG_ 293 ClmtCtrlSeat_SetStat_Dvr 1;
BA_ "GenSigSendType" SG_ 293 ClmtCtrlSeat_SetStat_Dvr 3;
BA_ "U_P702_MY2021_Tx" SG_ 292 ClmtCtrlSeat_SetCmd_Psgr 1;
BA_ "U_CX727_MY2021_Tx" SG_ 292 ClmtCtrlSeat_SetCmd_Psgr 1;
BA_ "U_U611_U625_MY20_Phev_Tx" SG_ 292 ClmtCtrlSeat_SetCmd_Psgr 1;
BA_ "U_CX482_CX483_MY20_Tx" SG_ 292 ClmtCtrlSeat_SetCmd_Psgr 1;
BA_ "U_U611_U625_MY20_Hev_Tx" SG_ 292 ClmtCtrlSeat_SetCmd_Psgr 1;
BA_ "U_U611_U625_MY20_Gas_Tx" SG_ 292 ClmtCtrlSeat_SetCmd_Psgr 1;
BA_ "U_P702_MY2021_Rx" SG_ 292 ClmtCtrlSeat_SetCmd_Psgr 1;
BA_ "U_U611_U625_MY20_Phev_Rx" SG_ 292 ClmtCtrlSeat_SetCmd_Psgr 1;
BA_ "U_CX482_CX483_MY20_Rx" SG_ 292 ClmtCtrlSeat_SetCmd_Psgr 1;
BA_ "U_U611_U625_MY20_Hev_Rx" SG_ 292 ClmtCtrlSeat_SetCmd_Psgr 1;
BA_ "U_U611_U625_MY20_Gas_Rx" SG_ 292 ClmtCtrlSeat_SetCmd_Psgr 1;
BA_ "GenSigSendType" SG_ 292 ClmtCtrlSeat_SetCmd_Psgr 3;
BA_ "U_P702_MY2021_Tx" SG_ 292 ClmtCtrlSeat_SetCmd_Dvr 1;
BA_ "U_CX727_MY2021_Tx" SG_ 292 ClmtCtrlSeat_SetCmd_Dvr 1;
BA_ "U_U611_U625_MY20_Phev_Tx" SG_ 292 ClmtCtrlSeat_SetCmd_Dvr 1;
BA_ "U_CX482_CX483_MY20_Tx" SG_ 292 ClmtCtrlSeat_SetCmd_Dvr 1;
BA_ "U_U611_U625_MY20_Hev_Tx" SG_ 292 ClmtCtrlSeat_SetCmd_Dvr 1;
BA_ "U_U611_U625_MY20_Gas_Tx" SG_ 292 ClmtCtrlSeat_SetCmd_Dvr 1;
BA_ "U_P702_MY2021_Rx" SG_ 292 ClmtCtrlSeat_SetCmd_Dvr 1;
BA_ "U_U611_U625_MY20_Phev_Rx" SG_ 292 ClmtCtrlSeat_SetCmd_Dvr 1;
BA_ "U_CX482_CX483_MY20_Rx" SG_ 292 ClmtCtrlSeat_SetCmd_Dvr 1;
BA_ "U_U611_U625_MY20_Hev_Rx" SG_ 292 ClmtCtrlSeat_SetCmd_Dvr 1;
BA_ "U_U611_U625_MY20_Gas_Rx" SG_ 292 ClmtCtrlSeat_SetCmd_Dvr 1;
BA_ "GenSigSendType" SG_ 292 ClmtCtrlSeat_SetCmd_Dvr 3;
BA_ "U_CX430_MY2021_Rx" SG_ 1126 GpsUtcYr_No_Actl 1;
BA_ "U_CX482_CX483_MY20_Rx" SG_ 1126 GpsUtcYr_No_Actl 1;
BA_ "U_C519_MY18_5_Gas_Rx" SG_ 1126 GpsUtcYr_No_Actl 1;
BA_ "U_C519_MY18_5_Diesel_Rx" SG_ 1126 GpsUtcYr_No_Actl 1;
BA_ "U_B515_MCA_MY17_Gas_Rx" SG_ 1126 GpsUtcYr_No_Actl 1;
BA_ "U_B515_MCA_MY17_Diesel_Rx" SG_ 1126 GpsUtcYr_No_Actl 1;
BA_ "CrossOver_InfoCAN" SG_ 1126 GpsUtcYr_No_Actl 1;
BA_ "U_CX430_MY2021_Rx" SG_ 1126 GpsUtcMnth_No_Actl 1;
BA_ "U_CX482_CX483_MY20_Rx" SG_ 1126 GpsUtcMnth_No_Actl 1;
BA_ "U_C519_MY18_5_Gas_Rx" SG_ 1126 GpsUtcMnth_No_Actl 1;
BA_ "U_C519_MY18_5_Diesel_Rx" SG_ 1126 GpsUtcMnth_No_Actl 1;
BA_ "U_B515_MCA_MY17_Gas_Rx" SG_ 1126 GpsUtcMnth_No_Actl 1;
BA_ "U_B515_MCA_MY17_Diesel_Rx" SG_ 1126 GpsUtcMnth_No_Actl 1;
BA_ "GenSigStartValue" SG_ 1126 GpsUtcMnth_No_Actl 1;
BA_ "GenSigStartValueInteger" SG_ 1126 GpsUtcMnth_No_Actl 1;
BA_ "CrossOver_InfoCAN" SG_ 1126 GpsUtcMnth_No_Actl 1;
BA_ "U_CX430_MY2021_Rx" SG_ 1126 GpsUtcDay_No_Actl 1;
BA_ "U_CX482_CX483_MY20_Rx" SG_ 1126 GpsUtcDay_No_Actl 1;
BA_ "U_C519_MY18_5_Gas_Rx" SG_ 1126 GpsUtcDay_No_Actl 1;
BA_ "U_C519_MY18_5_Diesel_Rx" SG_ 1126 GpsUtcDay_No_Actl 1;
BA_ "U_B515_MCA_MY17_Gas_Rx" SG_ 1126 GpsUtcDay_No_Actl 1;
BA_ "U_B515_MCA_MY17_Diesel_Rx" SG_ 1126 GpsUtcDay_No_Actl 1;
BA_ "GenSigStartValue" SG_ 1126 GpsUtcDay_No_Actl 1;
BA_ "GenSigStartValueInteger" SG_ 1126 GpsUtcDay_No_Actl 1;
BA_ "CrossOver_InfoCAN" SG_ 1126 GpsUtcDay_No_Actl 1;
BA_ "U_CX430_MY2021_Rx" SG_ 1126 GPS_UTC_seconds 1;
BA_ "U_CX482_CX483_MY20_Rx" SG_ 1126 GPS_UTC_seconds 1;
BA_ "U_C519_MY18_5_Gas_Rx" SG_ 1126 GPS_UTC_seconds 1;
BA_ "U_C519_MY18_5_Diesel_Rx" SG_ 1126 GPS_UTC_seconds 1;
BA_ "U_B515_MCA_MY17_Gas_Rx" SG_ 1126 GPS_UTC_seconds 1;
BA_ "U_B515_MCA_MY17_Diesel_Rx" SG_ 1126 GPS_UTC_seconds 1;
BA_ "CrossOver_InfoCAN" SG_ 1126 GPS_UTC_seconds 1;
BA_ "U_CX430_MY2021_Rx" SG_ 1126 GPS_UTC_minutes 1;
BA_ "U_CX482_CX483_MY20_Rx" SG_ 1126 GPS_UTC_minutes 1;
BA_ "U_C519_MY18_5_Gas_Rx" SG_ 1126 GPS_UTC_minutes 1;
BA_ "U_C519_MY18_5_Diesel_Rx" SG_ 1126 GPS_UTC_minutes 1;
BA_ "U_B515_MCA_MY17_Gas_Rx" SG_ 1126 GPS_UTC_minutes 1;
BA_ "U_B515_MCA_MY17_Diesel_Rx" SG_ 1126 GPS_UTC_minutes 1;
BA_ "CrossOver_InfoCAN" SG_ 1126 GPS_UTC_minutes 1;
BA_ "U_CX430_MY2021_Rx" SG_ 1126 GPS_UTC_hours 1;
BA_ "U_CX482_CX483_MY20_Rx" SG_ 1126 GPS_UTC_hours 1;
BA_ "U_C519_MY18_5_Gas_Rx" SG_ 1126 GPS_UTC_hours 1;
BA_ "U_C519_MY18_5_Diesel_Rx" SG_ 1126 GPS_UTC_hours 1;
BA_ "U_B515_MCA_MY17_Gas_Rx" SG_ 1126 GPS_UTC_hours 1;
BA_ "U_B515_MCA_MY17_Diesel_Rx" SG_ 1126 GPS_UTC_hours 1;
BA_ "CrossOver_InfoCAN" SG_ 1126 GPS_UTC_hours 1;
BA_ "U_CX430_MY2021_Rx" SG_ 1126 GPS_Pdop 1;
BA_ "U_CX482_CX483_MY20_Rx" SG_ 1126 GPS_Pdop 1;
BA_ "U_C519_MY18_5_Gas_Rx" SG_ 1126 GPS_Pdop 1;
BA_ "U_C519_MY18_5_Diesel_Rx" SG_ 1126 GPS_Pdop 1;
BA_ "U_B515_MCA_MY17_Gas_Rx" SG_ 1126 GPS_Pdop 1;
BA_ "U_B515_MCA_MY17_Diesel_Rx" SG_ 1126 GPS_Pdop 1;
BA_ "CrossOver_InfoCAN" SG_ 1126 GPS_Pdop 1;
BA_ "U_CX430_MY2021_Rx" SG_ 1126 GPS_Compass_direction 1;
BA_ "U_CX482_CX483_MY20_Rx" SG_ 1126 GPS_Compass_direction 1;
BA_ "U_C519_MY18_5_Gas_Rx" SG_ 1126 GPS_Compass_direction 1;
BA_ "U_C519_MY18_5_Diesel_Rx" SG_ 1126 GPS_Compass_direction 1;
BA_ "U_B515_MCA_MY17_Gas_Rx" SG_ 1126 GPS_Compass_direction 1;
BA_ "U_B515_MCA_MY17_Diesel_Rx" SG_ 1126 GPS_Compass_direction 1;
BA_ "CrossOver_InfoCAN" SG_ 1126 GPS_Compass_direction 1;
BA_ "U_CX430_MY2021_Rx" SG_ 1126 GPS_Actual_vs_Infer_pos 1;
BA_ "U_CX482_CX483_MY20_Rx" SG_ 1126 GPS_Actual_vs_Infer_pos 1;
BA_ "U_C519_MY18_5_Gas_Rx" SG_ 1126 GPS_Actual_vs_Infer_pos 1;
BA_ "U_C519_MY18_5_Diesel_Rx" SG_ 1126 GPS_Actual_vs_Infer_pos 1;
BA_ "U_B515_MCA_MY17_Gas_Rx" SG_ 1126 GPS_Actual_vs_Infer_pos 1;
BA_ "U_B515_MCA_MY17_Diesel_Rx" SG_ 1126 GPS_Actual_vs_Infer_pos 1;
BA_ "GenSigSendType" SG_ 1126 GPS_Actual_vs_Infer_pos 1;
BA_ "CrossOver_InfoCAN" SG_ 1126 GPS_Actual_vs_Infer_pos 1;
BA_ "U_CX430_MY2021_Rx" SG_ 1126 Gps_B_Falt 1;
BA_ "U_CX482_CX483_MY20_Rx" SG_ 1126 Gps_B_Falt 1;
BA_ "U_C519_MY18_5_Gas_Rx" SG_ 1126 Gps_B_Falt 1;
BA_ "U_C519_MY18_5_Diesel_Rx" SG_ 1126 Gps_B_Falt 1;
BA_ "U_B515_MCA_MY17_Gas_Rx" SG_ 1126 Gps_B_Falt 1;
BA_ "U_B515_MCA_MY17_Diesel_Rx" SG_ 1126 Gps_B_Falt 1;
BA_ "CrossOver_InfoCAN" SG_ 1126 Gps_B_Falt 1;
BA_ "U_CX430_MY2021_Rx" SG_ 1125 GpsHsphLongEast_D_Actl 1;
BA_ "U_CX482_CX483_MY20_Rx" SG_ 1125 GpsHsphLongEast_D_Actl 1;
BA_ "U_C519_MY18_5_Gas_Rx" SG_ 1125 GpsHsphLongEast_D_Actl 1;
BA_ "U_C519_MY18_5_Diesel_Rx" SG_ 1125 GpsHsphLongEast_D_Actl 1;
BA_ "U_B515_MCA_MY17_Gas_Rx" SG_ 1125 GpsHsphLongEast_D_Actl 1;
BA_ "U_B515_MCA_MY17_Diesel_Rx" SG_ 1125 GpsHsphLongEast_D_Actl 1;
BA_ "GenSigSendType" SG_ 1125 GpsHsphLongEast_D_Actl 1;
BA_ "CrossOver_InfoCAN" SG_ 1125 GpsHsphLongEast_D_Actl 1;
BA_ "U_CX430_MY2021_Rx" SG_ 1125 GpsHsphLattSth_D_Actl 1;
BA_ "U_CX482_CX483_MY20_Rx" SG_ 1125 GpsHsphLattSth_D_Actl 1;
BA_ "U_C519_MY18_5_Gas_Rx" SG_ 1125 GpsHsphLattSth_D_Actl 1;
BA_ "U_C519_MY18_5_Diesel_Rx" SG_ 1125 GpsHsphLattSth_D_Actl 1;
BA_ "U_B515_MCA_MY17_Gas_Rx" SG_ 1125 GpsHsphLattSth_D_Actl 1;
BA_ "U_B515_MCA_MY17_Diesel_Rx" SG_ 1125 GpsHsphLattSth_D_Actl 1;
BA_ "CrossOver_InfoCAN" SG_ 1125 GpsHsphLattSth_D_Actl 1;
BA_ "U_CX430_MY2021_Rx" SG_ 1125 GPS_Longitude_Minutes 1;
BA_ "U_CX482_CX483_MY20_Rx" SG_ 1125 GPS_Longitude_Minutes 1;
BA_ "U_C519_MY18_5_Gas_Rx" SG_ 1125 GPS_Longitude_Minutes 1;
BA_ "U_C519_MY18_5_Diesel_Rx" SG_ 1125 GPS_Longitude_Minutes 1;
BA_ "U_B515_MCA_MY17_Gas_Rx" SG_ 1125 GPS_Longitude_Minutes 1;
BA_ "U_B515_MCA_MY17_Diesel_Rx" SG_ 1125 GPS_Longitude_Minutes 1;
BA_ "CrossOver_InfoCAN" SG_ 1125 GPS_Longitude_Minutes 1;
BA_ "U_CX430_MY2021_Rx" SG_ 1125 GPS_Longitude_Min_dec 1;
BA_ "U_CX482_CX483_MY20_Rx" SG_ 1125 GPS_Longitude_Min_dec 1;
BA_ "U_C519_MY18_5_Gas_Rx" SG_ 1125 GPS_Longitude_Min_dec 1;
BA_ "U_C519_MY18_5_Diesel_Rx" SG_ 1125 GPS_Longitude_Min_dec 1;
BA_ "U_B515_MCA_MY17_Gas_Rx" SG_ 1125 GPS_Longitude_Min_dec 1;
BA_ "U_B515_MCA_MY17_Diesel_Rx" SG_ 1125 GPS_Longitude_Min_dec 1;
BA_ "CrossOver_InfoCAN" SG_ 1125 GPS_Longitude_Min_dec 1;
BA_ "U_CX430_MY2021_Rx" SG_ 1125 GPS_Longitude_Degrees 1;
BA_ "U_CX482_CX483_MY20_Rx" SG_ 1125 GPS_Longitude_Degrees 1;
BA_ "U_C519_MY18_5_Gas_Rx" SG_ 1125 GPS_Longitude_Degrees 1;
BA_ "U_C519_MY18_5_Diesel_Rx" SG_ 1125 GPS_Longitude_Degrees 1;
BA_ "U_B515_MCA_MY17_Gas_Rx" SG_ 1125 GPS_Longitude_Degrees 1;
BA_ "U_B515_MCA_MY17_Diesel_Rx" SG_ 1125 GPS_Longitude_Degrees 1;
BA_ "GenSigStartValueInteger" SG_ 1125 GPS_Longitude_Degrees 179;
BA_ "CrossOver_InfoCAN" SG_ 1125 GPS_Longitude_Degrees 1;
BA_ "U_CX430_MY2021_Rx" SG_ 1125 GPS_Latitude_Minutes 1;
BA_ "U_CX482_CX483_MY20_Rx" SG_ 1125 GPS_Latitude_Minutes 1;
BA_ "U_C519_MY18_5_Gas_Rx" SG_ 1125 GPS_Latitude_Minutes 1;
BA_ "U_C519_MY18_5_Diesel_Rx" SG_ 1125 GPS_Latitude_Minutes 1;
BA_ "U_B515_MCA_MY17_Gas_Rx" SG_ 1125 GPS_Latitude_Minutes 1;
BA_ "U_B515_MCA_MY17_Diesel_Rx" SG_ 1125 GPS_Latitude_Minutes 1;
BA_ "CrossOver_InfoCAN" SG_ 1125 GPS_Latitude_Minutes 1;
BA_ "U_CX430_MY2021_Rx" SG_ 1125 GPS_Latitude_Min_dec 1;
BA_ "U_CX482_CX483_MY20_Rx" SG_ 1125 GPS_Latitude_Min_dec 1;
BA_ "U_C519_MY18_5_Gas_Rx" SG_ 1125 GPS_Latitude_Min_dec 1;
BA_ "U_C519_MY18_5_Diesel_Rx" SG_ 1125 GPS_Latitude_Min_dec 1;
BA_ "U_B515_MCA_MY17_Gas_Rx" SG_ 1125 GPS_Latitude_Min_dec 1;
BA_ "U_B515_MCA_MY17_Diesel_Rx" SG_ 1125 GPS_Latitude_Min_dec 1;
BA_ "CrossOver_InfoCAN" SG_ 1125 GPS_Latitude_Min_dec 1;
BA_ "U_CX430_MY2021_Rx" SG_ 1125 GPS_Latitude_Degrees 1;
BA_ "U_CX482_CX483_MY20_Rx" SG_ 1125 GPS_Latitude_Degrees 1;
BA_ "U_C519_MY18_5_Gas_Rx" SG_ 1125 GPS_Latitude_Degrees 1;
BA_ "U_C519_MY18_5_Diesel_Rx" SG_ 1125 GPS_Latitude_Degrees 1;
BA_ "U_B515_MCA_MY17_Gas_Rx" SG_ 1125 GPS_Latitude_Degrees 1;
BA_ "U_B515_MCA_MY17_Diesel_Rx" SG_ 1125 GPS_Latitude_Degrees 1;
BA_ "CrossOver_InfoCAN" SG_ 1125 GPS_Latitude_Degrees 1;
BA_ "U_B500_MY18_Diesel_Rx" SG_ 992 MsgCntrFeatNoRq 1;
BA_ "U_B500_MY18_Gas_Rx" SG_ 992 MsgCntrFeatNoRq 1;
BA_ "U_C519_MY18_5_Gas_Rx" SG_ 992 MsgCntrFeatNoRq 1;
BA_ "U_C519_MY18_5_Diesel_Rx" SG_ 992 MsgCntrFeatNoRq 1;
BA_ "U_B515_MCA_MY17_Gas_Rx" SG_ 992 MsgCntrFeatNoRq 1;
BA_ "U_B515_MCA_MY17_Diesel_Rx" SG_ 992 MsgCntrFeatNoRq 1;
BA_ "U_B479_MY17_Diesel_Rx" SG_ 992 MsgCntrFeatNoRq 1;
BA_ "U_B479_MY17_Gas_Rx" SG_ 992 MsgCntrFeatNoRq 1;
BA_ "U_P702_MY2021_Rx" SG_ 992 MsgCntrFeatNoRq 1;
BA_ "U_CX727_MY2021_Rx" SG_ 992 MsgCntrFeatNoRq 1;
BA_ "U_CX430_MY2021_Rx" SG_ 992 MsgCntrFeatNoRq 1;
BA_ "U_U611_U625_MY20_Phev_Rx" SG_ 992 MsgCntrFeatNoRq 1;
BA_ "U_CX482_CX483_MY20_Rx" SG_ 992 MsgCntrFeatNoRq 1;
BA_ "U_U611_U625_MY20_Hev_Rx" SG_ 992 MsgCntrFeatNoRq 1;
BA_ "U_U611_U625_MY20_Gas_Rx" SG_ 992 MsgCntrFeatNoRq 1;
BA_ "GenSigSendType" SG_ 992 MsgCntrFeatNoRq 3;
BA_ "CrossOver_InfoCAN" SG_ 992 MsgCntrFeatNoRq 1;
BA_ "U_B500_MY18_Diesel_Rx" SG_ 992 MsgCntrDsplyOp_D_Rq 1;
BA_ "U_B500_MY18_Gas_Rx" SG_ 992 MsgCntrDsplyOp_D_Rq 1;
BA_ "U_C519_MY18_5_Gas_Rx" SG_ 992 MsgCntrDsplyOp_D_Rq 1;
BA_ "U_C519_MY18_5_Diesel_Rx" SG_ 992 MsgCntrDsplyOp_D_Rq 1;
BA_ "U_B515_MCA_MY17_Gas_Rx" SG_ 992 MsgCntrDsplyOp_D_Rq 1;
BA_ "U_B515_MCA_MY17_Diesel_Rx" SG_ 992 MsgCntrDsplyOp_D_Rq 1;
BA_ "U_B479_MY17_Diesel_Rx" SG_ 992 MsgCntrDsplyOp_D_Rq 1;
BA_ "U_B479_MY17_Gas_Rx" SG_ 992 MsgCntrDsplyOp_D_Rq 1;
BA_ "U_P702_MY2021_Rx" SG_ 992 MsgCntrDsplyOp_D_Rq 1;
BA_ "U_CX727_MY2021_Rx" SG_ 992 MsgCntrDsplyOp_D_Rq 1;
BA_ "U_CX430_MY2021_Rx" SG_ 992 MsgCntrDsplyOp_D_Rq 1;
BA_ "U_U611_U625_MY20_Phev_Rx" SG_ 992 MsgCntrDsplyOp_D_Rq 1;
BA_ "U_CX482_CX483_MY20_Rx" SG_ 992 MsgCntrDsplyOp_D_Rq 1;
BA_ "U_U611_U625_MY20_Hev_Rx" SG_ 992 MsgCntrDsplyOp_D_Rq 1;
BA_ "U_U611_U625_MY20_Gas_Rx" SG_ 992 MsgCntrDsplyOp_D_Rq 1;
BA_ "GenSigSendType" SG_ 992 MsgCntrDsplyOp_D_Rq 3;
BA_ "CrossOver_InfoCAN" SG_ 992 MsgCntrDsplyOp_D_Rq 1;
BA_ "U_B500_MY18_Diesel_Rx" SG_ 992 MsgCntrPersIndex_D_Rq 1;
BA_ "U_B500_MY18_Gas_Rx" SG_ 992 MsgCntrPersIndex_D_Rq 1;
BA_ "U_C519_MY18_5_Gas_Rx" SG_ 992 MsgCntrPersIndex_D_Rq 1;
BA_ "U_C519_MY18_5_Diesel_Rx" SG_ 992 MsgCntrPersIndex_D_Rq 1;
BA_ "U_B515_MCA_MY17_Gas_Rx" SG_ 992 MsgCntrPersIndex_D_Rq 1;
BA_ "U_B515_MCA_MY17_Diesel_Rx" SG_ 992 MsgCntrPersIndex_D_Rq 1;
BA_ "U_B479_MY17_Diesel_Rx" SG_ 992 MsgCntrPersIndex_D_Rq 1;
BA_ "U_B479_MY17_Gas_Rx" SG_ 992 MsgCntrPersIndex_D_Rq 1;
BA_ "U_P702_MY2021_Rx" SG_ 992 MsgCntrPersIndex_D_Rq 1;
BA_ "U_CX727_MY2021_Rx" SG_ 992 MsgCntrPersIndex_D_Rq 1;
BA_ "U_CX430_MY2021_Rx" SG_ 992 MsgCntrPersIndex_D_Rq 1;
BA_ "U_U611_U625_MY20_Phev_Rx" SG_ 992 MsgCntrPersIndex_D_Rq 1;
BA_ "U_CX482_CX483_MY20_Rx" SG_ 992 MsgCntrPersIndex_D_Rq 1;
BA_ "U_U611_U625_MY20_Hev_Rx" SG_ 992 MsgCntrPersIndex_D_Rq 1;
BA_ "U_U611_U625_MY20_Gas_Rx" SG_ 992 MsgCntrPersIndex_D_Rq 1;
BA_ "GenSigSendType" SG_ 992 MsgCntrPersIndex_D_Rq 3;
BA_ "GenSigStartValue" SG_ 992 MsgCntrPersIndex_D_Rq 4;
BA_ "GenSigStartValueInteger" SG_ 992 MsgCntrPersIndex_D_Rq 4;
BA_ "CrossOver_InfoCAN" SG_ 992 MsgCntrPersIndex_D_Rq 1;
BA_ "U_B500_MY18_Diesel_Rx" SG_ 992 MsgCntrFeatConfigRq 1;
BA_ "U_B500_MY18_Gas_Rx" SG_ 992 MsgCntrFeatConfigRq 1;
BA_ "U_C519_MY18_5_Gas_Rx" SG_ 992 MsgCntrFeatConfigRq 1;
BA_ "U_C519_MY18_5_Diesel_Rx" SG_ 992 MsgCntrFeatConfigRq 1;
BA_ "U_B515_MCA_MY17_Gas_Rx" SG_ 992 MsgCntrFeatConfigRq 1;
BA_ "U_B515_MCA_MY17_Diesel_Rx" SG_ 992 MsgCntrFeatConfigRq 1;
BA_ "U_B479_MY17_Diesel_Rx" SG_ 992 MsgCntrFeatConfigRq 1;
BA_ "U_B479_MY17_Gas_Rx" SG_ 992 MsgCntrFeatConfigRq 1;
BA_ "U_P702_MY2021_Rx" SG_ 992 MsgCntrFeatConfigRq 1;
BA_ "U_CX727_MY2021_Rx" SG_ 992 MsgCntrFeatConfigRq 1;
BA_ "U_CX430_MY2021_Rx" SG_ 992 MsgCntrFeatConfigRq 1;
BA_ "U_U611_U625_MY20_Phev_Rx" SG_ 992 MsgCntrFeatConfigRq 1;
BA_ "U_CX482_CX483_MY20_Rx" SG_ 992 MsgCntrFeatConfigRq 1;
BA_ "U_U611_U625_MY20_Hev_Rx" SG_ 992 MsgCntrFeatConfigRq 1;
BA_ "U_U611_U625_MY20_Gas_Rx" SG_ 992 MsgCntrFeatConfigRq 1;
BA_ "GenSigSendType" SG_ 992 MsgCntrFeatConfigRq 3;
BA_ "CrossOver_InfoCAN" SG_ 992 MsgCntrFeatConfigRq 1;
BA_ "U_CX430_MY2021_Rx" SG_ 1127 GPS_Vdop 1;
BA_ "U_CX482_CX483_MY20_Rx" SG_ 1127 GPS_Vdop 1;
BA_ "U_C519_MY18_5_Gas_Rx" SG_ 1127 GPS_Vdop 1;
BA_ "U_C519_MY18_5_Diesel_Rx" SG_ 1127 GPS_Vdop 1;
BA_ "U_B515_MCA_MY17_Gas_Rx" SG_ 1127 GPS_Vdop 1;
BA_ "U_B515_MCA_MY17_Diesel_Rx" SG_ 1127 GPS_Vdop 1;
BA_ "GenSigSendType" SG_ 1127 GPS_Vdop 1;
BA_ "CrossOver_InfoCAN" SG_ 1127 GPS_Vdop 1;
BA_ "U_CX430_MY2021_Rx" SG_ 1127 GPS_Speed 1;
BA_ "U_CX482_CX483_MY20_Rx" SG_ 1127 GPS_Speed 1;
BA_ "U_C519_MY18_5_Gas_Rx" SG_ 1127 GPS_Speed 1;
BA_ "U_C519_MY18_5_Diesel_Rx" SG_ 1127 GPS_Speed 1;
BA_ "U_B515_MCA_MY17_Gas_Rx" SG_ 1127 GPS_Speed 1;
BA_ "U_B515_MCA_MY17_Diesel_Rx" SG_ 1127 GPS_Speed 1;
BA_ "CrossOver_InfoCAN" SG_ 1127 GPS_Speed 1;
BA_ "U_CX430_MY2021_Rx" SG_ 1127 GPS_Sat_num_in_view 1;
BA_ "U_CX482_CX483_MY20_Rx" SG_ 1127 GPS_Sat_num_in_view 1;
BA_ "U_C519_MY18_5_Gas_Rx" SG_ 1127 GPS_Sat_num_in_view 1;
BA_ "U_C519_MY18_5_Diesel_Rx" SG_ 1127 GPS_Sat_num_in_view 1;
BA_ "U_B515_MCA_MY17_Gas_Rx" SG_ 1127 GPS_Sat_num_in_view 1;
BA_ "U_B515_MCA_MY17_Diesel_Rx" SG_ 1127 GPS_Sat_num_in_view 1;
BA_ "CrossOver_InfoCAN" SG_ 1127 GPS_Sat_num_in_view 1;
BA_ "U_CX430_MY2021_Rx" SG_ 1127 GPS_MSL_altitude 1;
BA_ "U_CX482_CX483_MY20_Rx" SG_ 1127 GPS_MSL_altitude 1;
BA_ "U_C519_MY18_5_Gas_Rx" SG_ 1127 GPS_MSL_altitude 1;
BA_ "U_C519_MY18_5_Diesel_Rx" SG_ 1127 GPS_MSL_altitude 1;
BA_ "U_B515_MCA_MY17_Gas_Rx" SG_ 1127 GPS_MSL_altitude 1;
BA_ "U_B515_MCA_MY17_Diesel_Rx" SG_ 1127 GPS_MSL_altitude 1;
BA_ "CrossOver_InfoCAN" SG_ 1127 GPS_MSL_altitude 1;
BA_ "U_CX430_MY2021_Rx" SG_ 1127 GPS_Heading 1;
BA_ "U_CX482_CX483_MY20_Rx" SG_ 1127 GPS_Heading 1;
BA_ "U_C519_MY18_5_Gas_Rx" SG_ 1127 GPS_Heading 1;
BA_ "U_C519_MY18_5_Diesel_Rx" SG_ 1127 GPS_Heading 1;
BA_ "U_B515_MCA_MY17_Gas_Rx" SG_ 1127 GPS_Heading 1;
BA_ "U_B515_MCA_MY17_Diesel_Rx" SG_ 1127 GPS_Heading 1;
BA_ "CrossOver_InfoCAN" SG_ 1127 GPS_Heading 1;
BA_ "U_CX430_MY2021_Rx" SG_ 1127 GPS_Hdop 1;
BA_ "U_CX482_CX483_MY20_Rx" SG_ 1127 GPS_Hdop 1;
BA_ "U_C519_MY18_5_Gas_Rx" SG_ 1127 GPS_Hdop 1;
BA_ "U_C519_MY18_5_Diesel_Rx" SG_ 1127 GPS_Hdop 1;
BA_ "U_B515_MCA_MY17_Gas_Rx" SG_ 1127 GPS_Hdop 1;
BA_ "U_B515_MCA_MY17_Diesel_Rx" SG_ 1127 GPS_Hdop 1;
BA_ "CrossOver_InfoCAN" SG_ 1127 GPS_Hdop 1;
BA_ "U_CX430_MY2021_Rx" SG_ 1127 GPS_dimension 1;
BA_ "U_CX482_CX483_MY20_Rx" SG_ 1127 GPS_dimension 1;
BA_ "U_C519_MY18_5_Gas_Rx" SG_ 1127 GPS_dimension 1;
BA_ "U_C519_MY18_5_Diesel_Rx" SG_ 1127 GPS_dimension 1;
BA_ "U_B515_MCA_MY17_Gas_Rx" SG_ 1127 GPS_dimension 1;
BA_ "U_B515_MCA_MY17_Diesel_Rx" SG_ 1127 GPS_dimension 1;
BA_ "CrossOver_InfoCAN" SG_ 1127 GPS_dimension 1;
BA_ "U_P702_MY2021_Tx" SG_ 999 FeatNoFcimActl 1;
BA_ "U_CX727_MY2021_Tx" SG_ 999 FeatNoFcimActl 1;
BA_ "U_CX430_MY2021_Tx" SG_ 999 FeatNoFcimActl 1;
BA_ "U_U611_U625_MY20_Phev_Tx" SG_ 999 FeatNoFcimActl 1;
BA_ "U_CX482_CX483_MY20_Tx" SG_ 999 FeatNoFcimActl 1;
BA_ "U_U611_U625_MY20_Hev_Tx" SG_ 999 FeatNoFcimActl 1;
BA_ "U_U611_U625_MY20_Gas_Tx" SG_ 999 FeatNoFcimActl 1;
BA_ "U_B500_MY18_Diesel_Tx" SG_ 999 FeatNoFcimActl 1;
BA_ "U_B500_MY18_Gas_Tx" SG_ 999 FeatNoFcimActl 1;
BA_ "U_C519_MY18_5_Gas_Tx" SG_ 999 FeatNoFcimActl 1;
BA_ "U_C519_MY18_5_Diesel_Tx" SG_ 999 FeatNoFcimActl 1;
BA_ "U_B515_MCA_MY17_Gas_Tx" SG_ 999 FeatNoFcimActl 1;
BA_ "U_B515_MCA_MY17_Diesel_Tx" SG_ 999 FeatNoFcimActl 1;
BA_ "U_B479_MY17_Diesel_Tx" SG_ 999 FeatNoFcimActl 1;
BA_ "U_B479_MY17_Gas_Tx" SG_ 999 FeatNoFcimActl 1;
BA_ "GenSigSendType" SG_ 999 FeatNoFcimActl 3;
BA_ "CrossOver_InfoCAN" SG_ 999 FeatNoFcimActl 1;
BA_ "U_P702_MY2021_Tx" SG_ 999 FeatConfigFcimActl 1;
BA_ "U_CX727_MY2021_Tx" SG_ 999 FeatConfigFcimActl 1;
BA_ "U_CX430_MY2021_Tx" SG_ 999 FeatConfigFcimActl 1;
BA_ "U_U611_U625_MY20_Phev_Tx" SG_ 999 FeatConfigFcimActl 1;
BA_ "U_CX482_CX483_MY20_Tx" SG_ 999 FeatConfigFcimActl 1;
BA_ "U_U611_U625_MY20_Hev_Tx" SG_ 999 FeatConfigFcimActl 1;
BA_ "U_U611_U625_MY20_Gas_Tx" SG_ 999 FeatConfigFcimActl 1;
BA_ "U_B500_MY18_Diesel_Tx" SG_ 999 FeatConfigFcimActl 1;
BA_ "U_B500_MY18_Gas_Tx" SG_ 999 FeatConfigFcimActl 1;
BA_ "U_C519_MY18_5_Gas_Tx" SG_ 999 FeatConfigFcimActl 1;
BA_ "U_C519_MY18_5_Diesel_Tx" SG_ 999 FeatConfigFcimActl 1;
BA_ "U_B515_MCA_MY17_Gas_Tx" SG_ 999 FeatConfigFcimActl 1;
BA_ "U_B515_MCA_MY17_Diesel_Tx" SG_ 999 FeatConfigFcimActl 1;
BA_ "U_B479_MY17_Diesel_Tx" SG_ 999 FeatConfigFcimActl 1;
BA_ "U_B479_MY17_Gas_Tx" SG_ 999 FeatConfigFcimActl 1;
BA_ "GenSigSendType" SG_ 999 FeatConfigFcimActl 3;
BA_ "CrossOver_InfoCAN" SG_ 999 FeatConfigFcimActl 1;
BA_ "U_P702_MY2021_Tx" SG_ 999 PersIndexFcim_D_Actl 1;
BA_ "U_CX727_MY2021_Tx" SG_ 999 PersIndexFcim_D_Actl 1;
BA_ "U_CX430_MY2021_Tx" SG_ 999 PersIndexFcim_D_Actl 1;
BA_ "U_U611_U625_MY20_Phev_Tx" SG_ 999 PersIndexFcim_D_Actl 1;
BA_ "U_CX482_CX483_MY20_Tx" SG_ 999 PersIndexFcim_D_Actl 1;
BA_ "U_U611_U625_MY20_Hev_Tx" SG_ 999 PersIndexFcim_D_Actl 1;
BA_ "U_U611_U625_MY20_Gas_Tx" SG_ 999 PersIndexFcim_D_Actl 1;
BA_ "U_B500_MY18_Diesel_Tx" SG_ 999 PersIndexFcim_D_Actl 1;
BA_ "U_B500_MY18_Gas_Tx" SG_ 999 PersIndexFcim_D_Actl 1;
BA_ "U_C519_MY18_5_Gas_Tx" SG_ 999 PersIndexFcim_D_Actl 1;
BA_ "U_C519_MY18_5_Diesel_Tx" SG_ 999 PersIndexFcim_D_Actl 1;
BA_ "U_B515_MCA_MY17_Gas_Tx" SG_ 999 PersIndexFcim_D_Actl 1;
BA_ "U_B515_MCA_MY17_Diesel_Tx" SG_ 999 PersIndexFcim_D_Actl 1;
BA_ "U_B479_MY17_Diesel_Tx" SG_ 999 PersIndexFcim_D_Actl 1;
BA_ "U_B479_MY17_Gas_Tx" SG_ 999 PersIndexFcim_D_Actl 1;
BA_ "GenSigSendType" SG_ 999 PersIndexFcim_D_Actl 3;
BA_ "GenSigStartValue" SG_ 999 PersIndexFcim_D_Actl 4;
BA_ "GenSigStartValueInteger" SG_ 999 PersIndexFcim_D_Actl 4;
BA_ "CrossOver_InfoCAN" SG_ 999 PersIndexFcim_D_Actl 1;
BA_ "U_CX727_MY2021_Tx" SG_ 1998 TesterPhysicalResSODR 1;
BA_ "U_CX430_MY2021_Tx" SG_ 1998 TesterPhysicalResSODR 1;
BA_ "U_U611_U625_MY20_Phev_Tx" SG_ 1998 TesterPhysicalResSODR 1;
BA_ "U_CX482_CX483_MY20_Tx" SG_ 1998 TesterPhysicalResSODR 1;
BA_ "U_U611_U625_MY20_Hev_Tx" SG_ 1998 TesterPhysicalResSODR 1;
BA_ "U_U611_U625_MY20_Gas_Tx" SG_ 1998 TesterPhysicalResSODR 1;
BA_ "U_C519_MY18_5_Gas_Tx" SG_ 1998 TesterPhysicalResSODR 1;
BA_ "U_C519_MY18_5_Diesel_Tx" SG_ 1998 TesterPhysicalResSODR 1;
BA_ "U_B515_MCA_MY17_Gas_Tx" SG_ 1998 TesterPhysicalResSODR 1;
BA_ "U_B515_MCA_MY17_Diesel_Tx" SG_ 1998 TesterPhysicalResSODR 1;
BA_ "U_B479_MY17_Diesel_Tx" SG_ 1998 TesterPhysicalResSODR 1;
BA_ "U_B479_MY17_Gas_Tx" SG_ 1998 TesterPhysicalResSODR 1;
BA_ "GenSigSendType" SG_ 1998 TesterPhysicalResSODR 3;
BA_ "U_CX727_MY2021_Rx" SG_ 1990 TesterPhysicalReqSODR 1;
BA_ "U_CX430_MY2021_Rx" SG_ 1990 TesterPhysicalReqSODR 1;
BA_ "U_U611_U625_MY20_Phev_Rx" SG_ 1990 TesterPhysicalReqSODR 1;
BA_ "U_CX482_CX483_MY20_Rx" SG_ 1990 TesterPhysicalReqSODR 1;
BA_ "U_U611_U625_MY20_Hev_Rx" SG_ 1990 TesterPhysicalReqSODR 1;
BA_ "U_U611_U625_MY20_Gas_Rx" SG_ 1990 TesterPhysicalReqSODR 1;
BA_ "U_C519_MY18_5_Gas_Rx" SG_ 1990 TesterPhysicalReqSODR 1;
BA_ "U_C519_MY18_5_Diesel_Rx" SG_ 1990 TesterPhysicalReqSODR 1;
BA_ "U_B515_MCA_MY17_Gas_Rx" SG_ 1990 TesterPhysicalReqSODR 1;
BA_ "U_B515_MCA_MY17_Diesel_Rx" SG_ 1990 TesterPhysicalReqSODR 1;
BA_ "U_B479_MY17_Diesel_Rx" SG_ 1990 TesterPhysicalReqSODR 1;
BA_ "U_B479_MY17_Gas_Rx" SG_ 1990 TesterPhysicalReqSODR 1;
BA_ "U_B562LC_MY15_Gas_Rx" SG_ 1990 TesterPhysicalReqSODR 1;
BA_ "GenSigSendType" SG_ 1990 TesterPhysicalReqSODR 3;
BA_ "U_CX727_MY2021_Tx" SG_ 1996 TesterPhysicalResSODL 1;
BA_ "U_CX430_MY2021_Tx" SG_ 1996 TesterPhysicalResSODL 1;
BA_ "U_U611_U625_MY20_Phev_Tx" SG_ 1996 TesterPhysicalResSODL 1;
BA_ "U_CX482_CX483_MY20_Tx" SG_ 1996 TesterPhysicalResSODL 1;
BA_ "U_U611_U625_MY20_Hev_Tx" SG_ 1996 TesterPhysicalResSODL 1;
BA_ "U_U611_U625_MY20_Gas_Tx" SG_ 1996 TesterPhysicalResSODL 1;
BA_ "U_C519_MY18_5_Gas_Tx" SG_ 1996 TesterPhysicalResSODL 1;
BA_ "U_C519_MY18_5_Diesel_Tx" SG_ 1996 TesterPhysicalResSODL 1;
BA_ "U_B515_MCA_MY17_Gas_Tx" SG_ 1996 TesterPhysicalResSODL 1;
BA_ "U_B515_MCA_MY17_Diesel_Tx" SG_ 1996 TesterPhysicalResSODL 1;
BA_ "U_B479_MY17_Diesel_Tx" SG_ 1996 TesterPhysicalResSODL 1;
BA_ "U_B479_MY17_Gas_Tx" SG_ 1996 TesterPhysicalResSODL 1;
BA_ "GenSigSendType" SG_ 1996 TesterPhysicalResSODL 3;
BA_ "U_CX727_MY2021_Rx" SG_ 1988 TesterPhysicalReqSODL 1;
BA_ "U_CX430_MY2021_Rx" SG_ 1988 TesterPhysicalReqSODL 1;
BA_ "U_U611_U625_MY20_Phev_Rx" SG_ 1988 TesterPhysicalReqSODL 1;
BA_ "U_CX482_CX483_MY20_Rx" SG_ 1988 TesterPhysicalReqSODL 1;
BA_ "U_U611_U625_MY20_Hev_Rx" SG_ 1988 TesterPhysicalReqSODL 1;
BA_ "U_U611_U625_MY20_Gas_Rx" SG_ 1988 TesterPhysicalReqSODL 1;
BA_ "U_C519_MY18_5_Gas_Rx" SG_ 1988 TesterPhysicalReqSODL 1;
BA_ "U_C519_MY18_5_Diesel_Rx" SG_ 1988 TesterPhysicalReqSODL 1;
BA_ "U_B515_MCA_MY17_Gas_Rx" SG_ 1988 TesterPhysicalReqSODL 1;
BA_ "U_B515_MCA_MY17_Diesel_Rx" SG_ 1988 TesterPhysicalReqSODL 1;
BA_ "U_B479_MY17_Diesel_Rx" SG_ 1988 TesterPhysicalReqSODL 1;
BA_ "U_B479_MY17_Gas_Rx" SG_ 1988 TesterPhysicalReqSODL 1;
BA_ "GenSigSendType" SG_ 1988 TesterPhysicalReqSODL 3;
BA_ "U_CX482_CX483_MY20_Tx" SG_ 2027 TesterPhysicalResAHCM 1;
BA_ "U_C519_MY18_5_Gas_Tx" SG_ 2027 TesterPhysicalResAHCM 1;
BA_ "U_C519_MY18_5_Diesel_Tx" SG_ 2027 TesterPhysicalResAHCM 1;
BA_ "GenSigSendType" SG_ 2027 TesterPhysicalResAHCM 3;
BA_ "U_U611_U625_MY20_Phev_Tx" SG_ 1496 SCMB_GWOnBoardTester 1;
BA_ "U_CX482_CX483_MY20_Tx" SG_ 1496 SCMB_GWOnBoardTester 1;
BA_ "U_U611_U625_MY20_Hev_Tx" SG_ 1496 SCMB_GWOnBoardTester 1;
BA_ "U_U611_U625_MY20_Gas_Tx" SG_ 1496 SCMB_GWOnBoardTester 1;
BA_ "GenSigStartValue" SG_ 1496 SCMB_GWOnBoardTester 255;
BA_ "ContentDependant" SG_ 1496 SCMB_GWOnBoardTester 1;
BA_ "GenSigStartValueInteger" SG_ 1496 SCMB_GWOnBoardTester 255;
BA_ "U_U611_U625_MY20_Phev_Tx" SG_ 1496 SCMB_GWNMProxy 1;
BA_ "U_CX482_CX483_MY20_Tx" SG_ 1496 SCMB_GWNMProxy 1;
BA_ "U_U611_U625_MY20_Hev_Tx" SG_ 1496 SCMB_GWNMProxy 1;
BA_ "U_U611_U625_MY20_Gas_Tx" SG_ 1496 SCMB_GWNMProxy 1;
BA_ "GenSigStartValue" SG_ 1496 SCMB_GWNMProxy 255;
BA_ "ContentDependant" SG_ 1496 SCMB_GWNMProxy 1;
BA_ "GenSigStartValueInteger" SG_ 1496 SCMB_GWNMProxy 255;
BA_ "U_U611_U625_MY20_Phev_Tx" SG_ 1496 SCMB_AutoSarNMReserved4 1;
BA_ "U_CX482_CX483_MY20_Tx" SG_ 1496 SCMB_AutoSarNMReserved4 1;
BA_ "U_U611_U625_MY20_Hev_Tx" SG_ 1496 SCMB_AutoSarNMReserved4 1;
BA_ "U_U611_U625_MY20_Gas_Tx" SG_ 1496 SCMB_AutoSarNMReserved4 1;
BA_ "GenSigStartValue" SG_ 1496 SCMB_AutoSarNMReserved4 255;
BA_ "ContentDependant" SG_ 1496 SCMB_AutoSarNMReserved4 1;
BA_ "GenSigStartValueInteger" SG_ 1496 SCMB_AutoSarNMReserved4 255;
BA_ "U_U611_U625_MY20_Phev_Tx" SG_ 1496 SCMB_AutoSarNMReserved3 1;
BA_ "U_CX482_CX483_MY20_Tx" SG_ 1496 SCMB_AutoSarNMReserved3 1;
BA_ "U_U611_U625_MY20_Hev_Tx" SG_ 1496 SCMB_AutoSarNMReserved3 1;
BA_ "U_U611_U625_MY20_Gas_Tx" SG_ 1496 SCMB_AutoSarNMReserved3 1;
BA_ "GenSigStartValue" SG_ 1496 SCMB_AutoSarNMReserved3 255;
BA_ "ContentDependant" SG_ 1496 SCMB_AutoSarNMReserved3 1;
BA_ "GenSigStartValueInteger" SG_ 1496 SCMB_AutoSarNMReserved3 255;
BA_ "U_U611_U625_MY20_Phev_Tx" SG_ 1496 SCMB_AutoSarNMReserved2 1;
BA_ "U_CX482_CX483_MY20_Tx" SG_ 1496 SCMB_AutoSarNMReserved2 1;
BA_ "U_U611_U625_MY20_Hev_Tx" SG_ 1496 SCMB_AutoSarNMReserved2 1;
BA_ "U_U611_U625_MY20_Gas_Tx" SG_ 1496 SCMB_AutoSarNMReserved2 1;
BA_ "GenSigStartValue" SG_ 1496 SCMB_AutoSarNMReserved2 255;
BA_ "ContentDependant" SG_ 1496 SCMB_AutoSarNMReserved2 1;
BA_ "GenSigStartValueInteger" SG_ 1496 SCMB_AutoSarNMReserved2 255;
BA_ "U_U611_U625_MY20_Phev_Tx" SG_ 1496 SCMB_AutoSarNMReserved1 1;
BA_ "U_CX482_CX483_MY20_Tx" SG_ 1496 SCMB_AutoSarNMReserved1 1;
BA_ "U_U611_U625_MY20_Hev_Tx" SG_ 1496 SCMB_AutoSarNMReserved1 1;
BA_ "U_U611_U625_MY20_Gas_Tx" SG_ 1496 SCMB_AutoSarNMReserved1 1;
BA_ "GenSigStartValue" SG_ 1496 SCMB_AutoSarNMReserved1 255;
BA_ "ContentDependant" SG_ 1496 SCMB_AutoSarNMReserved1 1;
BA_ "GenSigStartValueInteger" SG_ 1496 SCMB_AutoSarNMReserved1 255;
BA_ "U_U611_U625_MY20_Phev_Tx" SG_ 1496 SCMB_AutoSarNMNodeId 1;
BA_ "U_CX482_CX483_MY20_Tx" SG_ 1496 SCMB_AutoSarNMNodeId 1;
BA_ "U_U611_U625_MY20_Hev_Tx" SG_ 1496 SCMB_AutoSarNMNodeId 1;
BA_ "U_U611_U625_MY20_Gas_Tx" SG_ 1496 SCMB_AutoSarNMNodeId 1;
BA_ "GenSigStartValue" SG_ 1496 SCMB_AutoSarNMNodeId 216;
BA_ "ContentDependant" SG_ 1496 SCMB_AutoSarNMNodeId 1;
BA_ "GenSigStartValueInteger" SG_ 1496 SCMB_AutoSarNMNodeId 216;
BA_ "U_U611_U625_MY20_Phev_Tx" SG_ 1496 SCMB_AutoSarNMControl 1;
BA_ "U_CX482_CX483_MY20_Tx" SG_ 1496 SCMB_AutoSarNMControl 1;
BA_ "U_U611_U625_MY20_Hev_Tx" SG_ 1496 SCMB_AutoSarNMControl 1;
BA_ "U_U611_U625_MY20_Gas_Tx" SG_ 1496 SCMB_AutoSarNMControl 1;
BA_ "ContentDependant" SG_ 1496 SCMB_AutoSarNMControl 1;
BA_ "GenSigSendType" SG_ 847 FldngSeatPwOffOk_B_Stat 3;
BA_ "WakeupSignal" SG_ 847 FldngSeatPwOffOk_B_Stat 1;
BA_ "U_CX482_CX483_MY20_Rx" SG_ 2019 TesterPhysicalReqAHCM 1;
BA_ "U_C519_MY18_5_Gas_Rx" SG_ 2019 TesterPhysicalReqAHCM 1;
BA_ "U_C519_MY18_5_Diesel_Rx" SG_ 2019 TesterPhysicalReqAHCM 1;
BA_ "GenSigSendType" SG_ 2019 TesterPhysicalReqAHCM 3;
BA_ "U_P702_MY2021_Tx" SG_ 862 HvacBlwrFront_D_Stat 1;
BA_ "U_CX727_MY2021_Tx" SG_ 862 HvacBlwrFront_D_Stat 1;
BA_ "U_CX430_MY2021_Tx" SG_ 862 HvacBlwrFront_D_Stat 1;
BA_ "U_U611_U625_MY20_Phev_Tx" SG_ 862 HvacBlwrFront_D_Stat 1;
BA_ "U_B562_MY18_Diesel_Tx" SG_ 862 HvacBlwrFront_D_Stat 1;
BA_ "U_CX482_CX483_MY20_Tx" SG_ 862 HvacBlwrFront_D_Stat 1;
BA_ "U_U611_U625_MY20_Hev_Tx" SG_ 862 HvacBlwrFront_D_Stat 1;
BA_ "U_U611_U625_MY20_Gas_Tx" SG_ 862 HvacBlwrFront_D_Stat 1;
BA_ "U_B500_MY18_Diesel_Tx" SG_ 862 HvacBlwrFront_D_Stat 1;
BA_ "U_B500_MY18_Gas_Tx" SG_ 862 HvacBlwrFront_D_Stat 1;
BA_ "U_C490_MY18_Tx" SG_ 862 HvacBlwrFront_D_Stat 1;
BA_ "U_B562_MY18_Gas_Tx" SG_ 862 HvacBlwrFront_D_Stat 1;
BA_ "U_C519_MY18_5_Gas_Tx" SG_ 862 HvacBlwrFront_D_Stat 1;
BA_ "U_C519_MY18_5_Diesel_Tx" SG_ 862 HvacBlwrFront_D_Stat 1;
BA_ "U_B515_MCA_MY17_Gas_Tx" SG_ 862 HvacBlwrFront_D_Stat 1;
BA_ "U_B515_MCA_MY17_Diesel_Tx" SG_ 862 HvacBlwrFront_D_Stat 1;
BA_ "U_B479_MY17_Diesel_Tx" SG_ 862 HvacBlwrFront_D_Stat 1;
BA_ "U_B479_MY17_Gas_Tx" SG_ 862 HvacBlwrFront_D_Stat 1;
BA_ "U_P702_MY2021_Rx" SG_ 862 HvacBlwrFront_D_Stat 1;
BA_ "U_CX727_MY2021_Rx" SG_ 862 HvacBlwrFront_D_Stat 1;
BA_ "U_U611_U625_MY20_Phev_Rx" SG_ 862 HvacBlwrFront_D_Stat 1;
BA_ "U_CX482_CX483_MY20_Rx" SG_ 862 HvacBlwrFront_D_Stat 1;
BA_ "U_U611_U625_MY20_Hev_Rx" SG_ 862 HvacBlwrFront_D_Stat 1;
BA_ "U_U611_U625_MY20_Gas_Rx" SG_ 862 HvacBlwrFront_D_Stat 1;
BA_ "U_C519_MY18_5_Diesel_Rx" SG_ 862 HvacBlwrFront_D_Stat 1;
BA_ "GenSigSendType" SG_ 862 HvacBlwrFront_D_Stat 3;
BA_ "U_CX727_MY2021_Tx" SG_ 862 HvacRemoteStrt_N_Rq 1;
BA_ "U_CX430_MY2021_Tx" SG_ 862 HvacRemoteStrt_N_Rq 1;
BA_ "U_U611_U625_MY20_Phev_Tx" SG_ 862 HvacRemoteStrt_N_Rq 1;
BA_ "U_CX482_CX483_MY20_Tx" SG_ 862 HvacRemoteStrt_N_Rq 1;
BA_ "U_U611_U625_MY20_Hev_Tx" SG_ 862 HvacRemoteStrt_N_Rq 1;
BA_ "U_U611_U625_MY20_Gas_Tx" SG_ 862 HvacRemoteStrt_N_Rq 1;
BA_ "U_B500_MY18_Diesel_Tx" SG_ 862 HvacRemoteStrt_N_Rq 1;
BA_ "U_B500_MY18_Gas_Tx" SG_ 862 HvacRemoteStrt_N_Rq 1;
BA_ "U_C519_MY18_5_Gas_Tx" SG_ 862 HvacRemoteStrt_N_Rq 1;
BA_ "U_C519_MY18_5_Diesel_Tx" SG_ 862 HvacRemoteStrt_N_Rq 1;
BA_ "U_B515_MCA_MY17_Gas_Tx" SG_ 862 HvacRemoteStrt_N_Rq 1;
BA_ "U_B515_MCA_MY17_Diesel_Tx" SG_ 862 HvacRemoteStrt_N_Rq 1;
BA_ "U_B479_MY17_Diesel_Tx" SG_ 862 HvacRemoteStrt_N_Rq 1;
BA_ "U_B479_MY17_Gas_Tx" SG_ 862 HvacRemoteStrt_N_Rq 1;
BA_ "GenSigSendType" SG_ 862 HvacRemoteStrt_N_Rq 3;
BA_ "U_P702_MY2021_Tx" SG_ 862 ClimtThrmlLoad_No_Actl 1;
BA_ "U_CX727_MY2021_Tx" SG_ 862 ClimtThrmlLoad_No_Actl 1;
BA_ "U_CX430_MY2021_Tx" SG_ 862 ClimtThrmlLoad_No_Actl 1;
BA_ "U_U611_U625_MY20_Phev_Tx" SG_ 862 ClimtThrmlLoad_No_Actl 1;
BA_ "U_B562_MY18_Diesel_Tx" SG_ 862 ClimtThrmlLoad_No_Actl 1;
BA_ "U_CX482_CX483_MY20_Tx" SG_ 862 ClimtThrmlLoad_No_Actl 1;
BA_ "U_U611_U625_MY20_Hev_Tx" SG_ 862 ClimtThrmlLoad_No_Actl 1;
BA_ "U_U611_U625_MY20_Gas_Tx" SG_ 862 ClimtThrmlLoad_No_Actl 1;
BA_ "U_B500_MY18_Diesel_Tx" SG_ 862 ClimtThrmlLoad_No_Actl 1;
BA_ "U_B500_MY18_Gas_Tx" SG_ 862 ClimtThrmlLoad_No_Actl 1;
BA_ "U_B562_MY18_Gas_Tx" SG_ 862 ClimtThrmlLoad_No_Actl 1;
BA_ "U_C519_MY18_5_Gas_Tx" SG_ 862 ClimtThrmlLoad_No_Actl 1;
BA_ "U_C519_MY18_5_Diesel_Tx" SG_ 862 ClimtThrmlLoad_No_Actl 1;
BA_ "U_B515_MCA_MY17_Gas_Tx" SG_ 862 ClimtThrmlLoad_No_Actl 1;
BA_ "U_B515_MCA_MY17_Diesel_Tx" SG_ 862 ClimtThrmlLoad_No_Actl 1;
BA_ "U_B479_MY17_Diesel_Tx" SG_ 862 ClimtThrmlLoad_No_Actl 1;
BA_ "U_B479_MY17_Gas_Tx" SG_ 862 ClimtThrmlLoad_No_Actl 1;
BA_ "GenSigSendType" SG_ 862 ClimtThrmlLoad_No_Actl 3;
BA_ "GenSigStartValue" SG_ 862 ClimtThrmlLoad_No_Actl 255;
BA_ "GenSigStartValueInteger" SG_ 862 ClimtThrmlLoad_No_Actl 255;
BA_ "U_P702_MY2021_Tx" SG_ 862 HvacRec_Pc_Est 1;
BA_ "U_CX727_MY2021_Tx" SG_ 862 HvacRec_Pc_Est 1;
BA_ "U_U611_U625_MY20_Phev_Tx" SG_ 862 HvacRec_Pc_Est 1;
BA_ "U_B562_MY18_Diesel_Tx" SG_ 862 HvacRec_Pc_Est 1;
BA_ "U_CX482_CX483_MY20_Tx" SG_ 862 HvacRec_Pc_Est 1;
BA_ "U_U611_U625_MY20_Hev_Tx" SG_ 862 HvacRec_Pc_Est 1;
BA_ "U_U611_U625_MY20_Gas_Tx" SG_ 862 HvacRec_Pc_Est 1;
BA_ "U_B500_MY18_Diesel_Tx" SG_ 862 HvacRec_Pc_Est 1;
BA_ "U_B500_MY18_Gas_Tx" SG_ 862 HvacRec_Pc_Est 1;
BA_ "U_C490_MY18_Tx" SG_ 862 HvacRec_Pc_Est 1;
BA_ "U_B562_MY18_Gas_Tx" SG_ 862 HvacRec_Pc_Est 1;
BA_ "U_C519_MY18_5_Gas_Tx" SG_ 862 HvacRec_Pc_Est 1;
BA_ "U_C519_MY18_5_Diesel_Tx" SG_ 862 HvacRec_Pc_Est 1;
BA_ "U_B515_MCA_MY17_Gas_Tx" SG_ 862 HvacRec_Pc_Est 1;
BA_ "U_B515_MCA_MY17_Diesel_Tx" SG_ 862 HvacRec_Pc_Est 1;
BA_ "U_B479_MY17_Diesel_Tx" SG_ 862 HvacRec_Pc_Est 1;
BA_ "U_B479_MY17_Gas_Tx" SG_ 862 HvacRec_Pc_Est 1;
BA_ "GenSigSendType" SG_ 862 HvacRec_Pc_Est 3;
BA_ "U_P702_MY2021_Tx" SG_ 862 HvacAir_Flw_Est 1;
BA_ "U_CX727_MY2021_Tx" SG_ 862 HvacAir_Flw_Est 1;
BA_ "U_CX430_MY2021_Tx" SG_ 862 HvacAir_Flw_Est 1;
BA_ "U_U611_U625_MY20_Phev_Tx" SG_ 862 HvacAir_Flw_Est 1;
BA_ "U_B562_MY18_Diesel_Tx" SG_ 862 HvacAir_Flw_Est 1;
BA_ "U_CX482_CX483_MY20_Tx" SG_ 862 HvacAir_Flw_Est 1;
BA_ "U_U611_U625_MY20_Hev_Tx" SG_ 862 HvacAir_Flw_Est 1;
BA_ "U_U611_U625_MY20_Gas_Tx" SG_ 862 HvacAir_Flw_Est 1;
BA_ "U_B500_MY18_Diesel_Tx" SG_ 862 HvacAir_Flw_Est 1;
BA_ "U_B500_MY18_Gas_Tx" SG_ 862 HvacAir_Flw_Est 1;
BA_ "U_B562_MY18_Gas_Tx" SG_ 862 HvacAir_Flw_Est 1;
BA_ "U_C519_MY18_5_Gas_Tx" SG_ 862 HvacAir_Flw_Est 1;
BA_ "U_C519_MY18_5_Diesel_Tx" SG_ 862 HvacAir_Flw_Est 1;
BA_ "U_B515_MCA_MY17_Gas_Tx" SG_ 862 HvacAir_Flw_Est 1;
BA_ "U_B515_MCA_MY17_Diesel_Tx" SG_ 862 HvacAir_Flw_Est 1;
BA_ "U_B479_MY17_Diesel_Tx" SG_ 862 HvacAir_Flw_Est 1;
BA_ "U_B479_MY17_Gas_Tx" SG_ 862 HvacAir_Flw_Est 1;
BA_ "GenSigSendType" SG_ 862 HvacAir_Flw_Est 3;
BA_ "U_CX727_MY2021_Tx" SG_ 862 CamraDefog_B_Actl 1;
BA_ "U_CX430_MY2021_Tx" SG_ 862 CamraDefog_B_Actl 1;
BA_ "U_U611_U625_MY20_Phev_Tx" SG_ 862 CamraDefog_B_Actl 1;
BA_ "U_CX482_CX483_MY20_Tx" SG_ 862 CamraDefog_B_Actl 1;
BA_ "U_U611_U625_MY20_Hev_Tx" SG_ 862 CamraDefog_B_Actl 1;
BA_ "U_U611_U625_MY20_Gas_Tx" SG_ 862 CamraDefog_B_Actl 1;
BA_ "U_B500_MY18_Diesel_Tx" SG_ 862 CamraDefog_B_Actl 1;
BA_ "U_B500_MY18_Gas_Tx" SG_ 862 CamraDefog_B_Actl 1;
BA_ "U_C519_MY18_5_Gas_Tx" SG_ 862 CamraDefog_B_Actl 1;
BA_ "U_C519_MY18_5_Diesel_Tx" SG_ 862 CamraDefog_B_Actl 1;
BA_ "U_B515_MCA_MY17_Gas_Tx" SG_ 862 CamraDefog_B_Actl 1;
BA_ "U_B515_MCA_MY17_Diesel_Tx" SG_ 862 CamraDefog_B_Actl 1;
BA_ "U_B479_MY17_Diesel_Tx" SG_ 862 CamraDefog_B_Actl 1;
BA_ "U_B479_MY17_Gas_Tx" SG_ 862 CamraDefog_B_Actl 1;
BA_ "GenSigSendType" SG_ 862 CamraDefog_B_Actl 3;
BA_ "U_P702_MY2021_Tx" SG_ 862 CabnAmb_Te_Actl 1;
BA_ "U_CX727_MY2021_Tx" SG_ 862 CabnAmb_Te_Actl 1;
BA_ "U_CX430_MY2021_Tx" SG_ 862 CabnAmb_Te_Actl 1;
BA_ "U_U611_U625_MY20_Phev_Tx" SG_ 862 CabnAmb_Te_Actl 1;
BA_ "U_B562_MY18_Diesel_Tx" SG_ 862 CabnAmb_Te_Actl 1;
BA_ "U_CX482_CX483_MY20_Tx" SG_ 862 CabnAmb_Te_Actl 1;
BA_ "U_U611_U625_MY20_Hev_Tx" SG_ 862 CabnAmb_Te_Actl 1;
BA_ "U_U611_U625_MY20_Gas_Tx" SG_ 862 CabnAmb_Te_Actl 1;
BA_ "U_B500_MY18_Diesel_Tx" SG_ 862 CabnAmb_Te_Actl 1;
BA_ "U_B500_MY18_Gas_Tx" SG_ 862 CabnAmb_Te_Actl 1;
BA_ "U_C490_MY18_Tx" SG_ 862 CabnAmb_Te_Actl 1;
BA_ "U_B562_MY18_Gas_Tx" SG_ 862 CabnAmb_Te_Actl 1;
BA_ "U_C519_MY18_5_Gas_Tx" SG_ 862 CabnAmb_Te_Actl 1;
BA_ "U_C519_MY18_5_Diesel_Tx" SG_ 862 CabnAmb_Te_Actl 1;
BA_ "U_B515_MCA_MY17_Gas_Tx" SG_ 862 CabnAmb_Te_Actl 1;
BA_ "U_B515_MCA_MY17_Diesel_Tx" SG_ 862 CabnAmb_Te_Actl 1;
BA_ "U_B479_MY17_Diesel_Tx" SG_ 862 CabnAmb_Te_Actl 1;
BA_ "U_B479_MY17_Gas_Tx" SG_ 862 CabnAmb_Te_Actl 1;
BA_ "U_P702_MY2021_Rx" SG_ 862 CabnAmb_Te_Actl 1;
BA_ "U_CX727_MY2021_Rx" SG_ 862 CabnAmb_Te_Actl 1;
BA_ "U_U611_U625_MY20_Phev_Rx" SG_ 862 CabnAmb_Te_Actl 1;
BA_ "U_U611_U625_MY20_Hev_Rx" SG_ 862 CabnAmb_Te_Actl 1;
BA_ "U_U611_U625_MY20_Gas_Rx" SG_ 862 CabnAmb_Te_Actl 1;
BA_ "U_CX482_CX483_MY20_Rx" SG_ 862 CabnAmb_Te_Actl 1;
BA_ "U_C519_MY18_5_Gas_Rx" SG_ 862 CabnAmb_Te_Actl 1;
BA_ "U_C519_MY18_5_Diesel_Rx" SG_ 862 CabnAmb_Te_Actl 1;
BA_ "GenSigSendType" SG_ 862 CabnAmb_Te_Actl 3;
BA_ "GenSigStartValueInteger" SG_ 862 CabnAmb_Te_Actl 114;
BA_ "U_CX727_MY2021_Tx" SG_ 862 AutoStpHvacDelta_I_Est 1;
BA_ "U_CX430_MY2021_Tx" SG_ 862 AutoStpHvacDelta_I_Est 1;
BA_ "U_U611_U625_MY20_Phev_Tx" SG_ 862 AutoStpHvacDelta_I_Est 1;
BA_ "U_B562_MY18_Diesel_Tx" SG_ 862 AutoStpHvacDelta_I_Est 1;
BA_ "U_CX482_CX483_MY20_Tx" SG_ 862 AutoStpHvacDelta_I_Est 1;
BA_ "U_U611_U625_MY20_Hev_Tx" SG_ 862 AutoStpHvacDelta_I_Est 1;
BA_ "U_U611_U625_MY20_Gas_Tx" SG_ 862 AutoStpHvacDelta_I_Est 1;
BA_ "U_B500_MY18_Diesel_Tx" SG_ 862 AutoStpHvacDelta_I_Est 1;
BA_ "U_B500_MY18_Gas_Tx" SG_ 862 AutoStpHvacDelta_I_Est 1;
BA_ "U_C490_MY18_Tx" SG_ 862 AutoStpHvacDelta_I_Est 1;
BA_ "U_B562_MY18_Gas_Tx" SG_ 862 AutoStpHvacDelta_I_Est 1;
BA_ "U_C519_MY18_5_Gas_Tx" SG_ 862 AutoStpHvacDelta_I_Est 1;
BA_ "U_C519_MY18_5_Diesel_Tx" SG_ 862 AutoStpHvacDelta_I_Est 1;
BA_ "U_B515_MCA_MY17_Gas_Tx" SG_ 862 AutoStpHvacDelta_I_Est 1;
BA_ "U_B515_MCA_MY17_Diesel_Tx" SG_ 862 AutoStpHvacDelta_I_Est 1;
BA_ "U_B479_MY17_Diesel_Tx" SG_ 862 AutoStpHvacDelta_I_Est 1;
BA_ "U_B479_MY17_Gas_Tx" SG_ 862 AutoStpHvacDelta_I_Est 1;
BA_ "GenSigSendType" SG_ 862 AutoStpHvacDelta_I_Est 3;
BA_ "GenSigStartValueInteger" SG_ 862 AutoStpHvacDelta_I_Est 192;
BA_ "U_P702_MY2021_Tx" SG_ 828 RearPassWindowPos 1;
BA_ "U_CX430_MY2021_Tx" SG_ 828 RearPassWindowPos 1;
BA_ "U_U611_U625_MY20_Phev_Tx" SG_ 828 RearPassWindowPos 1;
BA_ "U_CX482_CX483_MY20_Tx" SG_ 828 RearPassWindowPos 1;
BA_ "U_U611_U625_MY20_Hev_Tx" SG_ 828 RearPassWindowPos 1;
BA_ "U_U611_U625_MY20_Gas_Tx" SG_ 828 RearPassWindowPos 1;
BA_ "U_C490_MY18_Tx" SG_ 828 RearPassWindowPos 1;
BA_ "U_C519_MY18_5_Gas_Tx" SG_ 828 RearPassWindowPos 1;
BA_ "U_C519_MY18_5_Diesel_Tx" SG_ 828 RearPassWindowPos 1;
BA_ "U_B515_MCA_MY17_Gas_Tx" SG_ 828 RearPassWindowPos 1;
BA_ "U_B515_MCA_MY17_Diesel_Tx" SG_ 828 RearPassWindowPos 1;
BA_ "U_B479_MY17_Diesel_Tx" SG_ 828 RearPassWindowPos 1;
BA_ "U_B479_MY17_Gas_Tx" SG_ 828 RearPassWindowPos 1;
BA_ "U_P702_MY2021_Rx" SG_ 828 RearPassWindowPos 1;
BA_ "U_CX727_MY2021_Rx" SG_ 828 RearPassWindowPos 1;
BA_ "U_CX430_MY2021_Rx" SG_ 828 RearPassWindowPos 1;
BA_ "U_U611_U625_MY20_Phev_Rx" SG_ 828 RearPassWindowPos 1;
BA_ "U_CX482_CX483_MY20_Rx" SG_ 828 RearPassWindowPos 1;
BA_ "U_U611_U625_MY20_Hev_Rx" SG_ 828 RearPassWindowPos 1;
BA_ "U_U611_U625_MY20_Gas_Rx" SG_ 828 RearPassWindowPos 1;
BA_ "U_B500_MY18_Diesel_Rx" SG_ 828 RearPassWindowPos 1;
BA_ "U_B500_MY18_Gas_Rx" SG_ 828 RearPassWindowPos 1;
BA_ "U_C490_MY18_Rx" SG_ 828 RearPassWindowPos 1;
BA_ "U_C519_MY18_5_Gas_Rx" SG_ 828 RearPassWindowPos 1;
BA_ "U_C519_MY18_5_Diesel_Rx" SG_ 828 RearPassWindowPos 1;
BA_ "U_B515_MCA_MY17_Gas_Rx" SG_ 828 RearPassWindowPos 1;
BA_ "U_B515_MCA_MY17_Diesel_Rx" SG_ 828 RearPassWindowPos 1;
BA_ "U_B479_MY17_Diesel_Rx" SG_ 828 RearPassWindowPos 1;
BA_ "U_B479_MY17_Gas_Rx" SG_ 828 RearPassWindowPos 1;
BA_ "GenSigSendType" SG_ 828 RearPassWindowPos 3;
BA_ "WakeupSignal" SG_ 828 RearPassWindowPos 1;
BA_ "U_P702_MY2021_Tx" SG_ 828 PassWindowPosition 1;
BA_ "U_CX430_MY2021_Tx" SG_ 828 PassWindowPosition 1;
BA_ "U_U611_U625_MY20_Phev_Tx" SG_ 828 PassWindowPosition 1;
BA_ "U_CX482_CX483_MY20_Tx" SG_ 828 PassWindowPosition 1;
BA_ "U_U611_U625_MY20_Hev_Tx" SG_ 828 PassWindowPosition 1;
BA_ "U_U611_U625_MY20_Gas_Tx" SG_ 828 PassWindowPosition 1;
BA_ "U_C490_MY18_Tx" SG_ 828 PassWindowPosition 1;
BA_ "U_C519_MY18_5_Gas_Tx" SG_ 828 PassWindowPosition 1;
BA_ "U_C519_MY18_5_Diesel_Tx" SG_ 828 PassWindowPosition 1;
BA_ "U_B515_MCA_MY17_Gas_Tx" SG_ 828 PassWindowPosition 1;
BA_ "U_B515_MCA_MY17_Diesel_Tx" SG_ 828 PassWindowPosition 1;
BA_ "U_B479_MY17_Diesel_Tx" SG_ 828 PassWindowPosition 1;
BA_ "U_B479_MY17_Gas_Tx" SG_ 828 PassWindowPosition 1;
BA_ "U_P702_MY2021_Rx" SG_ 828 PassWindowPosition 1;
BA_ "U_CX727_MY2021_Rx" SG_ 828 PassWindowPosition 1;
BA_ "U_CX430_MY2021_Rx" SG_ 828 PassWindowPosition 1;
BA_ "U_U611_U625_MY20_Phev_Rx" SG_ 828 PassWindowPosition 1;
BA_ "U_CX482_CX483_MY20_Rx" SG_ 828 PassWindowPosition 1;
BA_ "U_U611_U625_MY20_Hev_Rx" SG_ 828 PassWindowPosition 1;
BA_ "U_U611_U625_MY20_Gas_Rx" SG_ 828 PassWindowPosition 1;
BA_ "U_B500_MY18_Diesel_Rx" SG_ 828 PassWindowPosition 1;
BA_ "U_B500_MY18_Gas_Rx" SG_ 828 PassWindowPosition 1;
BA_ "U_C490_MY18_Rx" SG_ 828 PassWindowPosition 1;
BA_ "U_C519_MY18_5_Gas_Rx" SG_ 828 PassWindowPosition 1;
BA_ "U_C519_MY18_5_Diesel_Rx" SG_ 828 PassWindowPosition 1;
BA_ "U_B515_MCA_MY17_Gas_Rx" SG_ 828 PassWindowPosition 1;
BA_ "U_B515_MCA_MY17_Diesel_Rx" SG_ 828 PassWindowPosition 1;
BA_ "U_B479_MY17_Diesel_Rx" SG_ 828 PassWindowPosition 1;
BA_ "U_B479_MY17_Gas_Rx" SG_ 828 PassWindowPosition 1;
BA_ "GenSigSendType" SG_ 828 PassWindowPosition 3;
BA_ "WakeupSignal" SG_ 828 PassWindowPosition 1;
BA_ "U_CX727_MY2021_Rx" SG_ 1909 TesterPhysicalReqRGTM 1;
BA_ "U_U611_U625_MY20_Phev_Rx" SG_ 1909 TesterPhysicalReqRGTM 1;
BA_ "U_CX482_CX483_MY20_Rx" SG_ 1909 TesterPhysicalReqRGTM 1;
BA_ "U_U611_U625_MY20_Hev_Rx" SG_ 1909 TesterPhysicalReqRGTM 1;
BA_ "U_U611_U625_MY20_Gas_Rx" SG_ 1909 TesterPhysicalReqRGTM 1;
BA_ "U_C519_MY18_5_Gas_Rx" SG_ 1909 TesterPhysicalReqRGTM 1;
BA_ "U_C519_MY18_5_Diesel_Rx" SG_ 1909 TesterPhysicalReqRGTM 1;
BA_ "GenSigSendType" SG_ 1909 TesterPhysicalReqRGTM 3;
BA_ "U_CX727_MY2021_Tx" SG_ 1917 TesterPhysicalResRGTM 1;
BA_ "U_U611_U625_MY20_Phev_Tx" SG_ 1917 TesterPhysicalResRGTM 1;
BA_ "U_CX482_CX483_MY20_Tx" SG_ 1917 TesterPhysicalResRGTM 1;
BA_ "U_U611_U625_MY20_Hev_Tx" SG_ 1917 TesterPhysicalResRGTM 1;
BA_ "U_U611_U625_MY20_Gas_Tx" SG_ 1917 TesterPhysicalResRGTM 1;
BA_ "U_C519_MY18_5_Gas_Tx" SG_ 1917 TesterPhysicalResRGTM 1;
BA_ "U_C519_MY18_5_Diesel_Tx" SG_ 1917 TesterPhysicalResRGTM 1;
BA_ "GenSigSendType" SG_ 1917 TesterPhysicalResRGTM 3;
BA_ "U_P702_MY2021_Rx" SG_ 1860 TesterPhysicalReqDSM 1;
BA_ "U_CX727_MY2021_Rx" SG_ 1860 TesterPhysicalReqDSM 1;
BA_ "U_CX430_MY2021_Rx" SG_ 1860 TesterPhysicalReqDSM 1;
BA_ "U_U611_U625_MY20_Phev_Rx" SG_ 1860 TesterPhysicalReqDSM 1;
BA_ "U_CX482_CX483_MY20_Rx" SG_ 1860 TesterPhysicalReqDSM 1;
BA_ "U_U611_U625_MY20_Hev_Rx" SG_ 1860 TesterPhysicalReqDSM 1;
BA_ "U_U611_U625_MY20_Gas_Rx" SG_ 1860 TesterPhysicalReqDSM 1;
BA_ "U_C490_MY18_Rx" SG_ 1860 TesterPhysicalReqDSM 1;
BA_ "GenSigSendType" SG_ 1860 TesterPhysicalReqDSM 3;
BA_ "U_P702_MY2021_Tx" SG_ 1868 TesterPhysicalResDSM 1;
BA_ "U_CX727_MY2021_Tx" SG_ 1868 TesterPhysicalResDSM 1;
BA_ "U_CX430_MY2021_Tx" SG_ 1868 TesterPhysicalResDSM 1;
BA_ "U_U611_U625_MY20_Phev_Tx" SG_ 1868 TesterPhysicalResDSM 1;
BA_ "U_CX482_CX483_MY20_Tx" SG_ 1868 TesterPhysicalResDSM 1;
BA_ "U_U611_U625_MY20_Hev_Tx" SG_ 1868 TesterPhysicalResDSM 1;
BA_ "U_U611_U625_MY20_Gas_Tx" SG_ 1868 TesterPhysicalResDSM 1;
BA_ "U_C490_MY18_Tx" SG_ 1868 TesterPhysicalResDSM 1;
BA_ "GenSigSendType" SG_ 1868 TesterPhysicalResDSM 3;
BA_ "U_P702_MY2021_Tx" SG_ 1918 TesterPhysicalResSCME 1;
BA_ "U_U611_U625_MY20_Phev_Tx" SG_ 1918 TesterPhysicalResSCME 1;
BA_ "U_CX482_CX483_MY20_Tx" SG_ 1918 TesterPhysicalResSCME 1;
BA_ "U_U611_U625_MY20_Hev_Tx" SG_ 1918 TesterPhysicalResSCME 1;
BA_ "U_U611_U625_MY20_Gas_Tx" SG_ 1918 TesterPhysicalResSCME 1;
BA_ "GenSigSendType" SG_ 1918 TesterPhysicalResSCME 3;
BA_ "U_P702_MY2021_Rx" SG_ 1910 TesterPhysicalReqSCME 1;
BA_ "U_U611_U625_MY20_Phev_Rx" SG_ 1910 TesterPhysicalReqSCME 1;
BA_ "U_CX482_CX483_MY20_Rx" SG_ 1910 TesterPhysicalReqSCME 1;
BA_ "U_U611_U625_MY20_Hev_Rx" SG_ 1910 TesterPhysicalReqSCME 1;
BA_ "U_U611_U625_MY20_Gas_Rx" SG_ 1910 TesterPhysicalReqSCME 1;
BA_ "GenSigSendType" SG_ 1910 TesterPhysicalReqSCME 3;
BA_ "GenSigSendType" SG_ 1814 TesterPhysicalReqGWM_M1 3;
BA_ "GenSigSendType" SG_ 1822 TesterPhysicalResGWM_M1 3;
BA_ "U_P702_MY2021_Tx" SG_ 826 Memory_3_Sw_Stat 1;
BA_ "U_CX727_MY2021_Tx" SG_ 826 Memory_3_Sw_Stat 1;
BA_ "U_CX430_MY2021_Tx" SG_ 826 Memory_3_Sw_Stat 1;
BA_ "U_U611_U625_MY20_Phev_Tx" SG_ 826 Memory_3_Sw_Stat 1;
BA_ "U_CX482_CX483_MY20_Tx" SG_ 826 Memory_3_Sw_Stat 1;
BA_ "U_U611_U625_MY20_Hev_Tx" SG_ 826 Memory_3_Sw_Stat 1;
BA_ "U_U611_U625_MY20_Gas_Tx" SG_ 826 Memory_3_Sw_Stat 1;
BA_ "U_C490_MY18_Tx" SG_ 826 Memory_3_Sw_Stat 1;
BA_ "U_C519_MY18_5_Gas_Tx" SG_ 826 Memory_3_Sw_Stat 1;
BA_ "U_C519_MY18_5_Diesel_Tx" SG_ 826 Memory_3_Sw_Stat 1;
BA_ "U_B515_MCA_MY17_Gas_Tx" SG_ 826 Memory_3_Sw_Stat 1;
BA_ "U_B515_MCA_MY17_Diesel_Tx" SG_ 826 Memory_3_Sw_Stat 1;
BA_ "U_B479_MY17_Diesel_Tx" SG_ 826 Memory_3_Sw_Stat 1;
BA_ "U_B479_MY17_Gas_Tx" SG_ 826 Memory_3_Sw_Stat 1;
BA_ "U_P702_MY2021_Rx" SG_ 826 Memory_3_Sw_Stat 1;
BA_ "U_CX727_MY2021_Rx" SG_ 826 Memory_3_Sw_Stat 1;
BA_ "U_CX430_MY2021_Rx" SG_ 826 Memory_3_Sw_Stat 1;
BA_ "U_U611_U625_MY20_Phev_Rx" SG_ 826 Memory_3_Sw_Stat 1;
BA_ "U_CX482_CX483_MY20_Rx" SG_ 826 Memory_3_Sw_Stat 1;
BA_ "U_U611_U625_MY20_Hev_Rx" SG_ 826 Memory_3_Sw_Stat 1;
BA_ "U_U611_U625_MY20_Gas_Rx" SG_ 826 Memory_3_Sw_Stat 1;
BA_ "U_C490_MY18_Rx" SG_ 826 Memory_3_Sw_Stat 1;
BA_ "GenSigSendType" SG_ 826 Memory_3_Sw_Stat 3;
BA_ "WakeupSignal" SG_ 826 Memory_3_Sw_Stat 1;
BA_ "U_P702_MY2021_Tx" SG_ 826 Memory_2_Sw_Stat 1;
BA_ "U_CX727_MY2021_Tx" SG_ 826 Memory_2_Sw_Stat 1;
BA_ "U_CX430_MY2021_Tx" SG_ 826 Memory_2_Sw_Stat 1;
BA_ "U_U611_U625_MY20_Phev_Tx" SG_ 826 Memory_2_Sw_Stat 1;
BA_ "U_CX482_CX483_MY20_Tx" SG_ 826 Memory_2_Sw_Stat 1;
BA_ "U_U611_U625_MY20_Hev_Tx" SG_ 826 Memory_2_Sw_Stat 1;
BA_ "U_U611_U625_MY20_Gas_Tx" SG_ 826 Memory_2_Sw_Stat 1;
BA_ "U_C490_MY18_Tx" SG_ 826 Memory_2_Sw_Stat 1;
BA_ "U_C519_MY18_5_Gas_Tx" SG_ 826 Memory_2_Sw_Stat 1;
BA_ "U_C519_MY18_5_Diesel_Tx" SG_ 826 Memory_2_Sw_Stat 1;
BA_ "U_B515_MCA_MY17_Gas_Tx" SG_ 826 Memory_2_Sw_Stat 1;
BA_ "U_B515_MCA_MY17_Diesel_Tx" SG_ 826 Memory_2_Sw_Stat 1;
BA_ "U_B479_MY17_Diesel_Tx" SG_ 826 Memory_2_Sw_Stat 1;
BA_ "U_B479_MY17_Gas_Tx" SG_ 826 Memory_2_Sw_Stat 1;
BA_ "U_P702_MY2021_Rx" SG_ 826 Memory_2_Sw_Stat 1;
BA_ "U_CX727_MY2021_Rx" SG_ 826 Memory_2_Sw_Stat 1;
BA_ "U_CX430_MY2021_Rx" SG_ 826 Memory_2_Sw_Stat 1;
BA_ "U_U611_U625_MY20_Phev_Rx" SG_ 826 Memory_2_Sw_Stat 1;
BA_ "U_CX482_CX483_MY20_Rx" SG_ 826 Memory_2_Sw_Stat 1;
BA_ "U_U611_U625_MY20_Hev_Rx" SG_ 826 Memory_2_Sw_Stat 1;
BA_ "U_U611_U625_MY20_Gas_Rx" SG_ 826 Memory_2_Sw_Stat 1;
BA_ "U_C490_MY18_Rx" SG_ 826 Memory_2_Sw_Stat 1;
BA_ "GenSigSendType" SG_ 826 Memory_2_Sw_Stat 3;
BA_ "WakeupSignal" SG_ 826 Memory_2_Sw_Stat 1;
BA_ "U_P702_MY2021_Tx" SG_ 826 Memory_1_Sw_Stat 1;
BA_ "U_CX727_MY2021_Tx" SG_ 826 Memory_1_Sw_Stat 1;
BA_ "U_CX430_MY2021_Tx" SG_ 826 Memory_1_Sw_Stat 1;
BA_ "U_U611_U625_MY20_Phev_Tx" SG_ 826 Memory_1_Sw_Stat 1;
BA_ "U_CX482_CX483_MY20_Tx" SG_ 826 Memory_1_Sw_Stat 1;
BA_ "U_U611_U625_MY20_Hev_Tx" SG_ 826 Memory_1_Sw_Stat 1;
BA_ "U_U611_U625_MY20_Gas_Tx" SG_ 826 Memory_1_Sw_Stat 1;
BA_ "U_C490_MY18_Tx" SG_ 826 Memory_1_Sw_Stat 1;
BA_ "U_C519_MY18_5_Gas_Tx" SG_ 826 Memory_1_Sw_Stat 1;
BA_ "U_C519_MY18_5_Diesel_Tx" SG_ 826 Memory_1_Sw_Stat 1;
BA_ "U_B515_MCA_MY17_Gas_Tx" SG_ 826 Memory_1_Sw_Stat 1;
BA_ "U_B515_MCA_MY17_Diesel_Tx" SG_ 826 Memory_1_Sw_Stat 1;
BA_ "U_B479_MY17_Diesel_Tx" SG_ 826 Memory_1_Sw_Stat 1;
BA_ "U_B479_MY17_Gas_Tx" SG_ 826 Memory_1_Sw_Stat 1;
BA_ "U_P702_MY2021_Rx" SG_ 826 Memory_1_Sw_Stat 1;
BA_ "U_CX727_MY2021_Rx" SG_ 826 Memory_1_Sw_Stat 1;
BA_ "U_CX430_MY2021_Rx" SG_ 826 Memory_1_Sw_Stat 1;
BA_ "U_U611_U625_MY20_Phev_Rx" SG_ 826 Memory_1_Sw_Stat 1;
BA_ "U_CX482_CX483_MY20_Rx" SG_ 826 Memory_1_Sw_Stat 1;
BA_ "U_U611_U625_MY20_Hev_Rx" SG_ 826 Memory_1_Sw_Stat 1;
BA_ "U_U611_U625_MY20_Gas_Rx" SG_ 826 Memory_1_Sw_Stat 1;
BA_ "U_C490_MY18_Rx" SG_ 826 Memory_1_Sw_Stat 1;
BA_ "GenSigSendType" SG_ 826 Memory_1_Sw_Stat 3;
BA_ "WakeupSignal" SG_ 826 Memory_1_Sw_Stat 1;
BA_ "U_P702_MY2021_Tx" SG_ 826 Mirror_Manual_Override 1;
BA_ "U_CX727_MY2021_Tx" SG_ 826 Mirror_Manual_Override 1;
BA_ "U_CX430_MY2021_Tx" SG_ 826 Mirror_Manual_Override 1;
BA_ "U_U611_U625_MY20_Phev_Tx" SG_ 826 Mirror_Manual_Override 1;
BA_ "U_CX482_CX483_MY20_Tx" SG_ 826 Mirror_Manual_Override 1;
BA_ "U_U611_U625_MY20_Hev_Tx" SG_ 826 Mirror_Manual_Override 1;
BA_ "U_U611_U625_MY20_Gas_Tx" SG_ 826 Mirror_Manual_Override 1;
BA_ "U_C490_MY18_Tx" SG_ 826 Mirror_Manual_Override 1;
BA_ "U_C519_MY18_5_Gas_Tx" SG_ 826 Mirror_Manual_Override 1;
BA_ "U_C519_MY18_5_Diesel_Tx" SG_ 826 Mirror_Manual_Override 1;
BA_ "U_B515_MCA_MY17_Gas_Tx" SG_ 826 Mirror_Manual_Override 1;
BA_ "U_B515_MCA_MY17_Diesel_Tx" SG_ 826 Mirror_Manual_Override 1;
BA_ "U_B479_MY17_Diesel_Tx" SG_ 826 Mirror_Manual_Override 1;
BA_ "U_B479_MY17_Gas_Tx" SG_ 826 Mirror_Manual_Override 1;
BA_ "U_P702_MY2021_Rx" SG_ 826 Mirror_Manual_Override 1;
BA_ "U_CX727_MY2021_Rx" SG_ 826 Mirror_Manual_Override 1;
BA_ "U_CX430_MY2021_Rx" SG_ 826 Mirror_Manual_Override 1;
BA_ "U_U611_U625_MY20_Phev_Rx" SG_ 826 Mirror_Manual_Override 1;
BA_ "U_CX482_CX483_MY20_Rx" SG_ 826 Mirror_Manual_Override 1;
BA_ "U_U611_U625_MY20_Hev_Rx" SG_ 826 Mirror_Manual_Override 1;
BA_ "U_U611_U625_MY20_Gas_Rx" SG_ 826 Mirror_Manual_Override 1;
BA_ "U_C490_MY18_Rx" SG_ 826 Mirror_Manual_Override 1;
BA_ "GenSigSendType" SG_ 826 Mirror_Manual_Override 3;
BA_ "WakeupSignal" SG_ 826 Mirror_Manual_Override 1;
BA_ "U_CX482_CX483_MY20_Tx" SG_ 1289 AHCM_Network_Mgmt 1;
BA_ "GenSigSendType" SG_ 1289 AHCM_Network_Mgmt 3;
BA_ "U_P702_MY2021_Tx" SG_ 853 Front_AUTO_Blwr_Lvl 1;
BA_ "U_CX727_MY2021_Tx" SG_ 853 Front_AUTO_Blwr_Lvl 1;
BA_ "U_CX430_MY2021_Tx" SG_ 853 Front_AUTO_Blwr_Lvl 1;
BA_ "U_U611_U625_MY20_Phev_Tx" SG_ 853 Front_AUTO_Blwr_Lvl 1;
BA_ "U_CX482_CX483_MY20_Tx" SG_ 853 Front_AUTO_Blwr_Lvl 1;
BA_ "U_U611_U625_MY20_Hev_Tx" SG_ 853 Front_AUTO_Blwr_Lvl 1;
BA_ "U_U611_U625_MY20_Gas_Tx" SG_ 853 Front_AUTO_Blwr_Lvl 1;
BA_ "U_B500_MY18_Diesel_Tx" SG_ 853 Front_AUTO_Blwr_Lvl 1;
BA_ "U_B500_MY18_Gas_Tx" SG_ 853 Front_AUTO_Blwr_Lvl 1;
BA_ "U_C519_MY18_5_Gas_Tx" SG_ 853 Front_AUTO_Blwr_Lvl 1;
BA_ "U_C519_MY18_5_Diesel_Tx" SG_ 853 Front_AUTO_Blwr_Lvl 1;
BA_ "U_B515_MCA_MY17_Gas_Tx" SG_ 853 Front_AUTO_Blwr_Lvl 1;
BA_ "U_B515_MCA_MY17_Diesel_Tx" SG_ 853 Front_AUTO_Blwr_Lvl 1;
BA_ "U_B479_MY17_Diesel_Tx" SG_ 853 Front_AUTO_Blwr_Lvl 1;
BA_ "U_B479_MY17_Gas_Tx" SG_ 853 Front_AUTO_Blwr_Lvl 1;
BA_ "GenSigSendType" SG_ 853 Front_AUTO_Blwr_Lvl 3;
BA_ "U_P702_MY2021_Tx" SG_ 853 FrontMnu_Buttn_Stat 1;
BA_ "U_CX727_MY2021_Tx" SG_ 853 FrontMnu_Buttn_Stat 1;
BA_ "U_CX430_MY2021_Tx" SG_ 853 FrontMnu_Buttn_Stat 1;
BA_ "U_U611_U625_MY20_Phev_Tx" SG_ 853 FrontMnu_Buttn_Stat 1;
BA_ "U_CX482_CX483_MY20_Tx" SG_ 853 FrontMnu_Buttn_Stat 1;
BA_ "U_U611_U625_MY20_Hev_Tx" SG_ 853 FrontMnu_Buttn_Stat 1;
BA_ "U_U611_U625_MY20_Gas_Tx" SG_ 853 FrontMnu_Buttn_Stat 1;
BA_ "U_C490_MY18_Tx" SG_ 853 FrontMnu_Buttn_Stat 1;
BA_ "GenSigSendType" SG_ 853 FrontMnu_Buttn_Stat 3;
BA_ "U_P702_MY2021_Tx" SG_ 853 RHS_Cond_Seat_Status 1;
BA_ "U_CX727_MY2021_Tx" SG_ 853 RHS_Cond_Seat_Status 1;
BA_ "U_CX430_MY2021_Tx" SG_ 853 RHS_Cond_Seat_Status 1;
BA_ "U_U611_U625_MY20_Phev_Tx" SG_ 853 RHS_Cond_Seat_Status 1;
BA_ "U_CX482_CX483_MY20_Tx" SG_ 853 RHS_Cond_Seat_Status 1;
BA_ "U_U611_U625_MY20_Hev_Tx" SG_ 853 RHS_Cond_Seat_Status 1;
BA_ "U_U611_U625_MY20_Gas_Tx" SG_ 853 RHS_Cond_Seat_Status 1;
BA_ "U_B500_MY18_Diesel_Tx" SG_ 853 RHS_Cond_Seat_Status 1;
BA_ "U_B500_MY18_Gas_Tx" SG_ 853 RHS_Cond_Seat_Status 1;
BA_ "U_C519_MY18_5_Gas_Tx" SG_ 853 RHS_Cond_Seat_Status 1;
BA_ "U_C519_MY18_5_Diesel_Tx" SG_ 853 RHS_Cond_Seat_Status 1;
BA_ "U_B515_MCA_MY17_Gas_Tx" SG_ 853 RHS_Cond_Seat_Status 1;
BA_ "U_B515_MCA_MY17_Diesel_Tx" SG_ 853 RHS_Cond_Seat_Status 1;
BA_ "U_B479_MY17_Diesel_Tx" SG_ 853 RHS_Cond_Seat_Status 1;
BA_ "U_B479_MY17_Gas_Tx" SG_ 853 RHS_Cond_Seat_Status 1;
BA_ "GenSigSendType" SG_ 853 RHS_Cond_Seat_Status 3;
BA_ "CrossOver_InfoCAN" SG_ 853 RHS_Cond_Seat_Status 1;
BA_ "U_P702_MY2021_Tx" SG_ 853 LHS_Cond_Seat_Status 1;
BA_ "U_CX727_MY2021_Tx" SG_ 853 LHS_Cond_Seat_Status 1;
BA_ "U_CX430_MY2021_Tx" SG_ 853 LHS_Cond_Seat_Status 1;
BA_ "U_U611_U625_MY20_Phev_Tx" SG_ 853 LHS_Cond_Seat_Status 1;
BA_ "U_CX482_CX483_MY20_Tx" SG_ 853 LHS_Cond_Seat_Status 1;
BA_ "U_U611_U625_MY20_Hev_Tx" SG_ 853 LHS_Cond_Seat_Status 1;
BA_ "U_U611_U625_MY20_Gas_Tx" SG_ 853 LHS_Cond_Seat_Status 1;
BA_ "U_B500_MY18_Diesel_Tx" SG_ 853 LHS_Cond_Seat_Status 1;
BA_ "U_B500_MY18_Gas_Tx" SG_ 853 LHS_Cond_Seat_Status 1;
BA_ "U_C519_MY18_5_Gas_Tx" SG_ 853 LHS_Cond_Seat_Status 1;
BA_ "U_C519_MY18_5_Diesel_Tx" SG_ 853 LHS_Cond_Seat_Status 1;
BA_ "U_B515_MCA_MY17_Gas_Tx" SG_ 853 LHS_Cond_Seat_Status 1;
BA_ "U_B515_MCA_MY17_Diesel_Tx" SG_ 853 LHS_Cond_Seat_Status 1;
BA_ "U_B479_MY17_Diesel_Tx" SG_ 853 LHS_Cond_Seat_Status 1;
BA_ "U_B479_MY17_Gas_Tx" SG_ 853 LHS_Cond_Seat_Status 1;
BA_ "GenSigSendType" SG_ 853 LHS_Cond_Seat_Status 3;
BA_ "CrossOver_InfoCAN" SG_ 853 LHS_Cond_Seat_Status 1;
BA_ "U_P702_MY2021_Tx" SG_ 853 Htd_Strg_Whl_Status 1;
BA_ "U_CX727_MY2021_Tx" SG_ 853 Htd_Strg_Whl_Status 1;
BA_ "U_CX430_MY2021_Tx" SG_ 853 Htd_Strg_Whl_Status 1;
BA_ "U_U611_U625_MY20_Phev_Tx" SG_ 853 Htd_Strg_Whl_Status 1;
BA_ "U_CX482_CX483_MY20_Tx" SG_ 853 Htd_Strg_Whl_Status 1;
BA_ "U_U611_U625_MY20_Hev_Tx" SG_ 853 Htd_Strg_Whl_Status 1;
BA_ "U_U611_U625_MY20_Gas_Tx" SG_ 853 Htd_Strg_Whl_Status 1;
BA_ "U_B500_MY18_Diesel_Tx" SG_ 853 Htd_Strg_Whl_Status 1;
BA_ "U_B500_MY18_Gas_Tx" SG_ 853 Htd_Strg_Whl_Status 1;
BA_ "U_C519_MY18_5_Gas_Tx" SG_ 853 Htd_Strg_Whl_Status 1;
BA_ "U_C519_MY18_5_Diesel_Tx" SG_ 853 Htd_Strg_Whl_Status 1;
BA_ "U_B515_MCA_MY17_Gas_Tx" SG_ 853 Htd_Strg_Whl_Status 1;
BA_ "U_B515_MCA_MY17_Diesel_Tx" SG_ 853 Htd_Strg_Whl_Status 1;
BA_ "U_B479_MY17_Diesel_Tx" SG_ 853 Htd_Strg_Whl_Status 1;
BA_ "U_B479_MY17_Gas_Tx" SG_ 853 Htd_Strg_Whl_Status 1;
BA_ "GenSigSendType" SG_ 853 Htd_Strg_Whl_Status 3;
BA_ "GenSigStartValue" SG_ 853 Htd_Strg_Whl_Status 2;
BA_ "GenSigStartValueInteger" SG_ 853 Htd_Strg_Whl_Status 2;
BA_ "CrossOver_InfoCAN" SG_ 853 Htd_Strg_Whl_Status 1;
BA_ "U_P702_MY2021_Tx" SG_ 853 Htd_Strg_Whl_Btn_Stt 1;
BA_ "U_CX727_MY2021_Tx" SG_ 853 Htd_Strg_Whl_Btn_Stt 1;
BA_ "U_CX430_MY2021_Tx" SG_ 853 Htd_Strg_Whl_Btn_Stt 1;
BA_ "U_U611_U625_MY20_Phev_Tx" SG_ 853 Htd_Strg_Whl_Btn_Stt 1;
BA_ "U_CX482_CX483_MY20_Tx" SG_ 853 Htd_Strg_Whl_Btn_Stt 1;
BA_ "U_U611_U625_MY20_Hev_Tx" SG_ 853 Htd_Strg_Whl_Btn_Stt 1;
BA_ "U_U611_U625_MY20_Gas_Tx" SG_ 853 Htd_Strg_Whl_Btn_Stt 1;
BA_ "U_B500_MY18_Diesel_Tx" SG_ 853 Htd_Strg_Whl_Btn_Stt 1;
BA_ "U_B500_MY18_Gas_Tx" SG_ 853 Htd_Strg_Whl_Btn_Stt 1;
BA_ "U_C519_MY18_5_Gas_Tx" SG_ 853 Htd_Strg_Whl_Btn_Stt 1;
BA_ "U_C519_MY18_5_Diesel_Tx" SG_ 853 Htd_Strg_Whl_Btn_Stt 1;
BA_ "U_B515_MCA_MY17_Gas_Tx" SG_ 853 Htd_Strg_Whl_Btn_Stt 1;
BA_ "U_B515_MCA_MY17_Diesel_Tx" SG_ 853 Htd_Strg_Whl_Btn_Stt 1;
BA_ "U_B479_MY17_Diesel_Tx" SG_ 853 Htd_Strg_Whl_Btn_Stt 1;
BA_ "U_B479_MY17_Gas_Tx" SG_ 853 Htd_Strg_Whl_Btn_Stt 1;
BA_ "GenSigSendType" SG_ 853 Htd_Strg_Whl_Btn_Stt 3;
BA_ "GenSigStartValue" SG_ 853 Htd_Strg_Whl_Btn_Stt 2;
BA_ "GenSigStartValueInteger" SG_ 853 Htd_Strg_Whl_Btn_Stt 2;
BA_ "CrossOver_InfoCAN" SG_ 853 Htd_Strg_Whl_Btn_Stt 1;
BA_ "U_P702_MY2021_Tx" SG_ 853 Defrost_Btn_Stt 1;
BA_ "U_CX727_MY2021_Tx" SG_ 853 Defrost_Btn_Stt 1;
BA_ "U_CX430_MY2021_Tx" SG_ 853 Defrost_Btn_Stt 1;
BA_ "U_U611_U625_MY20_Phev_Tx" SG_ 853 Defrost_Btn_Stt 1;
BA_ "U_B562_MY18_Diesel_Tx" SG_ 853 Defrost_Btn_Stt 1;
BA_ "U_CX482_CX483_MY20_Tx" SG_ 853 Defrost_Btn_Stt 1;
BA_ "U_U611_U625_MY20_Hev_Tx" SG_ 853 Defrost_Btn_Stt 1;
BA_ "U_U611_U625_MY20_Gas_Tx" SG_ 853 Defrost_Btn_Stt 1;
BA_ "U_B500_MY18_Diesel_Tx" SG_ 853 Defrost_Btn_Stt 1;
BA_ "U_B500_MY18_Gas_Tx" SG_ 853 Defrost_Btn_Stt 1;
BA_ "U_C490_MY18_Tx" SG_ 853 Defrost_Btn_Stt 1;
BA_ "U_B562_MY18_Gas_Tx" SG_ 853 Defrost_Btn_Stt 1;
BA_ "U_C519_MY18_5_Gas_Tx" SG_ 853 Defrost_Btn_Stt 1;
BA_ "U_C519_MY18_5_Diesel_Tx" SG_ 853 Defrost_Btn_Stt 1;
BA_ "U_B515_MCA_MY17_Gas_Tx" SG_ 853 Defrost_Btn_Stt 1;
BA_ "U_B515_MCA_MY17_Diesel_Tx" SG_ 853 Defrost_Btn_Stt 1;
BA_ "U_B479_MY17_Diesel_Tx" SG_ 853 Defrost_Btn_Stt 1;
BA_ "U_B479_MY17_Gas_Tx" SG_ 853 Defrost_Btn_Stt 1;
BA_ "GenSigSendType" SG_ 853 Defrost_Btn_Stt 3;
BA_ "GenSigStartValue" SG_ 853 Defrost_Btn_Stt 2;
BA_ "GenSigStartValueInteger" SG_ 853 Defrost_Btn_Stt 2;
BA_ "CrossOver_InfoCAN" SG_ 853 Defrost_Btn_Stt 1;
BA_ "U_P702_MY2021_Tx" SG_ 853 CC_Fr_Btn_User_Adj 1;
BA_ "U_CX727_MY2021_Tx" SG_ 853 CC_Fr_Btn_User_Adj 1;
BA_ "U_CX430_MY2021_Tx" SG_ 853 CC_Fr_Btn_User_Adj 1;
BA_ "U_U611_U625_MY20_Phev_Tx" SG_ 853 CC_Fr_Btn_User_Adj 1;
BA_ "U_CX482_CX483_MY20_Tx" SG_ 853 CC_Fr_Btn_User_Adj 1;
BA_ "U_U611_U625_MY20_Hev_Tx" SG_ 853 CC_Fr_Btn_User_Adj 1;
BA_ "U_U611_U625_MY20_Gas_Tx" SG_ 853 CC_Fr_Btn_User_Adj 1;
BA_ "U_B500_MY18_Diesel_Tx" SG_ 853 CC_Fr_Btn_User_Adj 1;
BA_ "U_B500_MY18_Gas_Tx" SG_ 853 CC_Fr_Btn_User_Adj 1;
BA_ "U_C490_MY18_Tx" SG_ 853 CC_Fr_Btn_User_Adj 1;
BA_ "U_C519_MY18_5_Gas_Tx" SG_ 853 CC_Fr_Btn_User_Adj 1;
BA_ "U_C519_MY18_5_Diesel_Tx" SG_ 853 CC_Fr_Btn_User_Adj 1;
BA_ "U_B515_MCA_MY17_Gas_Tx" SG_ 853 CC_Fr_Btn_User_Adj 1;
BA_ "U_B515_MCA_MY17_Diesel_Tx" SG_ 853 CC_Fr_Btn_User_Adj 1;
BA_ "U_B479_MY17_Diesel_Tx" SG_ 853 CC_Fr_Btn_User_Adj 1;
BA_ "U_B479_MY17_Gas_Tx" SG_ 853 CC_Fr_Btn_User_Adj 1;
BA_ "GenSigSendType" SG_ 853 CC_Fr_Btn_User_Adj 3;
BA_ "CrossOver_InfoCAN" SG_ 853 CC_Fr_Btn_User_Adj 1;
BA_ "U_P702_MY2021_Tx" SG_ 853 RHS_Htd_Seat_Btn_Stt 1;
BA_ "U_CX727_MY2021_Tx" SG_ 853 RHS_Htd_Seat_Btn_Stt 1;
BA_ "U_CX430_MY2021_Tx" SG_ 853 RHS_Htd_Seat_Btn_Stt 1;
BA_ "U_U611_U625_MY20_Phev_Tx" SG_ 853 RHS_Htd_Seat_Btn_Stt 1;
BA_ "U_CX482_CX483_MY20_Tx" SG_ 853 RHS_Htd_Seat_Btn_Stt 1;
BA_ "U_U611_U625_MY20_Hev_Tx" SG_ 853 RHS_Htd_Seat_Btn_Stt 1;
BA_ "U_U611_U625_MY20_Gas_Tx" SG_ 853 RHS_Htd_Seat_Btn_Stt 1;
BA_ "U_B500_MY18_Diesel_Tx" SG_ 853 RHS_Htd_Seat_Btn_Stt 1;
BA_ "U_B500_MY18_Gas_Tx" SG_ 853 RHS_Htd_Seat_Btn_Stt 1;
BA_ "U_C519_MY18_5_Gas_Tx" SG_ 853 RHS_Htd_Seat_Btn_Stt 1;
BA_ "U_C519_MY18_5_Diesel_Tx" SG_ 853 RHS_Htd_Seat_Btn_Stt 1;
BA_ "U_B515_MCA_MY17_Gas_Tx" SG_ 853 RHS_Htd_Seat_Btn_Stt 1;
BA_ "U_B515_MCA_MY17_Diesel_Tx" SG_ 853 RHS_Htd_Seat_Btn_Stt 1;
BA_ "U_B479_MY17_Diesel_Tx" SG_ 853 RHS_Htd_Seat_Btn_Stt 1;
BA_ "U_B479_MY17_Gas_Tx" SG_ 853 RHS_Htd_Seat_Btn_Stt 1;
BA_ "GenSigSendType" SG_ 853 RHS_Htd_Seat_Btn_Stt 3;
BA_ "GenSigStartValue" SG_ 853 RHS_Htd_Seat_Btn_Stt 2;
BA_ "GenSigStartValueInteger" SG_ 853 RHS_Htd_Seat_Btn_Stt 2;
BA_ "CrossOver_InfoCAN" SG_ 853 RHS_Htd_Seat_Btn_Stt 1;
BA_ "U_P702_MY2021_Tx" SG_ 853 RHS_Cld_Seat_Btn_Stt 1;
BA_ "U_CX727_MY2021_Tx" SG_ 853 RHS_Cld_Seat_Btn_Stt 1;
BA_ "U_CX430_MY2021_Tx" SG_ 853 RHS_Cld_Seat_Btn_Stt 1;
BA_ "U_U611_U625_MY20_Phev_Tx" SG_ 853 RHS_Cld_Seat_Btn_Stt 1;
BA_ "U_CX482_CX483_MY20_Tx" SG_ 853 RHS_Cld_Seat_Btn_Stt 1;
BA_ "U_U611_U625_MY20_Hev_Tx" SG_ 853 RHS_Cld_Seat_Btn_Stt 1;
BA_ "U_U611_U625_MY20_Gas_Tx" SG_ 853 RHS_Cld_Seat_Btn_Stt 1;
BA_ "U_B500_MY18_Diesel_Tx" SG_ 853 RHS_Cld_Seat_Btn_Stt 1;
BA_ "U_B500_MY18_Gas_Tx" SG_ 853 RHS_Cld_Seat_Btn_Stt 1;
BA_ "U_C519_MY18_5_Gas_Tx" SG_ 853 RHS_Cld_Seat_Btn_Stt 1;
BA_ "U_C519_MY18_5_Diesel_Tx" SG_ 853 RHS_Cld_Seat_Btn_Stt 1;
BA_ "U_B515_MCA_MY17_Gas_Tx" SG_ 853 RHS_Cld_Seat_Btn_Stt 1;
BA_ "U_B515_MCA_MY17_Diesel_Tx" SG_ 853 RHS_Cld_Seat_Btn_Stt 1;
BA_ "U_B479_MY17_Diesel_Tx" SG_ 853 RHS_Cld_Seat_Btn_Stt 1;
BA_ "U_B479_MY17_Gas_Tx" SG_ 853 RHS_Cld_Seat_Btn_Stt 1;
BA_ "GenSigSendType" SG_ 853 RHS_Cld_Seat_Btn_Stt 3;
BA_ "GenSigStartValue" SG_ 853 RHS_Cld_Seat_Btn_Stt 2;
BA_ "GenSigStartValueInteger" SG_ 853 RHS_Cld_Seat_Btn_Stt 2;
BA_ "CrossOver_InfoCAN" SG_ 853 RHS_Cld_Seat_Btn_Stt 1;
BA_ "U_P702_MY2021_Tx" SG_ 853 Outside_Btn_Stt 1;
BA_ "U_CX727_MY2021_Tx" SG_ 853 Outside_Btn_Stt 1;
BA_ "U_CX430_MY2021_Tx" SG_ 853 Outside_Btn_Stt 1;
BA_ "U_U611_U625_MY20_Phev_Tx" SG_ 853 Outside_Btn_Stt 1;
BA_ "U_CX482_CX483_MY20_Tx" SG_ 853 Outside_Btn_Stt 1;
BA_ "U_U611_U625_MY20_Hev_Tx" SG_ 853 Outside_Btn_Stt 1;
BA_ "U_U611_U625_MY20_Gas_Tx" SG_ 853 Outside_Btn_Stt 1;
BA_ "U_B500_MY18_Diesel_Tx" SG_ 853 Outside_Btn_Stt 1;
BA_ "U_B500_MY18_Gas_Tx" SG_ 853 Outside_Btn_Stt 1;
BA_ "U_C519_MY18_5_Gas_Tx" SG_ 853 Outside_Btn_Stt 1;
BA_ "U_C519_MY18_5_Diesel_Tx" SG_ 853 Outside_Btn_Stt 1;
BA_ "U_B515_MCA_MY17_Gas_Tx" SG_ 853 Outside_Btn_Stt 1;
BA_ "U_B515_MCA_MY17_Diesel_Tx" SG_ 853 Outside_Btn_Stt 1;
BA_ "U_B479_MY17_Diesel_Tx" SG_ 853 Outside_Btn_Stt 1;
BA_ "U_B479_MY17_Gas_Tx" SG_ 853 Outside_Btn_Stt 1;
BA_ "GenSigSendType" SG_ 853 Outside_Btn_Stt 3;
BA_ "GenSigStartValue" SG_ 853 Outside_Btn_Stt 2;
BA_ "GenSigStartValueInteger" SG_ 853 Outside_Btn_Stt 2;
BA_ "CrossOver_InfoCAN" SG_ 853 Outside_Btn_Stt 1;
BA_ "U_P702_MY2021_Tx" SG_ 853 LHS_Htd_Seat_Btn_Stt 1;
BA_ "U_CX727_MY2021_Tx" SG_ 853 LHS_Htd_Seat_Btn_Stt 1;
BA_ "U_CX430_MY2021_Tx" SG_ 853 LHS_Htd_Seat_Btn_Stt 1;
BA_ "U_U611_U625_MY20_Phev_Tx" SG_ 853 LHS_Htd_Seat_Btn_Stt 1;
BA_ "U_CX482_CX483_MY20_Tx" SG_ 853 LHS_Htd_Seat_Btn_Stt 1;
BA_ "U_U611_U625_MY20_Hev_Tx" SG_ 853 LHS_Htd_Seat_Btn_Stt 1;
BA_ "U_U611_U625_MY20_Gas_Tx" SG_ 853 LHS_Htd_Seat_Btn_Stt 1;
BA_ "U_B500_MY18_Diesel_Tx" SG_ 853 LHS_Htd_Seat_Btn_Stt 1;
BA_ "U_B500_MY18_Gas_Tx" SG_ 853 LHS_Htd_Seat_Btn_Stt 1;
BA_ "U_C519_MY18_5_Gas_Tx" SG_ 853 LHS_Htd_Seat_Btn_Stt 1;
BA_ "U_C519_MY18_5_Diesel_Tx" SG_ 853 LHS_Htd_Seat_Btn_Stt 1;
BA_ "U_B515_MCA_MY17_Gas_Tx" SG_ 853 LHS_Htd_Seat_Btn_Stt 1;
BA_ "U_B515_MCA_MY17_Diesel_Tx" SG_ 853 LHS_Htd_Seat_Btn_Stt 1;
BA_ "U_B479_MY17_Diesel_Tx" SG_ 853 LHS_Htd_Seat_Btn_Stt 1;
BA_ "U_B479_MY17_Gas_Tx" SG_ 853 LHS_Htd_Seat_Btn_Stt 1;
BA_ "GenSigSendType" SG_ 853 LHS_Htd_Seat_Btn_Stt 3;
BA_ "GenSigStartValue" SG_ 853 LHS_Htd_Seat_Btn_Stt 2;
BA_ "GenSigStartValueInteger" SG_ 853 LHS_Htd_Seat_Btn_Stt 2;
BA_ "CrossOver_InfoCAN" SG_ 853 LHS_Htd_Seat_Btn_Stt 1;
BA_ "U_P702_MY2021_Tx" SG_ 853 LHS_Cld_Seat_Btn_Stt 1;
BA_ "U_CX727_MY2021_Tx" SG_ 853 LHS_Cld_Seat_Btn_Stt 1;
BA_ "U_CX430_MY2021_Tx" SG_ 853 LHS_Cld_Seat_Btn_Stt 1;
BA_ "U_U611_U625_MY20_Phev_Tx" SG_ 853 LHS_Cld_Seat_Btn_Stt 1;
BA_ "U_CX482_CX483_MY20_Tx" SG_ 853 LHS_Cld_Seat_Btn_Stt 1;
BA_ "U_U611_U625_MY20_Hev_Tx" SG_ 853 LHS_Cld_Seat_Btn_Stt 1;
BA_ "U_U611_U625_MY20_Gas_Tx" SG_ 853 LHS_Cld_Seat_Btn_Stt 1;
BA_ "U_B500_MY18_Diesel_Tx" SG_ 853 LHS_Cld_Seat_Btn_Stt 1;
BA_ "U_B500_MY18_Gas_Tx" SG_ 853 LHS_Cld_Seat_Btn_Stt 1;
BA_ "U_C519_MY18_5_Gas_Tx" SG_ 853 LHS_Cld_Seat_Btn_Stt 1;
BA_ "U_C519_MY18_5_Diesel_Tx" SG_ 853 LHS_Cld_Seat_Btn_Stt 1;
BA_ "U_B515_MCA_MY17_Gas_Tx" SG_ 853 LHS_Cld_Seat_Btn_Stt 1;
BA_ "U_B515_MCA_MY17_Diesel_Tx" SG_ 853 LHS_Cld_Seat_Btn_Stt 1;
BA_ "U_B479_MY17_Diesel_Tx" SG_ 853 LHS_Cld_Seat_Btn_Stt 1;
BA_ "U_B479_MY17_Gas_Tx" SG_ 853 LHS_Cld_Seat_Btn_Stt 1;
BA_ "GenSigSendType" SG_ 853 LHS_Cld_Seat_Btn_Stt 3;
BA_ "GenSigStartValue" SG_ 853 LHS_Cld_Seat_Btn_Stt 2;
BA_ "GenSigStartValueInteger" SG_ 853 LHS_Cld_Seat_Btn_Stt 2;
BA_ "CrossOver_InfoCAN" SG_ 853 LHS_Cld_Seat_Btn_Stt 1;
BA_ "U_P702_MY2021_Tx" SG_ 853 Htd_Frt_Wsh_Btn_Stt 1;
BA_ "U_CX727_MY2021_Tx" SG_ 853 Htd_Frt_Wsh_Btn_Stt 1;
BA_ "U_CX430_MY2021_Tx" SG_ 853 Htd_Frt_Wsh_Btn_Stt 1;
BA_ "U_U611_U625_MY20_Phev_Tx" SG_ 853 Htd_Frt_Wsh_Btn_Stt 1;
BA_ "U_B562_MY18_Diesel_Tx" SG_ 853 Htd_Frt_Wsh_Btn_Stt 1;
BA_ "U_CX482_CX483_MY20_Tx" SG_ 853 Htd_Frt_Wsh_Btn_Stt 1;
BA_ "U_U611_U625_MY20_Hev_Tx" SG_ 853 Htd_Frt_Wsh_Btn_Stt 1;
BA_ "U_U611_U625_MY20_Gas_Tx" SG_ 853 Htd_Frt_Wsh_Btn_Stt 1;
BA_ "U_B500_MY18_Diesel_Tx" SG_ 853 Htd_Frt_Wsh_Btn_Stt 1;
BA_ "U_B500_MY18_Gas_Tx" SG_ 853 Htd_Frt_Wsh_Btn_Stt 1;
BA_ "U_B562_MY18_Gas_Tx" SG_ 853 Htd_Frt_Wsh_Btn_Stt 1;
BA_ "U_C519_MY18_5_Gas_Tx" SG_ 853 Htd_Frt_Wsh_Btn_Stt 1;
BA_ "U_C519_MY18_5_Diesel_Tx" SG_ 853 Htd_Frt_Wsh_Btn_Stt 1;
BA_ "U_B515_MCA_MY17_Gas_Tx" SG_ 853 Htd_Frt_Wsh_Btn_Stt 1;
BA_ "U_B515_MCA_MY17_Diesel_Tx" SG_ 853 Htd_Frt_Wsh_Btn_Stt 1;
BA_ "U_B479_MY17_Diesel_Tx" SG_ 853 Htd_Frt_Wsh_Btn_Stt 1;
BA_ "U_B479_MY17_Gas_Tx" SG_ 853 Htd_Frt_Wsh_Btn_Stt 1;
BA_ "GenSigSendType" SG_ 853 Htd_Frt_Wsh_Btn_Stt 3;
BA_ "GenSigStartValue" SG_ 853 Htd_Frt_Wsh_Btn_Stt 2;
BA_ "GenSigStartValueInteger" SG_ 853 Htd_Frt_Wsh_Btn_Stt 2;
BA_ "CrossOver_InfoCAN" SG_ 853 Htd_Frt_Wsh_Btn_Stt 1;
BA_ "U_P702_MY2021_Tx" SG_ 853 Auto_Recirc_Btn_Stt 1;
BA_ "U_CX727_MY2021_Tx" SG_ 853 Auto_Recirc_Btn_Stt 1;
BA_ "U_CX430_MY2021_Tx" SG_ 853 Auto_Recirc_Btn_Stt 1;
BA_ "U_U611_U625_MY20_Phev_Tx" SG_ 853 Auto_Recirc_Btn_Stt 1;
BA_ "U_CX482_CX483_MY20_Tx" SG_ 853 Auto_Recirc_Btn_Stt 1;
BA_ "U_U611_U625_MY20_Hev_Tx" SG_ 853 Auto_Recirc_Btn_Stt 1;
BA_ "U_U611_U625_MY20_Gas_Tx" SG_ 853 Auto_Recirc_Btn_Stt 1;
BA_ "U_B500_MY18_Diesel_Tx" SG_ 853 Auto_Recirc_Btn_Stt 1;
BA_ "U_B500_MY18_Gas_Tx" SG_ 853 Auto_Recirc_Btn_Stt 1;
BA_ "U_C519_MY18_5_Gas_Tx" SG_ 853 Auto_Recirc_Btn_Stt 1;
BA_ "U_C519_MY18_5_Diesel_Tx" SG_ 853 Auto_Recirc_Btn_Stt 1;
BA_ "U_B515_MCA_MY17_Gas_Tx" SG_ 853 Auto_Recirc_Btn_Stt 1;
BA_ "U_B515_MCA_MY17_Diesel_Tx" SG_ 853 Auto_Recirc_Btn_Stt 1;
BA_ "U_B479_MY17_Diesel_Tx" SG_ 853 Auto_Recirc_Btn_Stt 1;
BA_ "U_B479_MY17_Gas_Tx" SG_ 853 Auto_Recirc_Btn_Stt 1;
BA_ "GenSigSendType" SG_ 853 Auto_Recirc_Btn_Stt 3;
BA_ "GenSigStartValue" SG_ 853 Auto_Recirc_Btn_Stt 2;
BA_ "GenSigStartValueInteger" SG_ 853 Auto_Recirc_Btn_Stt 2;
BA_ "CrossOver_InfoCAN" SG_ 853 Auto_Recirc_Btn_Stt 1;
BA_ "U_P702_MY2021_Tx" SG_ 853 Windscreen_Btn_Stt 1;
BA_ "U_CX727_MY2021_Tx" SG_ 853 Windscreen_Btn_Stt 1;
BA_ "U_CX430_MY2021_Tx" SG_ 853 Windscreen_Btn_Stt 1;
BA_ "U_U611_U625_MY20_Phev_Tx" SG_ 853 Windscreen_Btn_Stt 1;
BA_ "U_B562_MY18_Diesel_Tx" SG_ 853 Windscreen_Btn_Stt 1;
BA_ "U_CX482_CX483_MY20_Tx" SG_ 853 Windscreen_Btn_Stt 1;
BA_ "U_U611_U625_MY20_Hev_Tx" SG_ 853 Windscreen_Btn_Stt 1;
BA_ "U_U611_U625_MY20_Gas_Tx" SG_ 853 Windscreen_Btn_Stt 1;
BA_ "U_B500_MY18_Diesel_Tx" SG_ 853 Windscreen_Btn_Stt 1;
BA_ "U_B500_MY18_Gas_Tx" SG_ 853 Windscreen_Btn_Stt 1;
BA_ "U_B562_MY18_Gas_Tx" SG_ 853 Windscreen_Btn_Stt 1;
BA_ "U_C519_MY18_5_Gas_Tx" SG_ 853 Windscreen_Btn_Stt 1;
BA_ "U_C519_MY18_5_Diesel_Tx" SG_ 853 Windscreen_Btn_Stt 1;
BA_ "U_B515_MCA_MY17_Gas_Tx" SG_ 853 Windscreen_Btn_Stt 1;
BA_ "U_B515_MCA_MY17_Diesel_Tx" SG_ 853 Windscreen_Btn_Stt 1;
BA_ "U_B479_MY17_Diesel_Tx" SG_ 853 Windscreen_Btn_Stt 1;
BA_ "U_B479_MY17_Gas_Tx" SG_ 853 Windscreen_Btn_Stt 1;
BA_ "GenSigSendType" SG_ 853 Windscreen_Btn_Stt 3;
BA_ "GenSigStartValue" SG_ 853 Windscreen_Btn_Stt 2;
BA_ "GenSigStartValueInteger" SG_ 853 Windscreen_Btn_Stt 2;
BA_ "CrossOver_InfoCAN" SG_ 853 Windscreen_Btn_Stt 1;
BA_ "U_P702_MY2021_Tx" SG_ 853 Panel_Btn_Stt 1;
BA_ "U_CX727_MY2021_Tx" SG_ 853 Panel_Btn_Stt 1;
BA_ "U_CX430_MY2021_Tx" SG_ 853 Panel_Btn_Stt 1;
BA_ "U_U611_U625_MY20_Phev_Tx" SG_ 853 Panel_Btn_Stt 1;
BA_ "U_CX482_CX483_MY20_Tx" SG_ 853 Panel_Btn_Stt 1;
BA_ "U_U611_U625_MY20_Hev_Tx" SG_ 853 Panel_Btn_Stt 1;
BA_ "U_U611_U625_MY20_Gas_Tx" SG_ 853 Panel_Btn_Stt 1;
BA_ "U_B500_MY18_Diesel_Tx" SG_ 853 Panel_Btn_Stt 1;
BA_ "U_B500_MY18_Gas_Tx" SG_ 853 Panel_Btn_Stt 1;
BA_ "U_C490_MY18_Tx" SG_ 853 Panel_Btn_Stt 1;
BA_ "U_C519_MY18_5_Gas_Tx" SG_ 853 Panel_Btn_Stt 1;
BA_ "U_C519_MY18_5_Diesel_Tx" SG_ 853 Panel_Btn_Stt 1;
BA_ "U_B515_MCA_MY17_Gas_Tx" SG_ 853 Panel_Btn_Stt 1;
BA_ "U_B515_MCA_MY17_Diesel_Tx" SG_ 853 Panel_Btn_Stt 1;
BA_ "U_B479_MY17_Diesel_Tx" SG_ 853 Panel_Btn_Stt 1;
BA_ "U_B479_MY17_Gas_Tx" SG_ 853 Panel_Btn_Stt 1;
BA_ "GenSigSendType" SG_ 853 Panel_Btn_Stt 3;
BA_ "GenSigStartValue" SG_ 853 Panel_Btn_Stt 2;
BA_ "GenSigStartValueInteger" SG_ 853 Panel_Btn_Stt 2;
BA_ "CrossOver_InfoCAN" SG_ 853 Panel_Btn_Stt 1;
BA_ "U_P702_MY2021_Tx" SG_ 853 Front_Power_Btn_Stt 1;
BA_ "U_CX727_MY2021_Tx" SG_ 853 Front_Power_Btn_Stt 1;
BA_ "U_CX430_MY2021_Tx" SG_ 853 Front_Power_Btn_Stt 1;
BA_ "U_U611_U625_MY20_Phev_Tx" SG_ 853 Front_Power_Btn_Stt 1;
BA_ "U_CX482_CX483_MY20_Tx" SG_ 853 Front_Power_Btn_Stt 1;
BA_ "U_U611_U625_MY20_Hev_Tx" SG_ 853 Front_Power_Btn_Stt 1;
BA_ "U_U611_U625_MY20_Gas_Tx" SG_ 853 Front_Power_Btn_Stt 1;
BA_ "U_B500_MY18_Diesel_Tx" SG_ 853 Front_Power_Btn_Stt 1;
BA_ "U_B500_MY18_Gas_Tx" SG_ 853 Front_Power_Btn_Stt 1;
BA_ "U_C519_MY18_5_Gas_Tx" SG_ 853 Front_Power_Btn_Stt 1;
BA_ "U_C519_MY18_5_Diesel_Tx" SG_ 853 Front_Power_Btn_Stt 1;
BA_ "U_B515_MCA_MY17_Gas_Tx" SG_ 853 Front_Power_Btn_Stt 1;
BA_ "U_B515_MCA_MY17_Diesel_Tx" SG_ 853 Front_Power_Btn_Stt 1;
BA_ "U_B479_MY17_Diesel_Tx" SG_ 853 Front_Power_Btn_Stt 1;
BA_ "U_B479_MY17_Gas_Tx" SG_ 853 Front_Power_Btn_Stt 1;
BA_ "GenSigSendType" SG_ 853 Front_Power_Btn_Stt 3;
BA_ "GenSigStartValue" SG_ 853 Front_Power_Btn_Stt 2;
BA_ "GenSigStartValueInteger" SG_ 853 Front_Power_Btn_Stt 2;
BA_ "CrossOver_InfoCAN" SG_ 853 Front_Power_Btn_Stt 1;
BA_ "U_P702_MY2021_Tx" SG_ 853 Front_AUTO_Btn_Stt 1;
BA_ "U_CX727_MY2021_Tx" SG_ 853 Front_AUTO_Btn_Stt 1;
BA_ "U_CX430_MY2021_Tx" SG_ 853 Front_AUTO_Btn_Stt 1;
BA_ "U_U611_U625_MY20_Phev_Tx" SG_ 853 Front_AUTO_Btn_Stt 1;
BA_ "U_CX482_CX483_MY20_Tx" SG_ 853 Front_AUTO_Btn_Stt 1;
BA_ "U_U611_U625_MY20_Hev_Tx" SG_ 853 Front_AUTO_Btn_Stt 1;
BA_ "U_U611_U625_MY20_Gas_Tx" SG_ 853 Front_AUTO_Btn_Stt 1;
BA_ "U_B500_MY18_Diesel_Tx" SG_ 853 Front_AUTO_Btn_Stt 1;
BA_ "U_B500_MY18_Gas_Tx" SG_ 853 Front_AUTO_Btn_Stt 1;
BA_ "U_C519_MY18_5_Gas_Tx" SG_ 853 Front_AUTO_Btn_Stt 1;
BA_ "U_C519_MY18_5_Diesel_Tx" SG_ 853 Front_AUTO_Btn_Stt 1;
BA_ "U_B515_MCA_MY17_Gas_Tx" SG_ 853 Front_AUTO_Btn_Stt 1;
BA_ "U_B515_MCA_MY17_Diesel_Tx" SG_ 853 Front_AUTO_Btn_Stt 1;
BA_ "U_B479_MY17_Diesel_Tx" SG_ 853 Front_AUTO_Btn_Stt 1;
BA_ "U_B479_MY17_Gas_Tx" SG_ 853 Front_AUTO_Btn_Stt 1;
BA_ "GenSigSendType" SG_ 853 Front_AUTO_Btn_Stt 3;
BA_ "GenSigStartValue" SG_ 853 Front_AUTO_Btn_Stt 2;
BA_ "GenSigStartValueInteger" SG_ 853 Front_AUTO_Btn_Stt 2;
BA_ "CrossOver_InfoCAN" SG_ 853 Front_AUTO_Btn_Stt 1;
BA_ "U_P702_MY2021_Tx" SG_ 853 Floor_Btn_Stt 1;
BA_ "U_CX727_MY2021_Tx" SG_ 853 Floor_Btn_Stt 1;
BA_ "U_CX430_MY2021_Tx" SG_ 853 Floor_Btn_Stt 1;
BA_ "U_U611_U625_MY20_Phev_Tx" SG_ 853 Floor_Btn_Stt 1;
BA_ "U_CX482_CX483_MY20_Tx" SG_ 853 Floor_Btn_Stt 1;
BA_ "U_U611_U625_MY20_Hev_Tx" SG_ 853 Floor_Btn_Stt 1;
BA_ "U_U611_U625_MY20_Gas_Tx" SG_ 853 Floor_Btn_Stt 1;
BA_ "U_B500_MY18_Diesel_Tx" SG_ 853 Floor_Btn_Stt 1;
BA_ "U_B500_MY18_Gas_Tx" SG_ 853 Floor_Btn_Stt 1;
BA_ "U_C490_MY18_Tx" SG_ 853 Floor_Btn_Stt 1;
BA_ "U_C519_MY18_5_Gas_Tx" SG_ 853 Floor_Btn_Stt 1;
BA_ "U_C519_MY18_5_Diesel_Tx" SG_ 853 Floor_Btn_Stt 1;
BA_ "U_B515_MCA_MY17_Gas_Tx" SG_ 853 Floor_Btn_Stt 1;
BA_ "U_B515_MCA_MY17_Diesel_Tx" SG_ 853 Floor_Btn_Stt 1;
BA_ "U_B479_MY17_Diesel_Tx" SG_ 853 Floor_Btn_Stt 1;
BA_ "U_B479_MY17_Gas_Tx" SG_ 853 Floor_Btn_Stt 1;
BA_ "GenSigSendType" SG_ 853 Floor_Btn_Stt 3;
BA_ "GenSigStartValue" SG_ 853 Floor_Btn_Stt 2;
BA_ "GenSigStartValueInteger" SG_ 853 Floor_Btn_Stt 2;
BA_ "CrossOver_InfoCAN" SG_ 853 Floor_Btn_Stt 1;
BA_ "U_P702_MY2021_Tx" SG_ 853 Dual_Button_Stt 1;
BA_ "U_CX727_MY2021_Tx" SG_ 853 Dual_Button_Stt 1;
BA_ "U_CX430_MY2021_Tx" SG_ 853 Dual_Button_Stt 1;
BA_ "U_U611_U625_MY20_Phev_Tx" SG_ 853 Dual_Button_Stt 1;
BA_ "U_CX482_CX483_MY20_Tx" SG_ 853 Dual_Button_Stt 1;
BA_ "U_U611_U625_MY20_Hev_Tx" SG_ 853 Dual_Button_Stt 1;
BA_ "U_U611_U625_MY20_Gas_Tx" SG_ 853 Dual_Button_Stt 1;
BA_ "U_B500_MY18_Diesel_Tx" SG_ 853 Dual_Button_Stt 1;
BA_ "U_B500_MY18_Gas_Tx" SG_ 853 Dual_Button_Stt 1;
BA_ "U_C519_MY18_5_Gas_Tx" SG_ 853 Dual_Button_Stt 1;
BA_ "U_C519_MY18_5_Diesel_Tx" SG_ 853 Dual_Button_Stt 1;
BA_ "U_B515_MCA_MY17_Gas_Tx" SG_ 853 Dual_Button_Stt 1;
BA_ "U_B515_MCA_MY17_Diesel_Tx" SG_ 853 Dual_Button_Stt 1;
BA_ "U_B479_MY17_Diesel_Tx" SG_ 853 Dual_Button_Stt 1;
BA_ "U_B479_MY17_Gas_Tx" SG_ 853 Dual_Button_Stt 1;
BA_ "GenSigSendType" SG_ 853 Dual_Button_Stt 3;
BA_ "GenSigStartValue" SG_ 853 Dual_Button_Stt 2;
BA_ "GenSigStartValueInteger" SG_ 853 Dual_Button_Stt 2;
BA_ "CrossOver_InfoCAN" SG_ 853 Dual_Button_Stt 1;
BA_ "U_P702_MY2021_Tx" SG_ 853 AC_Btn_Stt 1;
BA_ "U_CX727_MY2021_Tx" SG_ 853 AC_Btn_Stt 1;
BA_ "U_CX430_MY2021_Tx" SG_ 853 AC_Btn_Stt 1;
BA_ "U_U611_U625_MY20_Phev_Tx" SG_ 853 AC_Btn_Stt 1;
BA_ "U_B562_MY18_Diesel_Tx" SG_ 853 AC_Btn_Stt 1;
BA_ "U_CX482_CX483_MY20_Tx" SG_ 853 AC_Btn_Stt 1;
BA_ "U_U611_U625_MY20_Hev_Tx" SG_ 853 AC_Btn_Stt 1;
BA_ "U_U611_U625_MY20_Gas_Tx" SG_ 853 AC_Btn_Stt 1;
BA_ "U_B500_MY18_Diesel_Tx" SG_ 853 AC_Btn_Stt 1;
BA_ "U_B500_MY18_Gas_Tx" SG_ 853 AC_Btn_Stt 1;
BA_ "U_C490_MY18_Tx" SG_ 853 AC_Btn_Stt 1;
BA_ "U_B562_MY18_Gas_Tx" SG_ 853 AC_Btn_Stt 1;
BA_ "U_C519_MY18_5_Gas_Tx" SG_ 853 AC_Btn_Stt 1;
BA_ "U_C519_MY18_5_Diesel_Tx" SG_ 853 AC_Btn_Stt 1;
BA_ "U_B515_MCA_MY17_Gas_Tx" SG_ 853 AC_Btn_Stt 1;
BA_ "U_B515_MCA_MY17_Diesel_Tx" SG_ 853 AC_Btn_Stt 1;
BA_ "U_B479_MY17_Diesel_Tx" SG_ 853 AC_Btn_Stt 1;
BA_ "U_B479_MY17_Gas_Tx" SG_ 853 AC_Btn_Stt 1;
BA_ "GenSigSendType" SG_ 853 AC_Btn_Stt 3;
BA_ "GenSigStartValue" SG_ 853 AC_Btn_Stt 2;
BA_ "GenSigStartValueInteger" SG_ 853 AC_Btn_Stt 2;
BA_ "CrossOver_InfoCAN" SG_ 853 AC_Btn_Stt 1;
BA_ "U_P702_MY2021_Tx" SG_ 853 Recirc_Btn_Stt 1;
BA_ "U_CX727_MY2021_Tx" SG_ 853 Recirc_Btn_Stt 1;
BA_ "U_CX430_MY2021_Tx" SG_ 853 Recirc_Btn_Stt 1;
BA_ "U_U611_U625_MY20_Phev_Tx" SG_ 853 Recirc_Btn_Stt 1;
BA_ "U_CX482_CX483_MY20_Tx" SG_ 853 Recirc_Btn_Stt 1;
BA_ "U_U611_U625_MY20_Hev_Tx" SG_ 853 Recirc_Btn_Stt 1;
BA_ "U_U611_U625_MY20_Gas_Tx" SG_ 853 Recirc_Btn_Stt 1;
BA_ "U_B500_MY18_Diesel_Tx" SG_ 853 Recirc_Btn_Stt 1;
BA_ "U_B500_MY18_Gas_Tx" SG_ 853 Recirc_Btn_Stt 1;
BA_ "U_C490_MY18_Tx" SG_ 853 Recirc_Btn_Stt 1;
BA_ "U_C519_MY18_5_Gas_Tx" SG_ 853 Recirc_Btn_Stt 1;
BA_ "U_C519_MY18_5_Diesel_Tx" SG_ 853 Recirc_Btn_Stt 1;
BA_ "U_B515_MCA_MY17_Gas_Tx" SG_ 853 Recirc_Btn_Stt 1;
BA_ "U_B515_MCA_MY17_Diesel_Tx" SG_ 853 Recirc_Btn_Stt 1;
BA_ "U_B479_MY17_Diesel_Tx" SG_ 853 Recirc_Btn_Stt 1;
BA_ "U_B479_MY17_Gas_Tx" SG_ 853 Recirc_Btn_Stt 1;
BA_ "U_CX727_MY2021_Rx" SG_ 853 Recirc_Btn_Stt 1;
BA_ "U_U611_U625_MY20_Phev_Rx" SG_ 853 Recirc_Btn_Stt 1;
BA_ "U_CX482_CX483_MY20_Rx" SG_ 853 Recirc_Btn_Stt 1;
BA_ "U_U611_U625_MY20_Hev_Rx" SG_ 853 Recirc_Btn_Stt 1;
BA_ "U_U611_U625_MY20_Gas_Rx" SG_ 853 Recirc_Btn_Stt 1;
BA_ "U_C519_MY18_5_Gas_Rx" SG_ 853 Recirc_Btn_Stt 1;
BA_ "U_C519_MY18_5_Diesel_Rx" SG_ 853 Recirc_Btn_Stt 1;
BA_ "GenSigSendType" SG_ 853 Recirc_Btn_Stt 3;
BA_ "GenSigStartValue" SG_ 853 Recirc_Btn_Stt 2;
BA_ "GenSigStartValueInteger" SG_ 853 Recirc_Btn_Stt 2;
BA_ "CrossOver_InfoCAN" SG_ 853 Recirc_Btn_Stt 1;
BA_ "U_P702_MY2021_Tx" SG_ 853 Rear_Defrost_Btn_Stt 1;
BA_ "U_CX727_MY2021_Tx" SG_ 853 Rear_Defrost_Btn_Stt 1;
BA_ "U_CX430_MY2021_Tx" SG_ 853 Rear_Defrost_Btn_Stt 1;
BA_ "U_U611_U625_MY20_Phev_Tx" SG_ 853 Rear_Defrost_Btn_Stt 1;
BA_ "U_B562_MY18_Diesel_Tx" SG_ 853 Rear_Defrost_Btn_Stt 1;
BA_ "U_CX482_CX483_MY20_Tx" SG_ 853 Rear_Defrost_Btn_Stt 1;
BA_ "U_U611_U625_MY20_Hev_Tx" SG_ 853 Rear_Defrost_Btn_Stt 1;
BA_ "U_U611_U625_MY20_Gas_Tx" SG_ 853 Rear_Defrost_Btn_Stt 1;
BA_ "U_B500_MY18_Diesel_Tx" SG_ 853 Rear_Defrost_Btn_Stt 1;
BA_ "U_B500_MY18_Gas_Tx" SG_ 853 Rear_Defrost_Btn_Stt 1;
BA_ "U_C490_MY18_Tx" SG_ 853 Rear_Defrost_Btn_Stt 1;
BA_ "U_B562_MY18_Gas_Tx" SG_ 853 Rear_Defrost_Btn_Stt 1;
BA_ "U_C519_MY18_5_Gas_Tx" SG_ 853 Rear_Defrost_Btn_Stt 1;
BA_ "U_C519_MY18_5_Diesel_Tx" SG_ 853 Rear_Defrost_Btn_Stt 1;
BA_ "U_B515_MCA_MY17_Gas_Tx" SG_ 853 Rear_Defrost_Btn_Stt 1;
BA_ "U_B515_MCA_MY17_Diesel_Tx" SG_ 853 Rear_Defrost_Btn_Stt 1;
BA_ "U_B479_MY17_Diesel_Tx" SG_ 853 Rear_Defrost_Btn_Stt 1;
BA_ "U_B479_MY17_Gas_Tx" SG_ 853 Rear_Defrost_Btn_Stt 1;
BA_ "GenSigSendType" SG_ 853 Rear_Defrost_Btn_Stt 3;
BA_ "GenSigStartValue" SG_ 853 Rear_Defrost_Btn_Stt 2;
BA_ "GenSigStartValueInteger" SG_ 853 Rear_Defrost_Btn_Stt 2;
BA_ "CrossOver_InfoCAN" SG_ 853 Rear_Defrost_Btn_Stt 1;
BA_ "U_P702_MY2021_Tx" SG_ 853 My_Temp_Btn_Stt 1;
BA_ "U_CX727_MY2021_Tx" SG_ 853 My_Temp_Btn_Stt 1;
BA_ "U_CX430_MY2021_Tx" SG_ 853 My_Temp_Btn_Stt 1;
BA_ "U_U611_U625_MY20_Phev_Tx" SG_ 853 My_Temp_Btn_Stt 1;
BA_ "U_B562_MY18_Diesel_Tx" SG_ 853 My_Temp_Btn_Stt 1;
BA_ "U_CX482_CX483_MY20_Tx" SG_ 853 My_Temp_Btn_Stt 1;
BA_ "U_U611_U625_MY20_Hev_Tx" SG_ 853 My_Temp_Btn_Stt 1;
BA_ "U_U611_U625_MY20_Gas_Tx" SG_ 853 My_Temp_Btn_Stt 1;
BA_ "U_B500_MY18_Diesel_Tx" SG_ 853 My_Temp_Btn_Stt 1;
BA_ "U_B500_MY18_Gas_Tx" SG_ 853 My_Temp_Btn_Stt 1;
BA_ "U_B562_MY18_Gas_Tx" SG_ 853 My_Temp_Btn_Stt 1;
BA_ "U_C519_MY18_5_Gas_Tx" SG_ 853 My_Temp_Btn_Stt 1;
BA_ "U_C519_MY18_5_Diesel_Tx" SG_ 853 My_Temp_Btn_Stt 1;
BA_ "U_B515_MCA_MY17_Gas_Tx" SG_ 853 My_Temp_Btn_Stt 1;
BA_ "U_B515_MCA_MY17_Diesel_Tx" SG_ 853 My_Temp_Btn_Stt 1;
BA_ "U_B479_MY17_Diesel_Tx" SG_ 853 My_Temp_Btn_Stt 1;
BA_ "U_B479_MY17_Gas_Tx" SG_ 853 My_Temp_Btn_Stt 1;
BA_ "GenSigSendType" SG_ 853 My_Temp_Btn_Stt 3;
BA_ "GenSigStartValue" SG_ 853 My_Temp_Btn_Stt 2;
BA_ "GenSigStartValueInteger" SG_ 853 My_Temp_Btn_Stt 2;
BA_ "CrossOver_InfoCAN" SG_ 853 My_Temp_Btn_Stt 1;
BA_ "U_P702_MY2021_Tx" SG_ 853 Max_Defrost_Btn_Stt 1;
BA_ "U_CX727_MY2021_Tx" SG_ 853 Max_Defrost_Btn_Stt 1;
BA_ "U_CX430_MY2021_Tx" SG_ 853 Max_Defrost_Btn_Stt 1;
BA_ "U_U611_U625_MY20_Phev_Tx" SG_ 853 Max_Defrost_Btn_Stt 1;
BA_ "U_B562_MY18_Diesel_Tx" SG_ 853 Max_Defrost_Btn_Stt 1;
BA_ "U_CX482_CX483_MY20_Tx" SG_ 853 Max_Defrost_Btn_Stt 1;
BA_ "U_U611_U625_MY20_Hev_Tx" SG_ 853 Max_Defrost_Btn_Stt 1;
BA_ "U_U611_U625_MY20_Gas_Tx" SG_ 853 Max_Defrost_Btn_Stt 1;
BA_ "U_B500_MY18_Diesel_Tx" SG_ 853 Max_Defrost_Btn_Stt 1;
BA_ "U_B500_MY18_Gas_Tx" SG_ 853 Max_Defrost_Btn_Stt 1;
BA_ "U_C490_MY18_Tx" SG_ 853 Max_Defrost_Btn_Stt 1;
BA_ "U_B562_MY18_Gas_Tx" SG_ 853 Max_Defrost_Btn_Stt 1;
BA_ "U_C519_MY18_5_Gas_Tx" SG_ 853 Max_Defrost_Btn_Stt 1;
BA_ "U_C519_MY18_5_Diesel_Tx" SG_ 853 Max_Defrost_Btn_Stt 1;
BA_ "U_B515_MCA_MY17_Gas_Tx" SG_ 853 Max_Defrost_Btn_Stt 1;
BA_ "U_B515_MCA_MY17_Diesel_Tx" SG_ 853 Max_Defrost_Btn_Stt 1;
BA_ "U_B479_MY17_Diesel_Tx" SG_ 853 Max_Defrost_Btn_Stt 1;
BA_ "U_B479_MY17_Gas_Tx" SG_ 853 Max_Defrost_Btn_Stt 1;
BA_ "GenSigSendType" SG_ 853 Max_Defrost_Btn_Stt 3;
BA_ "GenSigStartValue" SG_ 853 Max_Defrost_Btn_Stt 2;
BA_ "GenSigStartValueInteger" SG_ 853 Max_Defrost_Btn_Stt 2;
BA_ "CrossOver_InfoCAN" SG_ 853 Max_Defrost_Btn_Stt 1;
BA_ "U_P702_MY2021_Tx" SG_ 853 Max_AC_Btn_Stt 1;
BA_ "U_CX727_MY2021_Tx" SG_ 853 Max_AC_Btn_Stt 1;
BA_ "U_CX430_MY2021_Tx" SG_ 853 Max_AC_Btn_Stt 1;
BA_ "U_U611_U625_MY20_Phev_Tx" SG_ 853 Max_AC_Btn_Stt 1;
BA_ "U_B562_MY18_Diesel_Tx" SG_ 853 Max_AC_Btn_Stt 1;
BA_ "U_CX482_CX483_MY20_Tx" SG_ 853 Max_AC_Btn_Stt 1;
BA_ "U_U611_U625_MY20_Hev_Tx" SG_ 853 Max_AC_Btn_Stt 1;
BA_ "U_U611_U625_MY20_Gas_Tx" SG_ 853 Max_AC_Btn_Stt 1;
BA_ "U_B500_MY18_Diesel_Tx" SG_ 853 Max_AC_Btn_Stt 1;
BA_ "U_B500_MY18_Gas_Tx" SG_ 853 Max_AC_Btn_Stt 1;
BA_ "U_C490_MY18_Tx" SG_ 853 Max_AC_Btn_Stt 1;
BA_ "U_B562_MY18_Gas_Tx" SG_ 853 Max_AC_Btn_Stt 1;
BA_ "U_C519_MY18_5_Gas_Tx" SG_ 853 Max_AC_Btn_Stt 1;
BA_ "U_C519_MY18_5_Diesel_Tx" SG_ 853 Max_AC_Btn_Stt 1;
BA_ "U_B515_MCA_MY17_Gas_Tx" SG_ 853 Max_AC_Btn_Stt 1;
BA_ "U_B515_MCA_MY17_Diesel_Tx" SG_ 853 Max_AC_Btn_Stt 1;
BA_ "U_B479_MY17_Diesel_Tx" SG_ 853 Max_AC_Btn_Stt 1;
BA_ "U_B479_MY17_Gas_Tx" SG_ 853 Max_AC_Btn_Stt 1;
BA_ "GenSigSendType" SG_ 853 Max_AC_Btn_Stt 3;
BA_ "GenSigStartValue" SG_ 853 Max_AC_Btn_Stt 2;
BA_ "GenSigStartValueInteger" SG_ 853 Max_AC_Btn_Stt 2;
BA_ "CrossOver_InfoCAN" SG_ 853 Max_AC_Btn_Stt 1;
BA_ "U_P702_MY2021_Tx" SG_ 853 Front_AUTO_Label 1;
BA_ "U_CX727_MY2021_Tx" SG_ 853 Front_AUTO_Label 1;
BA_ "U_CX430_MY2021_Tx" SG_ 853 Front_AUTO_Label 1;
BA_ "U_U611_U625_MY20_Phev_Tx" SG_ 853 Front_AUTO_Label 1;
BA_ "U_CX482_CX483_MY20_Tx" SG_ 853 Front_AUTO_Label 1;
BA_ "U_U611_U625_MY20_Hev_Tx" SG_ 853 Front_AUTO_Label 1;
BA_ "U_U611_U625_MY20_Gas_Tx" SG_ 853 Front_AUTO_Label 1;
BA_ "U_B500_MY18_Diesel_Tx" SG_ 853 Front_AUTO_Label 1;
BA_ "U_B500_MY18_Gas_Tx" SG_ 853 Front_AUTO_Label 1;
BA_ "U_C519_MY18_5_Gas_Tx" SG_ 853 Front_AUTO_Label 1;
BA_ "U_C519_MY18_5_Diesel_Tx" SG_ 853 Front_AUTO_Label 1;
BA_ "U_B515_MCA_MY17_Gas_Tx" SG_ 853 Front_AUTO_Label 1;
BA_ "U_B515_MCA_MY17_Diesel_Tx" SG_ 853 Front_AUTO_Label 1;
BA_ "U_B479_MY17_Diesel_Tx" SG_ 853 Front_AUTO_Label 1;
BA_ "U_B479_MY17_Gas_Tx" SG_ 853 Front_AUTO_Label 1;
BA_ "GenSigSendType" SG_ 853 Front_AUTO_Label 3;
BA_ "GenSigStartValue" SG_ 853 Front_AUTO_Label 2;
BA_ "GenSigStartValueInteger" SG_ 853 Front_AUTO_Label 2;
BA_ "CrossOver_InfoCAN" SG_ 853 Front_AUTO_Label 1;
BA_ "GenSigSendType" SG_ 1034 VehicleGGCCData 3;
BA_ "U_B562_MY18_Diesel_Rx" SG_ 1034 VehicleGGCCData 1;
BA_ "U_B500_MY18_Diesel_Rx" SG_ 1034 VehicleGGCCData 1;
BA_ "U_B500_MY18_Gas_Rx" SG_ 1034 VehicleGGCCData 1;
BA_ "U_B562_MY18_Gas_Rx" SG_ 1034 VehicleGGCCData 1;
BA_ "U_VN127_MY20_Rx" SG_ 1034 VehicleGGCCData 1;
BA_ "U_H567_MY20_Rx" SG_ 1034 VehicleGGCCData 1;
BA_ "U_P702_MY2021_Rx" SG_ 1034 VehicleGGCCData 1;
BA_ "U_C490_MY18_Rx" SG_ 1034 VehicleGGCCData 1;
BA_ "U_B562LC_MY15_Diesel_Rx" SG_ 1034 VehicleGGCCData 1;
BA_ "U_CX727_MY2021_Rx" SG_ 1034 VehicleGGCCData 1;
BA_ "U_CX430_MY2021_Rx" SG_ 1034 VehicleGGCCData 1;
BA_ "U_U611_U625_MY20_Phev_Rx" SG_ 1034 VehicleGGCCData 1;
BA_ "U_CX482_CX483_MY20_Rx" SG_ 1034 VehicleGGCCData 1;
BA_ "U_U611_U625_MY20_Hev_Rx" SG_ 1034 VehicleGGCCData 1;
BA_ "U_U611_U625_MY20_Gas_Rx" SG_ 1034 VehicleGGCCData 1;
BA_ "U_C519_MY18_5_Gas_Rx" SG_ 1034 VehicleGGCCData 1;
BA_ "U_C519_MY18_5_Diesel_Rx" SG_ 1034 VehicleGGCCData 1;
BA_ "U_B515_MCA_MY17_Gas_Rx" SG_ 1034 VehicleGGCCData 1;
BA_ "U_B515_MCA_MY17_Diesel_Rx" SG_ 1034 VehicleGGCCData 1;
BA_ "U_B479_MY17_Diesel_Rx" SG_ 1034 VehicleGGCCData 1;
BA_ "U_B479_MY17_Gas_Rx" SG_ 1034 VehicleGGCCData 1;
BA_ "U_B562LC_MY15_Gas_Rx" SG_ 1034 VehicleGGCCData 1;
BA_ "CrossOver_InfoCAN" SG_ 1034 VehicleGGCCData 1;
BA_ "U_U611_U625_MY20_Phev_Rx" SG_ 956 SAPPStatusCoding 1;
BA_ "U_CX482_CX483_MY20_Rx" SG_ 956 SAPPStatusCoding 1;
BA_ "U_U611_U625_MY20_Hev_Rx" SG_ 956 SAPPStatusCoding 1;
BA_ "U_U611_U625_MY20_Gas_Rx" SG_ 956 SAPPStatusCoding 1;
BA_ "U_C519_MY18_5_Gas_Rx" SG_ 956 SAPPStatusCoding 1;
BA_ "U_C519_MY18_5_Diesel_Rx" SG_ 956 SAPPStatusCoding 1;
BA_ "U_B515_MCA_MY17_Gas_Rx" SG_ 956 SAPPStatusCoding 1;
BA_ "U_B515_MCA_MY17_Diesel_Rx" SG_ 956 SAPPStatusCoding 1;
BA_ "U_B479_MY17_Diesel_Rx" SG_ 956 SAPPStatusCoding 1;
BA_ "U_B479_MY17_Gas_Rx" SG_ 956 SAPPStatusCoding 1;
BA_ "U_B562LC_MY15_Gas_Rx" SG_ 956 SAPPStatusCoding 1;
BA_ "CrossOver_InfoCAN" SG_ 956 SAPPStatusCoding 1;
BA_ "GenSigSendType" SG_ 956 PwSrcULoFalt_D_Stat_UB 3;
BA_ "U_P702_MY2021_Rx" SG_ 956 PwSrcULoFalt_D_Stat_UB 1;
BA_ "U_CX727_MY2021_Rx" SG_ 956 PwSrcULoFalt_D_Stat_UB 1;
BA_ "U_CX430_MY2021_Rx" SG_ 956 PwSrcULoFalt_D_Stat_UB 1;
BA_ "U_U611_U625_MY20_Phev_Rx" SG_ 956 PwSrcULoFalt_D_Stat_UB 1;
BA_ "U_B562_MY18_Diesel_Rx" SG_ 956 PwSrcULoFalt_D_Stat_UB 1;
BA_ "U_CX482_CX483_MY20_Rx" SG_ 956 PwSrcULoFalt_D_Stat_UB 1;
BA_ "U_U611_U625_MY20_Hev_Rx" SG_ 956 PwSrcULoFalt_D_Stat_UB 1;
BA_ "U_U611_U625_MY20_Gas_Rx" SG_ 956 PwSrcULoFalt_D_Stat_UB 1;
BA_ "U_B500_MY18_Diesel_Rx" SG_ 956 PwSrcULoFalt_D_Stat_UB 1;
BA_ "U_B500_MY18_Gas_Rx" SG_ 956 PwSrcULoFalt_D_Stat_UB 1;
BA_ "U_C490_MY18_Rx" SG_ 956 PwSrcULoFalt_D_Stat_UB 1;
BA_ "U_B562_MY18_Gas_Rx" SG_ 956 PwSrcULoFalt_D_Stat_UB 1;
BA_ "U_C519_MY18_5_Gas_Rx" SG_ 956 PwSrcULoFalt_D_Stat_UB 1;
BA_ "U_C519_MY18_5_Diesel_Rx" SG_ 956 PwSrcULoFalt_D_Stat_UB 1;
BA_ "U_B515_MCA_MY17_Gas_Rx" SG_ 956 PwSrcULoFalt_D_Stat_UB 1;
BA_ "U_B515_MCA_MY17_Diesel_Rx" SG_ 956 PwSrcULoFalt_D_Stat_UB 1;
BA_ "U_B479_MY17_Diesel_Rx" SG_ 956 PwSrcULoFalt_D_Stat_UB 1;
BA_ "U_B479_MY17_Gas_Rx" SG_ 956 PwSrcULoFalt_D_Stat_UB 1;
BA_ "GenSigSendType" SG_ 956 PwSrcULo_Pc_Mx_UB 3;
BA_ "U_P702_MY2021_Rx" SG_ 956 PwSrcULo_Pc_Mx_UB 1;
BA_ "U_CX727_MY2021_Rx" SG_ 956 PwSrcULo_Pc_Mx_UB 1;
BA_ "U_CX430_MY2021_Rx" SG_ 956 PwSrcULo_Pc_Mx_UB 1;
BA_ "U_U611_U625_MY20_Phev_Rx" SG_ 956 PwSrcULo_Pc_Mx_UB 1;
BA_ "U_B562_MY18_Diesel_Rx" SG_ 956 PwSrcULo_Pc_Mx_UB 1;
BA_ "U_CX482_CX483_MY20_Rx" SG_ 956 PwSrcULo_Pc_Mx_UB 1;
BA_ "U_U611_U625_MY20_Hev_Rx" SG_ 956 PwSrcULo_Pc_Mx_UB 1;
BA_ "U_U611_U625_MY20_Gas_Rx" SG_ 956 PwSrcULo_Pc_Mx_UB 1;
BA_ "U_B500_MY18_Diesel_Rx" SG_ 956 PwSrcULo_Pc_Mx_UB 1;
BA_ "U_B500_MY18_Gas_Rx" SG_ 956 PwSrcULo_Pc_Mx_UB 1;
BA_ "U_C490_MY18_Rx" SG_ 956 PwSrcULo_Pc_Mx_UB 1;
BA_ "U_B562_MY18_Gas_Rx" SG_ 956 PwSrcULo_Pc_Mx_UB 1;
BA_ "U_C519_MY18_5_Gas_Rx" SG_ 956 PwSrcULo_Pc_Mx_UB 1;
BA_ "U_C519_MY18_5_Diesel_Rx" SG_ 956 PwSrcULo_Pc_Mx_UB 1;
BA_ "U_B515_MCA_MY17_Gas_Rx" SG_ 956 PwSrcULo_Pc_Mx_UB 1;
BA_ "U_B515_MCA_MY17_Diesel_Rx" SG_ 956 PwSrcULo_Pc_Mx_UB 1;
BA_ "U_B479_MY17_Diesel_Rx" SG_ 956 PwSrcULo_Pc_Mx_UB 1;
BA_ "U_B479_MY17_Gas_Rx" SG_ 956 PwSrcULo_Pc_Mx_UB 1;
BA_ "GenSigSendType" SG_ 956 PwSrcULo_Pc_Mx 3;
BA_ "U_P702_MY2021_Rx" SG_ 956 PwSrcULo_Pc_Mx 1;
BA_ "U_CX727_MY2021_Rx" SG_ 956 PwSrcULo_Pc_Mx 1;
BA_ "U_CX430_MY2021_Rx" SG_ 956 PwSrcULo_Pc_Mx 1;
BA_ "U_U611_U625_MY20_Phev_Rx" SG_ 956 PwSrcULo_Pc_Mx 1;
BA_ "U_B562_MY18_Diesel_Rx" SG_ 956 PwSrcULo_Pc_Mx 1;
BA_ "U_CX482_CX483_MY20_Rx" SG_ 956 PwSrcULo_Pc_Mx 1;
BA_ "U_U611_U625_MY20_Hev_Rx" SG_ 956 PwSrcULo_Pc_Mx 1;
BA_ "U_U611_U625_MY20_Gas_Rx" SG_ 956 PwSrcULo_Pc_Mx 1;
BA_ "U_B500_MY18_Diesel_Rx" SG_ 956 PwSrcULo_Pc_Mx 1;
BA_ "U_B500_MY18_Gas_Rx" SG_ 956 PwSrcULo_Pc_Mx 1;
BA_ "U_C490_MY18_Rx" SG_ 956 PwSrcULo_Pc_Mx 1;
BA_ "U_B562_MY18_Gas_Rx" SG_ 956 PwSrcULo_Pc_Mx 1;
BA_ "U_C519_MY18_5_Gas_Rx" SG_ 956 PwSrcULo_Pc_Mx 1;
BA_ "U_C519_MY18_5_Diesel_Rx" SG_ 956 PwSrcULo_Pc_Mx 1;
BA_ "U_B515_MCA_MY17_Gas_Rx" SG_ 956 PwSrcULo_Pc_Mx 1;
BA_ "U_B515_MCA_MY17_Diesel_Rx" SG_ 956 PwSrcULo_Pc_Mx 1;
BA_ "U_B479_MY17_Diesel_Rx" SG_ 956 PwSrcULo_Pc_Mx 1;
BA_ "U_B479_MY17_Gas_Rx" SG_ 956 PwSrcULo_Pc_Mx 1;
BA_ "GenSigSendType" SG_ 956 WndwFrontHeat_B_Rq_UB 3;
BA_ "U_CX727_MY2021_Rx" SG_ 956 WndwFrontHeat_B_Rq_UB 1;
BA_ "U_CX430_MY2021_Rx" SG_ 956 WndwFrontHeat_B_Rq_UB 1;
BA_ "U_U611_U625_MY20_Phev_Rx" SG_ 956 WndwFrontHeat_B_Rq_UB 1;
BA_ "U_B562_MY18_Diesel_Rx" SG_ 956 WndwFrontHeat_B_Rq_UB 1;
BA_ "U_CX482_CX483_MY20_Rx" SG_ 956 WndwFrontHeat_B_Rq_UB 1;
BA_ "U_U611_U625_MY20_Hev_Rx" SG_ 956 WndwFrontHeat_B_Rq_UB 1;
BA_ "U_U611_U625_MY20_Gas_Rx" SG_ 956 WndwFrontHeat_B_Rq_UB 1;
BA_ "U_B500_MY18_Diesel_Rx" SG_ 956 WndwFrontHeat_B_Rq_UB 1;
BA_ "U_B500_MY18_Gas_Rx" SG_ 956 WndwFrontHeat_B_Rq_UB 1;
BA_ "U_B562_MY18_Gas_Rx" SG_ 956 WndwFrontHeat_B_Rq_UB 1;
BA_ "U_C519_MY18_5_Gas_Rx" SG_ 956 WndwFrontHeat_B_Rq_UB 1;
BA_ "U_C519_MY18_5_Diesel_Rx" SG_ 956 WndwFrontHeat_B_Rq_UB 1;
BA_ "U_B515_MCA_MY17_Gas_Rx" SG_ 956 WndwFrontHeat_B_Rq_UB 1;
BA_ "U_B515_MCA_MY17_Diesel_Rx" SG_ 956 WndwFrontHeat_B_Rq_UB 1;
BA_ "U_B479_MY17_Diesel_Rx" SG_ 956 WndwFrontHeat_B_Rq_UB 1;
BA_ "U_B479_MY17_Gas_Rx" SG_ 956 WndwFrontHeat_B_Rq_UB 1;
BA_ "U_B515_MCA_MY17_Gas_Rx" SG_ 956 SAPPStatusCoding_UB 1;
BA_ "U_B515_MCA_MY17_Diesel_Rx" SG_ 956 SAPPStatusCoding_UB 1;
BA_ "U_U611_U625_MY20_Phev_Rx" SG_ 956 SAPPStatusCoding_UB 1;
BA_ "U_CX482_CX483_MY20_Rx" SG_ 956 SAPPStatusCoding_UB 1;
BA_ "U_U611_U625_MY20_Hev_Rx" SG_ 956 SAPPStatusCoding_UB 1;
BA_ "U_U611_U625_MY20_Gas_Rx" SG_ 956 SAPPStatusCoding_UB 1;
BA_ "U_C519_MY18_5_Gas_Rx" SG_ 956 SAPPStatusCoding_UB 1;
BA_ "U_C519_MY18_5_Diesel_Rx" SG_ 956 SAPPStatusCoding_UB 1;
BA_ "U_B479_MY17_Diesel_Rx" SG_ 956 SAPPStatusCoding_UB 1;
BA_ "U_B479_MY17_Gas_Rx" SG_ 956 SAPPStatusCoding_UB 1;
BA_ "U_B562LC_MY15_Gas_Rx" SG_ 956 SAPPStatusCoding_UB 1;
BA_ "CrossOver_InfoCAN" SG_ 956 SAPPStatusCoding_UB 1;
BA_ "GenSigSendType" SG_ 956 WndwFrontHeat_B_Rq 3;
BA_ "U_CX727_MY2021_Rx" SG_ 956 WndwFrontHeat_B_Rq 1;
BA_ "U_CX430_MY2021_Rx" SG_ 956 WndwFrontHeat_B_Rq 1;
BA_ "U_U611_U625_MY20_Phev_Rx" SG_ 956 WndwFrontHeat_B_Rq 1;
BA_ "U_B562_MY18_Diesel_Rx" SG_ 956 WndwFrontHeat_B_Rq 1;
BA_ "U_CX482_CX483_MY20_Rx" SG_ 956 WndwFrontHeat_B_Rq 1;
BA_ "U_U611_U625_MY20_Hev_Rx" SG_ 956 WndwFrontHeat_B_Rq 1;
BA_ "U_U611_U625_MY20_Gas_Rx" SG_ 956 WndwFrontHeat_B_Rq 1;
BA_ "U_B500_MY18_Diesel_Rx" SG_ 956 WndwFrontHeat_B_Rq 1;
BA_ "U_B500_MY18_Gas_Rx" SG_ 956 WndwFrontHeat_B_Rq 1;
BA_ "U_B562_MY18_Gas_Rx" SG_ 956 WndwFrontHeat_B_Rq 1;
BA_ "U_C519_MY18_5_Gas_Rx" SG_ 956 WndwFrontHeat_B_Rq 1;
BA_ "U_C519_MY18_5_Diesel_Rx" SG_ 956 WndwFrontHeat_B_Rq 1;
BA_ "U_B515_MCA_MY17_Gas_Rx" SG_ 956 WndwFrontHeat_B_Rq 1;
BA_ "U_B515_MCA_MY17_Diesel_Rx" SG_ 956 WndwFrontHeat_B_Rq 1;
BA_ "U_B479_MY17_Diesel_Rx" SG_ 956 WndwFrontHeat_B_Rq 1;
BA_ "U_B479_MY17_Gas_Rx" SG_ 956 WndwFrontHeat_B_Rq 1;
BA_ "CrossOver_InfoCAN" SG_ 956 WndwFrontHeat_B_Rq 1;
BA_ "GenSigSendType" SG_ 956 BattTrac_Te_Actl_UB 3;
BA_ "U_CX727_MY2021_Rx" SG_ 956 BattTrac_Te_Actl_UB 1;
BA_ "U_CX430_MY2021_Rx" SG_ 956 BattTrac_Te_Actl_UB 1;
BA_ "U_U611_U625_MY20_Phev_Rx" SG_ 956 BattTrac_Te_Actl_UB 1;
BA_ "U_B562_MY18_Diesel_Rx" SG_ 956 BattTrac_Te_Actl_UB 1;
BA_ "U_CX482_CX483_MY20_Rx" SG_ 956 BattTrac_Te_Actl_UB 1;
BA_ "U_U611_U625_MY20_Hev_Rx" SG_ 956 BattTrac_Te_Actl_UB 1;
BA_ "U_U611_U625_MY20_Gas_Rx" SG_ 956 BattTrac_Te_Actl_UB 1;
BA_ "U_B500_MY18_Diesel_Rx" SG_ 956 BattTrac_Te_Actl_UB 1;
BA_ "U_B500_MY18_Gas_Rx" SG_ 956 BattTrac_Te_Actl_UB 1;
BA_ "U_B562_MY18_Gas_Rx" SG_ 956 BattTrac_Te_Actl_UB 1;
BA_ "U_C519_MY18_5_Gas_Rx" SG_ 956 BattTrac_Te_Actl_UB 1;
BA_ "U_C519_MY18_5_Diesel_Rx" SG_ 956 BattTrac_Te_Actl_UB 1;
BA_ "U_B515_MCA_MY17_Gas_Rx" SG_ 956 BattTrac_Te_Actl_UB 1;
BA_ "U_B515_MCA_MY17_Diesel_Rx" SG_ 956 BattTrac_Te_Actl_UB 1;
BA_ "U_B479_MY17_Diesel_Rx" SG_ 956 BattTrac_Te_Actl_UB 1;
BA_ "U_B479_MY17_Gas_Rx" SG_ 956 BattTrac_Te_Actl_UB 1;
BA_ "GenSigSendType" SG_ 956 BattTrac_Te_Actl 3;
BA_ "U_CX727_MY2021_Rx" SG_ 956 BattTrac_Te_Actl 1;
BA_ "U_CX430_MY2021_Rx" SG_ 956 BattTrac_Te_Actl 1;
BA_ "U_U611_U625_MY20_Phev_Rx" SG_ 956 BattTrac_Te_Actl 1;
BA_ "U_B562_MY18_Diesel_Rx" SG_ 956 BattTrac_Te_Actl 1;
BA_ "U_CX482_CX483_MY20_Rx" SG_ 956 BattTrac_Te_Actl 1;
BA_ "U_U611_U625_MY20_Hev_Rx" SG_ 956 BattTrac_Te_Actl 1;
BA_ "U_U611_U625_MY20_Gas_Rx" SG_ 956 BattTrac_Te_Actl 1;
BA_ "U_B500_MY18_Diesel_Rx" SG_ 956 BattTrac_Te_Actl 1;
BA_ "U_B500_MY18_Gas_Rx" SG_ 956 BattTrac_Te_Actl 1;
BA_ "U_B562_MY18_Gas_Rx" SG_ 956 BattTrac_Te_Actl 1;
BA_ "U_C519_MY18_5_Gas_Rx" SG_ 956 BattTrac_Te_Actl 1;
BA_ "U_C519_MY18_5_Diesel_Rx" SG_ 956 BattTrac_Te_Actl 1;
BA_ "U_B515_MCA_MY17_Gas_Rx" SG_ 956 BattTrac_Te_Actl 1;
BA_ "U_B515_MCA_MY17_Diesel_Rx" SG_ 956 BattTrac_Te_Actl 1;
BA_ "U_B479_MY17_Diesel_Rx" SG_ 956 BattTrac_Te_Actl 1;
BA_ "U_B479_MY17_Gas_Rx" SG_ 956 BattTrac_Te_Actl 1;
BA_ "GenSigStartValue" SG_ 956 BattTrac_Te_Actl 150;
BA_ "GenSigStartValueInteger" SG_ 956 BattTrac_Te_Actl 150;
BA_ "GenSigSendType" SG_ 956 PwSrcULoFalt_D_Stat 3;
BA_ "U_P702_MY2021_Rx" SG_ 956 PwSrcULoFalt_D_Stat 1;
BA_ "U_CX727_MY2021_Rx" SG_ 956 PwSrcULoFalt_D_Stat 1;
BA_ "U_CX430_MY2021_Rx" SG_ 956 PwSrcULoFalt_D_Stat 1;
BA_ "U_U611_U625_MY20_Phev_Rx" SG_ 956 PwSrcULoFalt_D_Stat 1;
BA_ "U_B562_MY18_Diesel_Rx" SG_ 956 PwSrcULoFalt_D_Stat 1;
BA_ "U_CX482_CX483_MY20_Rx" SG_ 956 PwSrcULoFalt_D_Stat 1;
BA_ "U_U611_U625_MY20_Hev_Rx" SG_ 956 PwSrcULoFalt_D_Stat 1;
BA_ "U_U611_U625_MY20_Gas_Rx" SG_ 956 PwSrcULoFalt_D_Stat 1;
BA_ "U_B500_MY18_Diesel_Rx" SG_ 956 PwSrcULoFalt_D_Stat 1;
BA_ "U_B500_MY18_Gas_Rx" SG_ 956 PwSrcULoFalt_D_Stat 1;
BA_ "U_C490_MY18_Rx" SG_ 956 PwSrcULoFalt_D_Stat 1;
BA_ "U_B562_MY18_Gas_Rx" SG_ 956 PwSrcULoFalt_D_Stat 1;
BA_ "U_C519_MY18_5_Gas_Rx" SG_ 956 PwSrcULoFalt_D_Stat 1;
BA_ "U_C519_MY18_5_Diesel_Rx" SG_ 956 PwSrcULoFalt_D_Stat 1;
BA_ "U_B515_MCA_MY17_Gas_Rx" SG_ 956 PwSrcULoFalt_D_Stat 1;
BA_ "U_B515_MCA_MY17_Diesel_Rx" SG_ 956 PwSrcULoFalt_D_Stat 1;
BA_ "U_B479_MY17_Diesel_Rx" SG_ 956 PwSrcULoFalt_D_Stat 1;
BA_ "U_B479_MY17_Gas_Rx" SG_ 956 PwSrcULoFalt_D_Stat 1;
BA_ "GenSigSendType" SG_ 956 PrkBrkStatus_UB 3;
BA_ "U_B500_MY18_Diesel_Rx" SG_ 956 PrkBrkStatus_UB 1;
BA_ "U_B500_MY18_Gas_Rx" SG_ 956 PrkBrkStatus_UB 1;
BA_ "U_C519_MY18_5_Gas_Rx" SG_ 956 PrkBrkStatus_UB 1;
BA_ "U_C519_MY18_5_Diesel_Rx" SG_ 956 PrkBrkStatus_UB 1;
BA_ "U_B515_MCA_MY17_Gas_Rx" SG_ 956 PrkBrkStatus_UB 1;
BA_ "U_B515_MCA_MY17_Diesel_Rx" SG_ 956 PrkBrkStatus_UB 1;
BA_ "U_B479_MY17_Diesel_Rx" SG_ 956 PrkBrkStatus_UB 1;
BA_ "U_B479_MY17_Gas_Rx" SG_ 956 PrkBrkStatus_UB 1;
BA_ "U_CX727_MY2021_Rx" SG_ 956 PrkBrkStatus_UB 1;
BA_ "U_CX430_MY2021_Rx" SG_ 956 PrkBrkStatus_UB 1;
BA_ "U_U611_U625_MY20_Phev_Rx" SG_ 956 PrkBrkStatus_UB 1;
BA_ "U_CX482_CX483_MY20_Rx" SG_ 956 PrkBrkStatus_UB 1;
BA_ "U_U611_U625_MY20_Hev_Rx" SG_ 956 PrkBrkStatus_UB 1;
BA_ "U_U611_U625_MY20_Gas_Rx" SG_ 956 PrkBrkStatus_UB 1;
BA_ "U_B562LC_MY15_Gas_Rx" SG_ 956 PrkBrkStatus_UB 1;
BA_ "GenSigSendType" SG_ 956 ApedPos_Pc_ActlArb 3;
BA_ "U_P702_MY2021_Rx" SG_ 956 ApedPos_Pc_ActlArb 1;
BA_ "U_CX727_MY2021_Rx" SG_ 956 ApedPos_Pc_ActlArb 1;
BA_ "U_CX430_MY2021_Rx" SG_ 956 ApedPos_Pc_ActlArb 1;
BA_ "U_U611_U625_MY20_Phev_Rx" SG_ 956 ApedPos_Pc_ActlArb 1;
BA_ "U_B562_MY18_Diesel_Rx" SG_ 956 ApedPos_Pc_ActlArb 1;
BA_ "U_CX482_CX483_MY20_Rx" SG_ 956 ApedPos_Pc_ActlArb 1;
BA_ "U_U611_U625_MY20_Hev_Rx" SG_ 956 ApedPos_Pc_ActlArb 1;
BA_ "U_U611_U625_MY20_Gas_Rx" SG_ 956 ApedPos_Pc_ActlArb 1;
BA_ "U_B500_MY18_Diesel_Rx" SG_ 956 ApedPos_Pc_ActlArb 1;
BA_ "U_B500_MY18_Gas_Rx" SG_ 956 ApedPos_Pc_ActlArb 1;
BA_ "U_C490_MY18_Rx" SG_ 956 ApedPos_Pc_ActlArb 1;
BA_ "U_B562_MY18_Gas_Rx" SG_ 956 ApedPos_Pc_ActlArb 1;
BA_ "U_C519_MY18_5_Gas_Rx" SG_ 956 ApedPos_Pc_ActlArb 1;
BA_ "U_C519_MY18_5_Diesel_Rx" SG_ 956 ApedPos_Pc_ActlArb 1;
BA_ "U_B515_MCA_MY17_Gas_Rx" SG_ 956 ApedPos_Pc_ActlArb 1;
BA_ "U_B515_MCA_MY17_Diesel_Rx" SG_ 956 ApedPos_Pc_ActlArb 1;
BA_ "U_B479_MY17_Diesel_Rx" SG_ 956 ApedPos_Pc_ActlArb 1;
BA_ "U_B479_MY17_Gas_Rx" SG_ 956 ApedPos_Pc_ActlArb 1;
BA_ "CrossOver_InfoCAN" SG_ 956 ApedPos_Pc_ActlArb 1;
BA_ "GenSigSendType" SG_ 956 ApedPos_Pc_ActlArb_UB 3;
BA_ "U_P702_MY2021_Rx" SG_ 956 ApedPos_Pc_ActlArb_UB 1;
BA_ "U_CX727_MY2021_Rx" SG_ 956 ApedPos_Pc_ActlArb_UB 1;
BA_ "U_CX430_MY2021_Rx" SG_ 956 ApedPos_Pc_ActlArb_UB 1;
BA_ "U_U611_U625_MY20_Phev_Rx" SG_ 956 ApedPos_Pc_ActlArb_UB 1;
BA_ "U_B562_MY18_Diesel_Rx" SG_ 956 ApedPos_Pc_ActlArb_UB 1;
BA_ "U_CX482_CX483_MY20_Rx" SG_ 956 ApedPos_Pc_ActlArb_UB 1;
BA_ "U_U611_U625_MY20_Hev_Rx" SG_ 956 ApedPos_Pc_ActlArb_UB 1;
BA_ "U_U611_U625_MY20_Gas_Rx" SG_ 956 ApedPos_Pc_ActlArb_UB 1;
BA_ "U_B500_MY18_Diesel_Rx" SG_ 956 ApedPos_Pc_ActlArb_UB 1;
BA_ "U_B500_MY18_Gas_Rx" SG_ 956 ApedPos_Pc_ActlArb_UB 1;
BA_ "U_C490_MY18_Rx" SG_ 956 ApedPos_Pc_ActlArb_UB 1;
BA_ "U_B562_MY18_Gas_Rx" SG_ 956 ApedPos_Pc_ActlArb_UB 1;
BA_ "U_C519_MY18_5_Gas_Rx" SG_ 956 ApedPos_Pc_ActlArb_UB 1;
BA_ "U_C519_MY18_5_Diesel_Rx" SG_ 956 ApedPos_Pc_ActlArb_UB 1;
BA_ "U_B515_MCA_MY17_Gas_Rx" SG_ 956 ApedPos_Pc_ActlArb_UB 1;
BA_ "U_B515_MCA_MY17_Diesel_Rx" SG_ 956 ApedPos_Pc_ActlArb_UB 1;
BA_ "U_B479_MY17_Diesel_Rx" SG_ 956 ApedPos_Pc_ActlArb_UB 1;
BA_ "U_B479_MY17_Gas_Rx" SG_ 956 ApedPos_Pc_ActlArb_UB 1;
BA_ "GenSigSendType" SG_ 956 GearLvrPos_D_Actl 3;
BA_ "U_B500_MY18_Diesel_Rx" SG_ 956 GearLvrPos_D_Actl 1;
BA_ "U_B500_MY18_Gas_Rx" SG_ 956 GearLvrPos_D_Actl 1;
BA_ "U_B562LC_MY15_Diesel_Rx" SG_ 956 GearLvrPos_D_Actl 1;
BA_ "U_P702_MY2021_Rx" SG_ 956 GearLvrPos_D_Actl 1;
BA_ "U_CX727_MY2021_Rx" SG_ 956 GearLvrPos_D_Actl 1;
BA_ "U_CX430_MY2021_Rx" SG_ 956 GearLvrPos_D_Actl 1;
BA_ "U_U611_U625_MY20_Phev_Rx" SG_ 956 GearLvrPos_D_Actl 1;
BA_ "U_CX482_CX483_MY20_Rx" SG_ 956 GearLvrPos_D_Actl 1;
BA_ "U_U611_U625_MY20_Hev_Rx" SG_ 956 GearLvrPos_D_Actl 1;
BA_ "U_U611_U625_MY20_Gas_Rx" SG_ 956 GearLvrPos_D_Actl 1;
BA_ "U_C519_MY18_5_Gas_Rx" SG_ 956 GearLvrPos_D_Actl 1;
BA_ "U_C519_MY18_5_Diesel_Rx" SG_ 956 GearLvrPos_D_Actl 1;
BA_ "U_B515_MCA_MY17_Gas_Rx" SG_ 956 GearLvrPos_D_Actl 1;
BA_ "U_B515_MCA_MY17_Diesel_Rx" SG_ 956 GearLvrPos_D_Actl 1;
BA_ "U_B479_MY17_Diesel_Rx" SG_ 956 GearLvrPos_D_Actl 1;
BA_ "U_B479_MY17_Gas_Rx" SG_ 956 GearLvrPos_D_Actl 1;
BA_ "U_B562LC_MY15_Gas_Rx" SG_ 956 GearLvrPos_D_Actl 1;
BA_ "GenSigStartValue" SG_ 956 GearLvrPos_D_Actl 14;
BA_ "GenSigStartValueInteger" SG_ 956 GearLvrPos_D_Actl 14;
BA_ "CrossOver_InfoCAN" SG_ 956 GearLvrPos_D_Actl 1;
BA_ "GenSigSendType" SG_ 956 PrkBrkStatus 3;
BA_ "U_B500_MY18_Diesel_Rx" SG_ 956 PrkBrkStatus 1;
BA_ "U_B500_MY18_Gas_Rx" SG_ 956 PrkBrkStatus 1;
BA_ "U_C519_MY18_5_Gas_Rx" SG_ 956 PrkBrkStatus 1;
BA_ "U_C519_MY18_5_Diesel_Rx" SG_ 956 PrkBrkStatus 1;
BA_ "U_B515_MCA_MY17_Gas_Rx" SG_ 956 PrkBrkStatus 1;
BA_ "U_B515_MCA_MY17_Diesel_Rx" SG_ 956 PrkBrkStatus 1;
BA_ "U_B479_MY17_Diesel_Rx" SG_ 956 PrkBrkStatus 1;
BA_ "U_B479_MY17_Gas_Rx" SG_ 956 PrkBrkStatus 1;
BA_ "U_CX727_MY2021_Rx" SG_ 956 PrkBrkStatus 1;
BA_ "U_CX430_MY2021_Rx" SG_ 956 PrkBrkStatus 1;
BA_ "U_U611_U625_MY20_Phev_Rx" SG_ 956 PrkBrkStatus 1;
BA_ "U_CX482_CX483_MY20_Rx" SG_ 956 PrkBrkStatus 1;
BA_ "U_U611_U625_MY20_Hev_Rx" SG_ 956 PrkBrkStatus 1;
BA_ "U_U611_U625_MY20_Gas_Rx" SG_ 956 PrkBrkStatus 1;
BA_ "U_B562LC_MY15_Gas_Rx" SG_ 956 PrkBrkStatus 1;
BA_ "GenSigStartValue" SG_ 956 PrkBrkStatus 7;
BA_ "GenSigStartValueInteger" SG_ 956 PrkBrkStatus 7;
BA_ "CrossOver_InfoCAN" SG_ 956 PrkBrkStatus 1;
BA_ "GenSigSendType" SG_ 956 GearLvrPos_D_Actl_UB 3;
BA_ "U_B500_MY18_Diesel_Rx" SG_ 956 GearLvrPos_D_Actl_UB 1;
BA_ "U_B500_MY18_Gas_Rx" SG_ 956 GearLvrPos_D_Actl_UB 1;
BA_ "U_B562LC_MY15_Diesel_Rx" SG_ 956 GearLvrPos_D_Actl_UB 1;
BA_ "U_P702_MY2021_Rx" SG_ 956 GearLvrPos_D_Actl_UB 1;
BA_ "U_CX727_MY2021_Rx" SG_ 956 GearLvrPos_D_Actl_UB 1;
BA_ "U_CX430_MY2021_Rx" SG_ 956 GearLvrPos_D_Actl_UB 1;
BA_ "U_U611_U625_MY20_Phev_Rx" SG_ 956 GearLvrPos_D_Actl_UB 1;
BA_ "U_CX482_CX483_MY20_Rx" SG_ 956 GearLvrPos_D_Actl_UB 1;
BA_ "U_U611_U625_MY20_Hev_Rx" SG_ 956 GearLvrPos_D_Actl_UB 1;
BA_ "U_U611_U625_MY20_Gas_Rx" SG_ 956 GearLvrPos_D_Actl_UB 1;
BA_ "U_C519_MY18_5_Gas_Rx" SG_ 956 GearLvrPos_D_Actl_UB 1;
BA_ "U_C519_MY18_5_Diesel_Rx" SG_ 956 GearLvrPos_D_Actl_UB 1;
BA_ "U_B515_MCA_MY17_Gas_Rx" SG_ 956 GearLvrPos_D_Actl_UB 1;
BA_ "U_B515_MCA_MY17_Diesel_Rx" SG_ 956 GearLvrPos_D_Actl_UB 1;
BA_ "U_B479_MY17_Diesel_Rx" SG_ 956 GearLvrPos_D_Actl_UB 1;
BA_ "U_B479_MY17_Gas_Rx" SG_ 956 GearLvrPos_D_Actl_UB 1;
BA_ "U_B562LC_MY15_Gas_Rx" SG_ 956 GearLvrPos_D_Actl_UB 1;
BA_ "CrossOver_InfoCAN" SG_ 956 GearLvrPos_D_Actl_UB 1;
BA_ "U_P702_MY2021_Tx" SG_ 831 RearPassWindowLockCmd 1;
BA_ "U_CX727_MY2021_Tx" SG_ 831 RearPassWindowLockCmd 1;
BA_ "U_CX430_MY2021_Tx" SG_ 831 RearPassWindowLockCmd 1;
BA_ "U_U611_U625_MY20_Phev_Tx" SG_ 831 RearPassWindowLockCmd 1;
BA_ "U_CX482_CX483_MY20_Tx" SG_ 831 RearPassWindowLockCmd 1;
BA_ "U_U611_U625_MY20_Hev_Tx" SG_ 831 RearPassWindowLockCmd 1;
BA_ "U_U611_U625_MY20_Gas_Tx" SG_ 831 RearPassWindowLockCmd 1;
BA_ "U_C490_MY18_Tx" SG_ 831 RearPassWindowLockCmd 1;
BA_ "U_C519_MY18_5_Gas_Tx" SG_ 831 RearPassWindowLockCmd 1;
BA_ "U_C519_MY18_5_Diesel_Tx" SG_ 831 RearPassWindowLockCmd 1;
BA_ "U_B515_MCA_MY17_Gas_Tx" SG_ 831 RearPassWindowLockCmd 1;
BA_ "U_B515_MCA_MY17_Diesel_Tx" SG_ 831 RearPassWindowLockCmd 1;
BA_ "U_B479_MY17_Diesel_Tx" SG_ 831 RearPassWindowLockCmd 1;
BA_ "U_B479_MY17_Gas_Tx" SG_ 831 RearPassWindowLockCmd 1;
BA_ "U_P702_MY2021_Rx" SG_ 831 RearPassWindowLockCmd 1;
BA_ "U_CX430_MY2021_Rx" SG_ 831 RearPassWindowLockCmd 1;
BA_ "U_U611_U625_MY20_Phev_Rx" SG_ 831 RearPassWindowLockCmd 1;
BA_ "U_CX482_CX483_MY20_Rx" SG_ 831 RearPassWindowLockCmd 1;
BA_ "U_U611_U625_MY20_Hev_Rx" SG_ 831 RearPassWindowLockCmd 1;
BA_ "U_U611_U625_MY20_Gas_Rx" SG_ 831 RearPassWindowLockCmd 1;
BA_ "U_C490_MY18_Rx" SG_ 831 RearPassWindowLockCmd 1;
BA_ "U_C519_MY18_5_Gas_Rx" SG_ 831 RearPassWindowLockCmd 1;
BA_ "U_C519_MY18_5_Diesel_Rx" SG_ 831 RearPassWindowLockCmd 1;
BA_ "U_B515_MCA_MY17_Gas_Rx" SG_ 831 RearPassWindowLockCmd 1;
BA_ "U_B515_MCA_MY17_Diesel_Rx" SG_ 831 RearPassWindowLockCmd 1;
BA_ "U_B479_MY17_Diesel_Rx" SG_ 831 RearPassWindowLockCmd 1;
BA_ "U_B479_MY17_Gas_Rx" SG_ 831 RearPassWindowLockCmd 1;
BA_ "GenSigSendType" SG_ 831 RearPassWindowLockCmd 3;
BA_ "U_P702_MY2021_Tx" SG_ 831 RearPassWindowCmd 1;
BA_ "U_CX727_MY2021_Tx" SG_ 831 RearPassWindowCmd 1;
BA_ "U_CX430_MY2021_Tx" SG_ 831 RearPassWindowCmd 1;
BA_ "U_U611_U625_MY20_Phev_Tx" SG_ 831 RearPassWindowCmd 1;
BA_ "U_CX482_CX483_MY20_Tx" SG_ 831 RearPassWindowCmd 1;
BA_ "U_U611_U625_MY20_Hev_Tx" SG_ 831 RearPassWindowCmd 1;
BA_ "U_U611_U625_MY20_Gas_Tx" SG_ 831 RearPassWindowCmd 1;
BA_ "U_C490_MY18_Tx" SG_ 831 RearPassWindowCmd 1;
BA_ "U_C519_MY18_5_Gas_Tx" SG_ 831 RearPassWindowCmd 1;
BA_ "U_C519_MY18_5_Diesel_Tx" SG_ 831 RearPassWindowCmd 1;
BA_ "U_B515_MCA_MY17_Gas_Tx" SG_ 831 RearPassWindowCmd 1;
BA_ "U_B515_MCA_MY17_Diesel_Tx" SG_ 831 RearPassWindowCmd 1;
BA_ "U_B479_MY17_Diesel_Tx" SG_ 831 RearPassWindowCmd 1;
BA_ "U_B479_MY17_Gas_Tx" SG_ 831 RearPassWindowCmd 1;
BA_ "U_P702_MY2021_Rx" SG_ 831 RearPassWindowCmd 1;
BA_ "U_CX430_MY2021_Rx" SG_ 831 RearPassWindowCmd 1;
BA_ "U_U611_U625_MY20_Phev_Rx" SG_ 831 RearPassWindowCmd 1;
BA_ "U_CX482_CX483_MY20_Rx" SG_ 831 RearPassWindowCmd 1;
BA_ "U_U611_U625_MY20_Hev_Rx" SG_ 831 RearPassWindowCmd 1;
BA_ "U_U611_U625_MY20_Gas_Rx" SG_ 831 RearPassWindowCmd 1;
BA_ "U_C490_MY18_Rx" SG_ 831 RearPassWindowCmd 1;
BA_ "U_C519_MY18_5_Gas_Rx" SG_ 831 RearPassWindowCmd 1;
BA_ "U_C519_MY18_5_Diesel_Rx" SG_ 831 RearPassWindowCmd 1;
BA_ "U_B515_MCA_MY17_Gas_Rx" SG_ 831 RearPassWindowCmd 1;
BA_ "U_B515_MCA_MY17_Diesel_Rx" SG_ 831 RearPassWindowCmd 1;
BA_ "U_B479_MY17_Diesel_Rx" SG_ 831 RearPassWindowCmd 1;
BA_ "U_B479_MY17_Gas_Rx" SG_ 831 RearPassWindowCmd 1;
BA_ "GenSigSendType" SG_ 831 RearPassWindowCmd 3;
BA_ "WakeupSignal" SG_ 831 RearPassWindowCmd 1;
BA_ "U_P702_MY2021_Tx" SG_ 831 PassWindowCmd 1;
BA_ "U_CX727_MY2021_Tx" SG_ 831 PassWindowCmd 1;
BA_ "U_CX430_MY2021_Tx" SG_ 831 PassWindowCmd 1;
BA_ "U_U611_U625_MY20_Phev_Tx" SG_ 831 PassWindowCmd 1;
BA_ "U_CX482_CX483_MY20_Tx" SG_ 831 PassWindowCmd 1;
BA_ "U_U611_U625_MY20_Hev_Tx" SG_ 831 PassWindowCmd 1;
BA_ "U_U611_U625_MY20_Gas_Tx" SG_ 831 PassWindowCmd 1;
BA_ "U_C490_MY18_Tx" SG_ 831 PassWindowCmd 1;
BA_ "U_C519_MY18_5_Gas_Tx" SG_ 831 PassWindowCmd 1;
BA_ "U_C519_MY18_5_Diesel_Tx" SG_ 831 PassWindowCmd 1;
BA_ "U_B515_MCA_MY17_Gas_Tx" SG_ 831 PassWindowCmd 1;
BA_ "U_B515_MCA_MY17_Diesel_Tx" SG_ 831 PassWindowCmd 1;
BA_ "U_B479_MY17_Diesel_Tx" SG_ 831 PassWindowCmd 1;
BA_ "U_B479_MY17_Gas_Tx" SG_ 831 PassWindowCmd 1;
BA_ "U_P702_MY2021_Rx" SG_ 831 PassWindowCmd 1;
BA_ "U_CX430_MY2021_Rx" SG_ 831 PassWindowCmd 1;
BA_ "U_U611_U625_MY20_Phev_Rx" SG_ 831 PassWindowCmd 1;
BA_ "U_CX482_CX483_MY20_Rx" SG_ 831 PassWindowCmd 1;
BA_ "U_U611_U625_MY20_Hev_Rx" SG_ 831 PassWindowCmd 1;
BA_ "U_U611_U625_MY20_Gas_Rx" SG_ 831 PassWindowCmd 1;
BA_ "U_C490_MY18_Rx" SG_ 831 PassWindowCmd 1;
BA_ "U_C519_MY18_5_Gas_Rx" SG_ 831 PassWindowCmd 1;
BA_ "U_C519_MY18_5_Diesel_Rx" SG_ 831 PassWindowCmd 1;
BA_ "U_B515_MCA_MY17_Gas_Rx" SG_ 831 PassWindowCmd 1;
BA_ "U_B515_MCA_MY17_Diesel_Rx" SG_ 831 PassWindowCmd 1;
BA_ "U_B479_MY17_Diesel_Rx" SG_ 831 PassWindowCmd 1;
BA_ "U_B479_MY17_Gas_Rx" SG_ 831 PassWindowCmd 1;
BA_ "GenSigSendType" SG_ 831 PassWindowCmd 3;
BA_ "WakeupSignal" SG_ 831 PassWindowCmd 1;
BA_ "U_P702_MY2021_Tx" SG_ 831 PassMirrorCmd 1;
BA_ "U_CX727_MY2021_Tx" SG_ 831 PassMirrorCmd 1;
BA_ "U_CX430_MY2021_Tx" SG_ 831 PassMirrorCmd 1;
BA_ "U_U611_U625_MY20_Phev_Tx" SG_ 831 PassMirrorCmd 1;
BA_ "U_CX482_CX483_MY20_Tx" SG_ 831 PassMirrorCmd 1;
BA_ "U_U611_U625_MY20_Hev_Tx" SG_ 831 PassMirrorCmd 1;
BA_ "U_U611_U625_MY20_Gas_Tx" SG_ 831 PassMirrorCmd 1;
BA_ "U_C490_MY18_Tx" SG_ 831 PassMirrorCmd 1;
BA_ "U_C519_MY18_5_Gas_Tx" SG_ 831 PassMirrorCmd 1;
BA_ "U_C519_MY18_5_Diesel_Tx" SG_ 831 PassMirrorCmd 1;
BA_ "U_B515_MCA_MY17_Gas_Tx" SG_ 831 PassMirrorCmd 1;
BA_ "U_B515_MCA_MY17_Diesel_Tx" SG_ 831 PassMirrorCmd 1;
BA_ "U_B479_MY17_Diesel_Tx" SG_ 831 PassMirrorCmd 1;
BA_ "U_B479_MY17_Gas_Tx" SG_ 831 PassMirrorCmd 1;
BA_ "U_P702_MY2021_Rx" SG_ 831 PassMirrorCmd 1;
BA_ "U_CX430_MY2021_Rx" SG_ 831 PassMirrorCmd 1;
BA_ "U_U611_U625_MY20_Phev_Rx" SG_ 831 PassMirrorCmd 1;
BA_ "U_CX482_CX483_MY20_Rx" SG_ 831 PassMirrorCmd 1;
BA_ "U_U611_U625_MY20_Hev_Rx" SG_ 831 PassMirrorCmd 1;
BA_ "U_U611_U625_MY20_Gas_Rx" SG_ 831 PassMirrorCmd 1;
BA_ "U_C490_MY18_Rx" SG_ 831 PassMirrorCmd 1;
BA_ "U_C519_MY18_5_Gas_Rx" SG_ 831 PassMirrorCmd 1;
BA_ "U_C519_MY18_5_Diesel_Rx" SG_ 831 PassMirrorCmd 1;
BA_ "U_B515_MCA_MY17_Gas_Rx" SG_ 831 PassMirrorCmd 1;
BA_ "U_B515_MCA_MY17_Diesel_Rx" SG_ 831 PassMirrorCmd 1;
BA_ "U_B479_MY17_Diesel_Rx" SG_ 831 PassMirrorCmd 1;
BA_ "U_B479_MY17_Gas_Rx" SG_ 831 PassMirrorCmd 1;
BA_ "GenSigSendType" SG_ 831 PassMirrorCmd 3;
BA_ "WakeupSignal" SG_ 831 PassMirrorCmd 1;
BA_ "U_P702_MY2021_Tx" SG_ 831 DipMirrorPosPassenger 1;
BA_ "U_CX727_MY2021_Tx" SG_ 831 DipMirrorPosPassenger 1;
BA_ "U_CX430_MY2021_Tx" SG_ 831 DipMirrorPosPassenger 1;
BA_ "U_U611_U625_MY20_Phev_Tx" SG_ 831 DipMirrorPosPassenger 1;
BA_ "U_CX482_CX483_MY20_Tx" SG_ 831 DipMirrorPosPassenger 1;
BA_ "U_U611_U625_MY20_Hev_Tx" SG_ 831 DipMirrorPosPassenger 1;
BA_ "U_U611_U625_MY20_Gas_Tx" SG_ 831 DipMirrorPosPassenger 1;
BA_ "U_C490_MY18_Tx" SG_ 831 DipMirrorPosPassenger 1;
BA_ "U_C519_MY18_5_Gas_Tx" SG_ 831 DipMirrorPosPassenger 1;
BA_ "U_C519_MY18_5_Diesel_Tx" SG_ 831 DipMirrorPosPassenger 1;
BA_ "U_B515_MCA_MY17_Gas_Tx" SG_ 831 DipMirrorPosPassenger 1;
BA_ "U_B515_MCA_MY17_Diesel_Tx" SG_ 831 DipMirrorPosPassenger 1;
BA_ "U_B479_MY17_Diesel_Tx" SG_ 831 DipMirrorPosPassenger 1;
BA_ "U_B479_MY17_Gas_Tx" SG_ 831 DipMirrorPosPassenger 1;
BA_ "U_P702_MY2021_Rx" SG_ 831 DipMirrorPosPassenger 1;
BA_ "U_CX430_MY2021_Rx" SG_ 831 DipMirrorPosPassenger 1;
BA_ "U_U611_U625_MY20_Phev_Rx" SG_ 831 DipMirrorPosPassenger 1;
BA_ "U_CX482_CX483_MY20_Rx" SG_ 831 DipMirrorPosPassenger 1;
BA_ "U_U611_U625_MY20_Hev_Rx" SG_ 831 DipMirrorPosPassenger 1;
BA_ "U_U611_U625_MY20_Gas_Rx" SG_ 831 DipMirrorPosPassenger 1;
BA_ "U_C490_MY18_Rx" SG_ 831 DipMirrorPosPassenger 1;
BA_ "U_C519_MY18_5_Gas_Rx" SG_ 831 DipMirrorPosPassenger 1;
BA_ "U_C519_MY18_5_Diesel_Rx" SG_ 831 DipMirrorPosPassenger 1;
BA_ "U_B515_MCA_MY17_Gas_Rx" SG_ 831 DipMirrorPosPassenger 1;
BA_ "U_B515_MCA_MY17_Diesel_Rx" SG_ 831 DipMirrorPosPassenger 1;
BA_ "GenSigSendType" SG_ 831 DipMirrorPosPassenger 3;
BA_ "U_P702_MY2021_Tx" SG_ 831 ActiveStoragePassenger 1;
BA_ "U_CX727_MY2021_Tx" SG_ 831 ActiveStoragePassenger 1;
BA_ "U_CX430_MY2021_Tx" SG_ 831 ActiveStoragePassenger 1;
BA_ "U_U611_U625_MY20_Phev_Tx" SG_ 831 ActiveStoragePassenger 1;
BA_ "U_CX482_CX483_MY20_Tx" SG_ 831 ActiveStoragePassenger 1;
BA_ "U_U611_U625_MY20_Hev_Tx" SG_ 831 ActiveStoragePassenger 1;
BA_ "U_U611_U625_MY20_Gas_Tx" SG_ 831 ActiveStoragePassenger 1;
BA_ "U_C490_MY18_Tx" SG_ 831 ActiveStoragePassenger 1;
BA_ "U_C519_MY18_5_Gas_Tx" SG_ 831 ActiveStoragePassenger 1;
BA_ "U_C519_MY18_5_Diesel_Tx" SG_ 831 ActiveStoragePassenger 1;
BA_ "U_B515_MCA_MY17_Gas_Tx" SG_ 831 ActiveStoragePassenger 1;
BA_ "U_B515_MCA_MY17_Diesel_Tx" SG_ 831 ActiveStoragePassenger 1;
BA_ "U_B479_MY17_Diesel_Tx" SG_ 831 ActiveStoragePassenger 1;
BA_ "U_B479_MY17_Gas_Tx" SG_ 831 ActiveStoragePassenger 1;
BA_ "U_P702_MY2021_Rx" SG_ 831 ActiveStoragePassenger 1;
BA_ "U_CX430_MY2021_Rx" SG_ 831 ActiveStoragePassenger 1;
BA_ "U_U611_U625_MY20_Phev_Rx" SG_ 831 ActiveStoragePassenger 1;
BA_ "U_CX482_CX483_MY20_Rx" SG_ 831 ActiveStoragePassenger 1;
BA_ "U_U611_U625_MY20_Hev_Rx" SG_ 831 ActiveStoragePassenger 1;
BA_ "U_U611_U625_MY20_Gas_Rx" SG_ 831 ActiveStoragePassenger 1;
BA_ "U_C490_MY18_Rx" SG_ 831 ActiveStoragePassenger 1;
BA_ "U_C519_MY18_5_Gas_Rx" SG_ 831 ActiveStoragePassenger 1;
BA_ "U_C519_MY18_5_Diesel_Rx" SG_ 831 ActiveStoragePassenger 1;
BA_ "U_B515_MCA_MY17_Gas_Rx" SG_ 831 ActiveStoragePassenger 1;
BA_ "U_B515_MCA_MY17_Diesel_Rx" SG_ 831 ActiveStoragePassenger 1;
BA_ "U_B479_MY17_Diesel_Rx" SG_ 831 ActiveStoragePassenger 1;
BA_ "U_B479_MY17_Gas_Rx" SG_ 831 ActiveStoragePassenger 1;
BA_ "GenSigSendType" SG_ 831 ActiveStoragePassenger 3;
BA_ "U_P702_MY2021_Tx" SG_ 831 RearDriverWindowPos 1;
BA_ "U_CX727_MY2021_Tx" SG_ 831 RearDriverWindowPos 1;
BA_ "U_CX430_MY2021_Tx" SG_ 831 RearDriverWindowPos 1;
BA_ "U_U611_U625_MY20_Phev_Tx" SG_ 831 RearDriverWindowPos 1;
BA_ "U_CX482_CX483_MY20_Tx" SG_ 831 RearDriverWindowPos 1;
BA_ "U_U611_U625_MY20_Hev_Tx" SG_ 831 RearDriverWindowPos 1;
BA_ "U_U611_U625_MY20_Gas_Tx" SG_ 831 RearDriverWindowPos 1;
BA_ "U_C490_MY18_Tx" SG_ 831 RearDriverWindowPos 1;
BA_ "U_C519_MY18_5_Gas_Tx" SG_ 831 RearDriverWindowPos 1;
BA_ "U_C519_MY18_5_Diesel_Tx" SG_ 831 RearDriverWindowPos 1;
BA_ "U_B515_MCA_MY17_Gas_Tx" SG_ 831 RearDriverWindowPos 1;
BA_ "U_B515_MCA_MY17_Diesel_Tx" SG_ 831 RearDriverWindowPos 1;
BA_ "U_B479_MY17_Diesel_Tx" SG_ 831 RearDriverWindowPos 1;
BA_ "U_B479_MY17_Gas_Tx" SG_ 831 RearDriverWindowPos 1;
BA_ "U_P702_MY2021_Rx" SG_ 831 RearDriverWindowPos 1;
BA_ "U_CX727_MY2021_Rx" SG_ 831 RearDriverWindowPos 1;
BA_ "U_CX430_MY2021_Rx" SG_ 831 RearDriverWindowPos 1;
BA_ "U_U611_U625_MY20_Phev_Rx" SG_ 831 RearDriverWindowPos 1;
BA_ "U_CX482_CX483_MY20_Rx" SG_ 831 RearDriverWindowPos 1;
BA_ "U_U611_U625_MY20_Hev_Rx" SG_ 831 RearDriverWindowPos 1;
BA_ "U_U611_U625_MY20_Gas_Rx" SG_ 831 RearDriverWindowPos 1;
BA_ "U_B500_MY18_Diesel_Rx" SG_ 831 RearDriverWindowPos 1;
BA_ "U_B500_MY18_Gas_Rx" SG_ 831 RearDriverWindowPos 1;
BA_ "U_C490_MY18_Rx" SG_ 831 RearDriverWindowPos 1;
BA_ "U_C519_MY18_5_Gas_Rx" SG_ 831 RearDriverWindowPos 1;
BA_ "U_C519_MY18_5_Diesel_Rx" SG_ 831 RearDriverWindowPos 1;
BA_ "U_B515_MCA_MY17_Gas_Rx" SG_ 831 RearDriverWindowPos 1;
BA_ "U_B515_MCA_MY17_Diesel_Rx" SG_ 831 RearDriverWindowPos 1;
BA_ "U_B479_MY17_Diesel_Rx" SG_ 831 RearDriverWindowPos 1;
BA_ "U_B479_MY17_Gas_Rx" SG_ 831 RearDriverWindowPos 1;
BA_ "GenSigSendType" SG_ 831 RearDriverWindowPos 3;
BA_ "WakeupSignal" SG_ 831 RearDriverWindowPos 1;
BA_ "U_P702_MY2021_Tx" SG_ 831 DriverWindowPosition 1;
BA_ "U_CX727_MY2021_Tx" SG_ 831 DriverWindowPosition 1;
BA_ "U_CX430_MY2021_Tx" SG_ 831 DriverWindowPosition 1;
BA_ "U_U611_U625_MY20_Phev_Tx" SG_ 831 DriverWindowPosition 1;
BA_ "U_CX482_CX483_MY20_Tx" SG_ 831 DriverWindowPosition 1;
BA_ "U_U611_U625_MY20_Hev_Tx" SG_ 831 DriverWindowPosition 1;
BA_ "U_U611_U625_MY20_Gas_Tx" SG_ 831 DriverWindowPosition 1;
BA_ "U_C490_MY18_Tx" SG_ 831 DriverWindowPosition 1;
BA_ "U_C519_MY18_5_Gas_Tx" SG_ 831 DriverWindowPosition 1;
BA_ "U_C519_MY18_5_Diesel_Tx" SG_ 831 DriverWindowPosition 1;
BA_ "U_B515_MCA_MY17_Gas_Tx" SG_ 831 DriverWindowPosition 1;
BA_ "U_B515_MCA_MY17_Diesel_Tx" SG_ 831 DriverWindowPosition 1;
BA_ "U_B479_MY17_Diesel_Tx" SG_ 831 DriverWindowPosition 1;
BA_ "U_B479_MY17_Gas_Tx" SG_ 831 DriverWindowPosition 1;
BA_ "U_P702_MY2021_Rx" SG_ 831 DriverWindowPosition 1;
BA_ "U_CX727_MY2021_Rx" SG_ 831 DriverWindowPosition 1;
BA_ "U_CX430_MY2021_Rx" SG_ 831 DriverWindowPosition 1;
BA_ "U_U611_U625_MY20_Phev_Rx" SG_ 831 DriverWindowPosition 1;
BA_ "U_CX482_CX483_MY20_Rx" SG_ 831 DriverWindowPosition 1;
BA_ "U_U611_U625_MY20_Hev_Rx" SG_ 831 DriverWindowPosition 1;
BA_ "U_U611_U625_MY20_Gas_Rx" SG_ 831 DriverWindowPosition 1;
BA_ "U_B500_MY18_Diesel_Rx" SG_ 831 DriverWindowPosition 1;
BA_ "U_B500_MY18_Gas_Rx" SG_ 831 DriverWindowPosition 1;
BA_ "U_C490_MY18_Rx" SG_ 831 DriverWindowPosition 1;
BA_ "U_C519_MY18_5_Gas_Rx" SG_ 831 DriverWindowPosition 1;
BA_ "U_C519_MY18_5_Diesel_Rx" SG_ 831 DriverWindowPosition 1;
BA_ "U_B515_MCA_MY17_Gas_Rx" SG_ 831 DriverWindowPosition 1;
BA_ "U_B515_MCA_MY17_Diesel_Rx" SG_ 831 DriverWindowPosition 1;
BA_ "U_B479_MY17_Diesel_Rx" SG_ 831 DriverWindowPosition 1;
BA_ "U_B479_MY17_Gas_Rx" SG_ 831 DriverWindowPosition 1;
BA_ "GenSigSendType" SG_ 831 DriverWindowPosition 3;
BA_ "WakeupSignal" SG_ 831 DriverWindowPosition 1;
BA_ "U_CX727_MY2021_Tx" SG_ 787 DrTgateChime2_D_Rq 1;
BA_ "U_U611_U625_MY20_Phev_Tx" SG_ 787 DrTgateChime2_D_Rq 1;
BA_ "U_CX482_CX483_MY20_Tx" SG_ 787 DrTgateChime2_D_Rq 1;
BA_ "U_U611_U625_MY20_Hev_Tx" SG_ 787 DrTgateChime2_D_Rq 1;
BA_ "U_U611_U625_MY20_Gas_Tx" SG_ 787 DrTgateChime2_D_Rq 1;
BA_ "U_C519_MY18_5_Gas_Tx" SG_ 787 DrTgateChime2_D_Rq 1;
BA_ "U_C519_MY18_5_Diesel_Tx" SG_ 787 DrTgateChime2_D_Rq 1;
BA_ "GenSigSendType" SG_ 787 DrTgateChime2_D_Rq 3;
BA_ "WakeupSignal" SG_ 787 DrTgateChime2_D_Rq 1;
BA_ "U_CX727_MY2021_Tx" SG_ 787 DrTGate_D_Rq 1;
BA_ "U_U611_U625_MY20_Phev_Tx" SG_ 787 DrTGate_D_Rq 1;
BA_ "U_CX482_CX483_MY20_Tx" SG_ 787 DrTGate_D_Rq 1;
BA_ "U_U611_U625_MY20_Hev_Tx" SG_ 787 DrTGate_D_Rq 1;
BA_ "U_U611_U625_MY20_Gas_Tx" SG_ 787 DrTGate_D_Rq 1;
BA_ "U_C519_MY18_5_Gas_Tx" SG_ 787 DrTGate_D_Rq 1;
BA_ "U_C519_MY18_5_Diesel_Tx" SG_ 787 DrTGate_D_Rq 1;
BA_ "U_CX727_MY2021_Rx" SG_ 787 DrTGate_D_Rq 1;
BA_ "U_U611_U625_MY20_Phev_Rx" SG_ 787 DrTGate_D_Rq 1;
BA_ "U_CX482_CX483_MY20_Rx" SG_ 787 DrTGate_D_Rq 1;
BA_ "U_U611_U625_MY20_Hev_Rx" SG_ 787 DrTGate_D_Rq 1;
BA_ "U_U611_U625_MY20_Gas_Rx" SG_ 787 DrTGate_D_Rq 1;
BA_ "GenSigSendType" SG_ 787 DrTGate_D_Rq 3;
BA_ "WakeupSignal" SG_ 787 DrTGate_D_Rq 1;
BA_ "U_CX727_MY2021_Tx" SG_ 787 PwLftgtIntSw_B_Stat 1;
BA_ "U_U611_U625_MY20_Phev_Tx" SG_ 787 PwLftgtIntSw_B_Stat 1;
BA_ "U_CX482_CX483_MY20_Tx" SG_ 787 PwLftgtIntSw_B_Stat 1;
BA_ "U_U611_U625_MY20_Hev_Tx" SG_ 787 PwLftgtIntSw_B_Stat 1;
BA_ "U_U611_U625_MY20_Gas_Tx" SG_ 787 PwLftgtIntSw_B_Stat 1;
BA_ "U_C519_MY18_5_Gas_Tx" SG_ 787 PwLftgtIntSw_B_Stat 1;
BA_ "U_C519_MY18_5_Diesel_Tx" SG_ 787 PwLftgtIntSw_B_Stat 1;
BA_ "GenSigSendType" SG_ 787 PwLftgtIntSw_B_Stat 3;
BA_ "WakeupSignal" SG_ 787 PwLftgtIntSw_B_Stat 1;
BA_ "U_CX727_MY2021_Tx" SG_ 787 Power_Liftgate_Mode_Stt 1;
BA_ "U_U611_U625_MY20_Phev_Tx" SG_ 787 Power_Liftgate_Mode_Stt 1;
BA_ "U_CX482_CX483_MY20_Tx" SG_ 787 Power_Liftgate_Mode_Stt 1;
BA_ "U_U611_U625_MY20_Hev_Tx" SG_ 787 Power_Liftgate_Mode_Stt 1;
BA_ "U_U611_U625_MY20_Gas_Tx" SG_ 787 Power_Liftgate_Mode_Stt 1;
BA_ "U_C519_MY18_5_Gas_Tx" SG_ 787 Power_Liftgate_Mode_Stt 1;
BA_ "U_C519_MY18_5_Diesel_Tx" SG_ 787 Power_Liftgate_Mode_Stt 1;
BA_ "GenSigSendType" SG_ 787 Power_Liftgate_Mode_Stt 3;
BA_ "CrossOver_InfoCAN" SG_ 787 Power_Liftgate_Mode_Stt 1;
BA_ "U_P702_MY2021_Tx" SG_ 1291 DSM_Network_Mgmt 1;
BA_ "U_CX727_MY2021_Tx" SG_ 1291 DSM_Network_Mgmt 1;
BA_ "U_CX430_MY2021_Tx" SG_ 1291 DSM_Network_Mgmt 1;
BA_ "U_CX482_CX483_MY20_Tx" SG_ 1291 DSM_Network_Mgmt 1;
BA_ "U_C490_MY18_Tx" SG_ 1291 DSM_Network_Mgmt 1;
BA_ "U_P702_MY2021_Rx" SG_ 1291 DSM_Network_Mgmt 1;
BA_ "U_CX430_MY2021_Rx" SG_ 1291 DSM_Network_Mgmt 1;
BA_ "U_U611_U625_MY20_Phev_Rx" SG_ 1291 DSM_Network_Mgmt 1;
BA_ "U_CX482_CX483_MY20_Rx" SG_ 1291 DSM_Network_Mgmt 1;
BA_ "U_U611_U625_MY20_Hev_Rx" SG_ 1291 DSM_Network_Mgmt 1;
BA_ "U_U611_U625_MY20_Gas_Rx" SG_ 1291 DSM_Network_Mgmt 1;
BA_ "U_C490_MY18_Rx" SG_ 1291 DSM_Network_Mgmt 1;
BA_ "GenSigSendType" SG_ 1291 DSM_Network_Mgmt 3;
VAL_ 947 DrStatDrvErrCnt_B_Stat 1 "Yes" 0 "No" ;
VAL_ 947 TurnLghtRightOn_B_Stat 1 "On" 0 "Off" ;
VAL_ 947 TurnLghtLeftOn_B_Stat 1 "On" 0 "Off" ;
VAL_ 947 Backlit_LED_Status 15 "Unused3" 14 "Unused2" 13 "Unused1" 12 "Night_12" 11 "Night_11" 10 "Night_10" 9 "Night_9" 8 "Night_8" 7 "Night_7" 6 "Night_6" 5 "Night_5" 4 "Night_4" 3 "Night_3" 2 "Night_2" 1 "Night_1" 0 "Off" ;
VAL_ 947 FogLghtRearOn_B_Stat 1 "On" 0 "Off" ;
VAL_ 947 ValetMode_D_Mem 1 "On" 0 "Off" ;
VAL_ 947 IgnKeyType_D_Actl 15 "Invalid" 14 "Unknown" 3 "Key_Not_Prgrm_Read_Failure" 2 "Key_In_Ign_My_Key" 1 "Key_In_Ign_Standard_Key" 0 "Key_Read_In_Progress" ;
VAL_ 947 TurnLghtRight_D_Rq 3 "Seq" 2 "On" 1 "Off" 0 "Null" ;
VAL_ 947 Parklamp_Status 3 "Invalid" 2 "Unknown" 1 "On" 0 "Off" ;
VAL_ 947 Litval 255 "Invalid" 254 "Unknown" 5 "Day" 4 "Twilight_4" 3 "Twilight_3" 2 "Twilight_2" 1 "Twilight_1" 0 "Night" ;
VAL_ 947 Key_In_Ignition_Stat 1 "In" 0 "Out" ;
VAL_ 947 Ignition_Status 0 "Unknown" 1 "Off" 15 "Invalid" 8 "Start" 4 "Run" 2 "Accessory" ;
VAL_ 947 Dimming_Lvl 255 "Invalid" 254 "Unknown" 18 "Day_6" 17 "Day_5" 16 "Day_4" 15 "Day_3" 14 "Day_2" 13 "Day_1" 12 "Night_12" 11 "Night_11" 10 "Night_10" 9 "Night_9" 8 "Night_8" 7 "Night_7" 6 "Night_6" 5 "Night_5" 4 "Night_4" 3 "Night_3" 2 "Night_2" 1 "Night_1" 0 "Off" ;
VAL_ 947 Day_Night_Status 3 "NotUsed" 2 "Night" 1 "Day" 0 "Null" ;
VAL_ 947 Remote_Start_Status 3 "Invalid" 2 "Unknown" 1 "Remote" 0 "Null" ;
VAL_ 947 DrStatTgate_B_Actl 1 "Ajar" 0 "Closed" ;
VAL_ 947 DrStatRr_B_Actl 1 "Ajar" 0 "Closed" ;
VAL_ 947 DrStatRl_B_Actl 1 "Ajar" 0 "Closed" ;
VAL_ 947 DrStatPsngr_B_Actl 1 "Ajar" 0 "Closed" ;
VAL_ 947 DrStatInnrTgate_B_Actl 1 "Ajar" 0 "Closed" ;
VAL_ 947 DrStatHood_B_Actl 1 "Ajar" 0 "Closed" ;
VAL_ 947 DrStatDrv_B_Actl 1 "Ajar" 0 "Closed" ;
VAL_ 947 PrkBrkActv_B_Actl 1 "Active" 0 "Inactive" ;
VAL_ 947 LifeCycMde_D_Actl 3 "Transport" 2 "NotUsed" 1 "Factory" 0 "Normal" ;
VAL_ 947 Delay_Accy 1 "On" 0 "Off" ;
VAL_ 947 FogLghtFrontOn_B_Stat 1 "On" 0 "Off" ;
VAL_ 947 TurnLghtLeft_D_Rq 3 "Seq" 2 "On" 1 "Off" 0 "Null" ;
VAL_ 947 CrashEvnt_D_Stat 3 "Invalid" 2 "Fuel_Cutoff_Event" 1 "Deploy_Event" 0 "No_Event" ;
VAL_ 947 FuelPmpInhbt_B_Stat 1 "Inhibit" 0 "No_Inibit" ;
VAL_ 947 BodySrvcRqd_B_Rq 1 "Yes" 0 "No" ;
VAL_ 293 ClmtCtrlSeat_SetStat_Psgr 128 "H3_High_Heat__MAX" 64 "H2_Medium_Heat" 32 "H1_Low_Heat" 16 "C3_High_Cool__MAX" 8 "C2_Medium_Cool" 4 "C1_Low_Cool" 2 "Off" ;
VAL_ 293 ClmtCtrlSeat_SetStat_Dvr 128 "H3_High_Heat__MAX" 64 "H2_Medium_Heat" 32 "H1_Low_Heat" 16 "C3_High_Cool__MAX" 8 "C2_Medium_Cool" 4 "C1_Low_Cool" 2 "Off" ;
VAL_ 292 ClmtCtrlSeat_SetCmd_Psgr 128 "H3_High_Heat__MAX" 64 "H2_Medium_Heat" 32 "H1_Low_Heat" 16 "C3_High_Cool__MAX" 8 "C2_Medium_Cool" 4 "C1_Low_Cool" 2 "Off" ;
VAL_ 292 ClmtCtrlSeat_SetCmd_Dvr 128 "H3_High_Heat__MAX" 64 "H2_Medium_Heat" 32 "H1_Low_Heat" 16 "C3_High_Cool__MAX" 8 "C2_Medium_Cool" 4 "C1_Low_Cool" 2 "Off" ;
VAL_ 1126 GpsUtcYr_No_Actl 31 "Fault" ;
VAL_ 1126 GpsUtcMnth_No_Actl 15 "Fault" ;
VAL_ 1126 GPS_UTC_seconds 63 "Fault" 62 "Unknown" ;
VAL_ 1126 GPS_UTC_minutes 63 "Fault" 62 "Unknown" ;
VAL_ 1126 GPS_UTC_hours 31 "Invalid" 30 "Unknown" ;
VAL_ 1126 GPS_Pdop 31 "Invalid" 30 "Unknown" ;
VAL_ 1126 GPS_Compass_direction 7 "NorthWest" 6 "West" 5 "SouthWest" 4 "South" 3 "SouthEast" 2 "East" 1 "NorthEast" 0 "North" ;
VAL_ 1126 GPS_Actual_vs_Infer_pos 1 "Inferred_Position" 0 "Actual_Postition" ;
VAL_ 1126 Gps_B_Falt 1 "Yes" 0 "No" ;
VAL_ 1125 GpsHsphLongEast_D_Actl 0 "Invalid" 1 "Eastern" 2 "Western" 3 "Fault" ;
VAL_ 1125 GpsHsphLattSth_D_Actl 3 "Fault" 2 "Northern" 1 "Southern" 0 "Invalid" ;
VAL_ 1125 GPS_Longitude_Minutes 63 "Fault" 62 "Unknown" ;
VAL_ 1125 GPS_Longitude_Min_dec 16383 "Invalid" 16382 "Unknown" ;
VAL_ 1125 GPS_Longitude_Degrees 511 "Fault" 510 "Unknown" ;
VAL_ 1125 GPS_Latitude_Minutes 63 "Fault" 62 "Unknown" ;
VAL_ 1125 GPS_Latitude_Min_dec 16383 "Invalid" 16382 "Unknown" ;
VAL_ 1125 GPS_Latitude_Degrees 255 "Invalid" 254 "Unknown" ;
VAL_ 992 MsgCntrDsplyOp_D_Rq 7 "Unused_2" 6 "Unused_1" 5 "Copy" 4 "Restore" 3 "Upload" 2 "Set" 1 "Query" 0 "Null" ;
VAL_ 992 MsgCntrPersIndex_D_Rq 7 "Unused_3" 6 "Unused_2" 5 "Unused_1" 4 "Vehicle" 3 "PERS_4" 2 "PERS_3" 1 "PERS_2" 0 "PERS_1" ;
VAL_ 1127 GPS_Vdop 31 "Invalid" 30 "Unknown" ;
VAL_ 1127 GPS_Speed 255 "Invalid" 254 "Unknown" ;
VAL_ 1127 GPS_Sat_num_in_view 31 "Invalid" 30 "Unknown" ;
VAL_ 1127 GPS_MSL_altitude 4095 "Fault" 4094 "Unknown" ;
VAL_ 1127 GPS_Heading 65535 "Fault" 65534 "Unknown" ;
VAL_ 1127 GPS_Hdop 31 "Invalid" 30 "Unknown" ;
VAL_ 1127 GPS_dimension 2 "_3D" 1 "_2D" 0 "No_Fix" ;
VAL_ 999 PersIndexFcim_D_Actl 7 "Unused_3" 6 "Unused_2" 5 "Unused_1" 4 "Vehicle" 3 "PERS_4" 2 "PERS_3" 1 "PERS_2" 0 "PERS_1" ;
VAL_ 847 FldngSeatPwOffOk_B_Stat 1 "Yes" 0 "No" ;
VAL_ 862 HvacBlwrFront_D_Stat 31 "Not_Used" 20 "Full_On" 19 "95_Percent" 18 "90_Percent" 17 "85_Percent" 16 "80_Percent" 15 "75_Percent" 14 "70_Percent" 13 "65_Percent" 12 "60_Percent" 11 "55_Percent" 10 "50_Percent" 9 "45_Percent" 8 "40_Percent" 7 "35_Percent" 6 "30_Percent" 5 "25_Percent" 4 "20_Percent" 3 "15_Percent" 2 "10_Percent" 1 "5_Percent" 0 "Off" ;
VAL_ 862 ClimtThrmlLoad_No_Actl 255 "Fault" ;
VAL_ 862 CamraDefog_B_Actl 1 "On" 0 "Off" ;
VAL_ 862 CabnAmb_Te_Actl 255 "Fault" ;
VAL_ 862 AutoStpHvacDelta_I_Est 255 "Fault" ;
VAL_ 828 RearPassWindowPos 7 "Unused2" 6 "Unused1" 5 "Fully_Open" 4 "Bet60Percent_FullyOpen" 3 "Bet10Percent_60Percent" 2 "BetFully_10PercentOpen" 1 "Fully_Closed" 0 "Undefined" ;
VAL_ 828 PassWindowPosition 7 "Unused2" 6 "Unused1" 5 "Fully_Open" 4 "Bet60Percent_FullyOpen" 3 "Bet10Percent_60Percent" 2 "BetFully_10PercentOpen" 1 "Fully_Closed" 0 "Undefined" ;
VAL_ 826 Memory_3_Sw_Stat 1 "Pressed" 0 "Null" ;
VAL_ 826 Memory_2_Sw_Stat 1 "Pressed" 0 "Null" ;
VAL_ 826 Memory_1_Sw_Stat 1 "Pressed" 0 "Null" ;
VAL_ 826 Mirror_Manual_Override 1 "Override" 0 "Null" ;
VAL_ 853 Front_AUTO_Blwr_Lvl 3 "High" 2 "Medium" 1 "Low" 0 "Off" ;
VAL_ 853 FrontMnu_Buttn_Stat 1 "Pressed" 0 "Not_Pressed" ;
VAL_ 853 RHS_Cond_Seat_Status 7 "Unused" 6 "Level_3_Heating" 5 "Level_2_Heating" 4 "Level_1_Heating" 3 "Level_3_Cooling" 2 "Level_2_Cooling" 1 "Level_1_Cooling" 0 "Off" ;
VAL_ 853 LHS_Cond_Seat_Status 7 "Unused" 6 "Level_3_Heating" 5 "Level_2_Heating" 4 "Level_1_Heating" 3 "Level_3_Cooling" 2 "Level_2_Cooling" 1 "Level_1_Cooling" 0 "Off" ;
VAL_ 853 Htd_Strg_Whl_Status 3 "Level_3_Heating" 2 "Level_2_Heating" 1 "Level_1_Heating" 0 "Off" ;
VAL_ 853 Htd_Strg_Whl_Btn_Stt 3 "Unused" 2 "Disabled" 1 "Active" 0 "Enabled_Inactive" ;
VAL_ 853 Defrost_Btn_Stt 3 "Unused" 2 "Disabled" 1 "Active" 0 "Enabled_Inactive" ;
VAL_ 853 CC_Fr_Btn_User_Adj 31 "Unused15" 30 "Unused14" 29 "Unused13" 28 "Unused12" 27 "Unused11" 26 "Unused10" 25 "Unused9" 24 "Unused8" 23 "Unused7" 22 "Unused6" 21 "Unused5" 20 "Unused4" 19 "UFC_Interrupted" 18 "UFC_Complete" 17 "UFC_Active" 16 "Htd_WS_Selection" 15 "FLR_Cnd_St_Selection" 14 "FLH_Cnd_St_Selection" 13 "HSW_Selection" 12 "Dual_Selection" 11 "Rear_Defrost_Selection" 10 "Max_Defrost_Selection" 9 "Defrost_Selection" 8 "Fr_Air_Dist_Selection" 7 "Max_AC_Selection" 6 "Fr_Power_Selection" 5 "Recirc_Selection" 4 "AC_Selection" 3 "Fr_Auto_Selection" 2 "Use_MyTemp_Selection" 1 "Save_MyTemp_Selection" 0 "None" ;
VAL_ 853 RHS_Htd_Seat_Btn_Stt 3 "Unused" 2 "Disabled" 1 "Active" 0 "Enabled_Inactive" ;
VAL_ 853 RHS_Cld_Seat_Btn_Stt 3 "Unused" 2 "Disabled" 1 "Active" 0 "Enabled_Inactive" ;
VAL_ 853 Outside_Btn_Stt 3 "Unused" 2 "Disabled" 1 "Active" 0 "Enabled_Inactive" ;
VAL_ 853 LHS_Htd_Seat_Btn_Stt 3 "Unused" 2 "Disabled" 1 "Active" 0 "Enabled_Inactive" ;
VAL_ 853 LHS_Cld_Seat_Btn_Stt 3 "Unused" 2 "Disabled" 1 "Active" 0 "Enabled_Inactive" ;
VAL_ 853 Htd_Frt_Wsh_Btn_Stt 3 "Unused" 2 "Disabled" 1 "Active" 0 "Enabled_Inactive" ;
VAL_ 853 Auto_Recirc_Btn_Stt 3 "Unused" 2 "Disabled" 1 "Active" 0 "Enabled_Inactive" ;
VAL_ 853 Windscreen_Btn_Stt 3 "Unused" 2 "Disabled" 1 "Active" 0 "Enabled_Inactive" ;
VAL_ 853 Panel_Btn_Stt 3 "Unused" 2 "Disabled" 1 "Active" 0 "Enabled_Inactive" ;
VAL_ 853 Front_Power_Btn_Stt 3 "Unused" 2 "Disabled" 1 "Active" 0 "Enabled_Inactive" ;
VAL_ 853 Front_AUTO_Btn_Stt 3 "Unused" 2 "Disabled" 1 "Active" 0 "Enabled_Inactive" ;
VAL_ 853 Floor_Btn_Stt 3 "Unused" 2 "Disabled" 1 "Active" 0 "Enabled_Inactive" ;
VAL_ 853 Dual_Button_Stt 3 "Unused" 2 "Disabled" 1 "Active" 0 "Enabled_Inactive" ;
VAL_ 853 AC_Btn_Stt 3 "Unused" 2 "Disabled" 1 "Active" 0 "Enabled_Inactive" ;
VAL_ 853 Recirc_Btn_Stt 3 "Unused" 2 "Disabled" 1 "Active" 0 "Enabled_Inactive" ;
VAL_ 853 Rear_Defrost_Btn_Stt 3 "Unused" 2 "Disabled" 1 "Active" 0 "Enabled_Inactive" ;
VAL_ 853 My_Temp_Btn_Stt 3 "Unused" 2 "Disabled" 1 "Active" 0 "Enabled_Inactive" ;
VAL_ 853 Max_Defrost_Btn_Stt 3 "Unused" 2 "Disabled" 1 "Active" 0 "Enabled_Inactive" ;
VAL_ 853 Max_AC_Btn_Stt 3 "Unused" 2 "Disabled" 1 "Active" 0 "Enabled_Inactive" ;
VAL_ 853 Front_AUTO_Label 3 "Full" 2 "Mode" 1 "Blower" 0 "Off" ;
VAL_ 956 PwSrcULoFalt_D_Stat_UB 1 "Fresh_data" 0 "Unchanged_data" ;
VAL_ 956 PwSrcULo_Pc_Mx_UB 1 "Fresh_data" 0 "Unchanged_data" ;
VAL_ 956 PwSrcULo_Pc_Mx 255 "Fault" ;
VAL_ 956 WndwFrontHeat_B_Rq_UB 1 "Fresh_data" 0 "Unchanged_data" ;
VAL_ 956 SAPPStatusCoding_UB 1 "Fresh_data" 0 "Unchanged_data" ;
VAL_ 956 WndwFrontHeat_B_Rq 1 "On" 0 "Off" ;
VAL_ 956 BattTrac_Te_Actl_UB 1 "Fresh_data" 0 "Unchanged_data" ;
VAL_ 956 BattTrac_Te_Actl 1023 "Fault" 1022 "Unknown" ;
VAL_ 956 PwSrcULoFalt_D_Stat 3 "Fault_No_Output" 2 "Fault_Reduced_Output" 1 "Fault_NonSpecific" 0 "No_Fault" ;
VAL_ 956 PrkBrkStatus_UB 1 "Fresh_data" 0 "Unchanged_data" ;
VAL_ 956 ApedPos_Pc_ActlArb_UB 1 "Fresh_data" 0 "Unchanged_data" ;
VAL_ 956 GearLvrPos_D_Actl 15 "Fault" 14 "Unknown_Position" 13 "Undefined_Treat_as__Fault" 12 "Undefined_Treat_as_Fault" 11 "sixth" 10 "fifth" 9 "fourth" 8 "third" 7 "second" 6 "first" 5 "Low" 4 "Sport_DriveSport" 3 "Drive" 2 "Neutral" 1 "Reverse" 0 "Park" ;
VAL_ 956 PrkBrkStatus 7 "GeneralFault_MaintenceMode" 6 "ECD_by_Brake_ECU_Active" 5 "EPB_Limphome_Active" 4 "Rear_Caliper_Open" 3 "RWU_By_EPB_Active" 2 "Rear_Caliper_Transition" 1 "Rear_Caliper_Closed" 0 "Not_Supported" ;
VAL_ 956 GearLvrPos_D_Actl_UB 1 "Fresh_data" 0 "Unchanged_data" ;
VAL_ 831 RearPassWindowLockCmd 1 "Enable" 0 "Disable" ;
VAL_ 831 RearPassWindowCmd 7 "Unused2" 6 "Unused1" 5 "NotDefined" 4 "Audo_Down" 3 "Manual_Down" 2 "Auto_Up" 1 "Manual_Up" 0 "Idle" ;
VAL_ 831 PassWindowCmd 7 "Unused2" 6 "Unused1" 5 "NotDefined" 4 "Audo_Down" 3 "Manual_Down" 2 "Auto_Up" 1 "Manual_Up" 0 "Idle" ;
VAL_ 831 PassMirrorCmd 7 "Unused" 6 "Unfold" 5 "Fold" 4 "Right" 3 "Left" 2 "Down" 1 "Up" 0 "Idle" ;
VAL_ 831 DipMirrorPosPassenger 1 "Dipped" 0 "Off" ;
VAL_ 831 ActiveStoragePassenger 7 "Unused3" 6 "Unused2" 5 "Unused1" 4 "StoreDipMemoryButton4" 3 "StoreDipMemoryButton3" 2 "StoreDipMemoryButton2" 1 "StoreDipMemoryButton1" 0 "Off" ;
VAL_ 831 RearDriverWindowPos 7 "Unused2" 6 "Unused1" 5 "Fully_Open" 4 "Bet60Percent_FullyOpen" 3 "Bet10Percent_60Percent" 2 "BetFully_10PercentOpen" 1 "Fully_Closed" 0 "Undefined" ;
VAL_ 831 DriverWindowPosition 7 "Unused2" 6 "Unused1" 5 "Fully_Open" 4 "Bet60Percent_FullyOpen" 3 "Bet10Percent_60Percent" 2 "BetFully_10PercentOpen" 1 "Fully_Closed" 0 "Undefined" ;
VAL_ 787 DrTgateChime2_D_Rq 7 "NotUsed3" 6 "NotUsed2" 5 "NotUsed1" 4 "Long_Repeated" 3 "Fast" 2 "Short" 1 "Long" 0 "Off" ;
VAL_ 787 DrTGate_D_Rq 3 "NotUsed" 2 "Closing" 1 "Opening" 0 "Not_Moving" ;
VAL_ 787 PwLftgtIntSw_B_Stat 1 "Pressed" 0 "Null" ;
VAL_ 787 Power_Liftgate_Mode_Stt 2 "Unused" 3 "Not_Supported" 1 "Enabled" 0 "Disabled" ;
